VERSION ""

NS_ :

BS_:

BU_: CH DIPF DIPR ETH FC HVI HVS PARTY SDCV VEH VIRT

BO_ 1356 SCM_alertLog: 8 VEH
 SG_ SCM_a069_vStage4 m69 : 52|12@1+ (0.14652014653,0) [0|600] "V"  gtw
 SG_ SCM_a070_vStage4 m70 : 52|12@1+ (0.14652014653,0) [0|600] "V"  gtw
 SG_ SCM_a013_Ui m13 : 48|16@1- (0.0009765625,0) [-31|31] "-"  gtw
 SG_ SCM_a058_alertData3 m58 : 48|16@1- (1,0) [-32767|32767] "-"  gtw
 SG_ SCM_a067_vBat9 m67 : 40|12@1+ (0.14652014653,0) [0|600] "V"  gtw
 SG_ SCM_a075_avgDecayTime m75 : 40|16@1+ (1,0) [0|65535] "mS"  gtw
 SG_ SCM_a066_vBat6 m66 : 40|12@1+ (0.14652014653,0) [0|600] "V"  gtw
 SG_ SCM_a068_vBat12 m68 : 40|12@1+ (0.14652014653,0) [0|600] "V"  gtw
 SG_ SCM_a065_vBat3 m65 : 40|12@1+ (0.14652014653,0) [0|600] "V"  gtw
 SG_ SCM_a069_vStage3 m69 : 40|12@1+ (0.14652014653,0) [0|600] "V"  gtw
 SG_ SCM_a070_vStage3 m70 : 40|12@1+ (0.14652014653,0) [0|600] "V"  gtw
 SG_ SCM_a060_rawHvilStatus m60 : 34|30@1+ (1,0) [0|1073741823] ""  gtw
 SG_ SCM_a060_rawHvilChainNum m60 : 32|2@1+ (1,0) [0|3] ""  gtw
 SG_ SCM_a058_refVoltageLowAvg m58 : 32|16@1+ (4.574e-05,-0.006861) [-0.00686|2.99071] "V"  gtw
 SG_ SCM_a013_Up m13 : 32|16@1- (0.0009765625,0) [-31|31] "-"  gtw
 SG_ SCM_a075_chargerConfig m75 : 32|8@1+ (1,0) [0|255] ""  gtw
 SG_ SCM_a068_vBat11 m68 : 28|12@1+ (0.14652014653,0) [0|600] "V"  gtw
 SG_ SCM_a066_vBat5 m66 : 28|12@1+ (0.14652014653,0) [0|600] "V"  gtw
 SG_ SCM_a067_vBat8 m67 : 28|12@1+ (0.14652014653,0) [0|600] "V"  gtw
 SG_ SCM_a070_vStage2 m70 : 28|12@1+ (0.14652014653,0) [0|600] "V"  gtw
 SG_ SCM_a069_vStage2 m69 : 28|12@1+ (0.14652014653,0) [0|600] "V"  gtw
 SG_ SCM_a065_vBat2 m65 : 28|12@1+ (0.14652014653,0) [0|600] "V"  gtw
 SG_ SCM_a074_voltageWithoutRo m74 : 28|12@1+ (0.14652014653,0) [0|600] "V"  gtw
 SG_ SCM_a060_hvil2faultCode m60 : 28|4@1+ (1,0) [0|15] ""  gtw
 SG_ SCM_a060_hvil2chargerNum m60 : 24|4@1+ (1,0) [0|15] ""  gtw
 SG_ SCM_a083_currentLimit m83 : 20|16@1+ (0.02,0) [0|1310.7] "A"  gtw
 SG_ SCM_a060_hvil1faultCode m60 : 20|4@1+ (1,0) [0|15] ""  gtw
 SG_ SCM_a066_vBat4 m66 : 16|12@1+ (0.14652014653,0) [0|600] "V"  gtw
 SG_ SCM_a061_ServiceCode m61 : 16|3@1+ (1,0) [0|7] ""  gtw
 SG_ SCM_a079_vBat m79 : 16|12@1+ (0.14652014653,0) [0|600] "V"  gtw
 SG_ SCM_a070_vStage1 m70 : 16|12@1+ (0.14652014653,0) [0|600] "V"  gtw
 SG_ SCM_a035_vBus m35 : 16|12@1+ (0.14652014653,0) [0|600] "V"  gtw
 SG_ SCM_a069_vStage1 m69 : 16|12@1+ (0.14652014653,0) [0|600] "V"  gtw
 SG_ SCM_a013_chgIreq m13 : 16|16@1- (0.02,0) [-655|655] "A"  gtw
 SG_ SCM_a068_vBat10 m68 : 16|12@1+ (0.14652014653,0) [0|600] "V"  gtw
 SG_ SCM_a074_voltageWithRo m74 : 16|12@1+ (0.14652014653,0) [0|600] "V"  gtw
 SG_ SCM_a065_vBat1 m65 : 16|12@1+ (0.14652014653,0) [0|600] "V"  gtw
 SG_ SCM_a044_proximityV m44 : 16|16@1+ (0.0001,0) [0|6.5535] "V"  gtw
 SG_ SCM_a082_vBat m82 : 16|12@1+ (0.14652014653,0) [0|600] "V"  gtw
 SG_ SCM_a058_refVoltageHighAvg m58 : 16|16@1+ (4.574e-05,-0.006861) [-0.00686|2.99071] "V"  gtw
 SG_ SCM_a075_decayTime m75 : 16|16@1+ (1,0) [0|65535] "mS"  gtw
 SG_ SCM_a083_chargerNum m83 : 16|4@1+ (1,0) [0|15] ""  gtw
 SG_ SCM_a060_hvil1chargerNum m60 : 16|4@1+ (1,0) [0|15] ""  gtw
 SG_ SCM_a067_vBat7 m67 : 16|12@1+ (0.14652014653,0) [0|600] "V"  gtw
 SG_ SCM_a071_chargerMiaMask m71 : 16|16@1+ (1,0) [0|65535] ""  gtw
 SG_ SCM_a081_vLine m81 : 16|12@1+ (0.14652014653,0) [0|600] "V"  gtw
 SG_ SCM_a077_vBat m77 : 16|12@1+ (0.14652014653,0) [0|600] "V"  gtw
 SG_ SCM_alertType : 15|1@1+ (1,0) [0|1] ""  gtw
 SG_ SCM_alertID M : 0|15@1+ (1,0) [0|128] ""  gtw

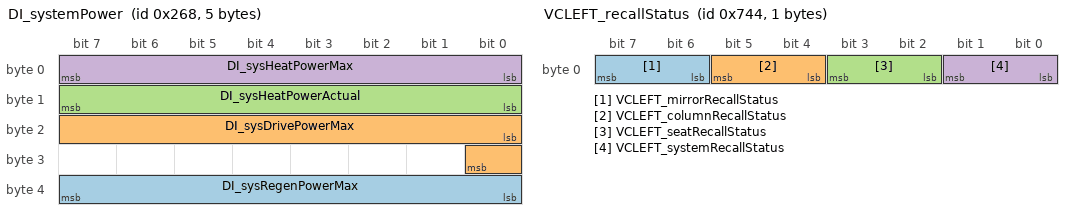
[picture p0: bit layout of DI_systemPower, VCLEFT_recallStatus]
BO_ 616 DI_systemPower: 5 VEH
 SG_ DI_sysRegenPowerMax : 32|8@1+ (1,-100) [-100|0] "kW"  gtw
 SG_ DI_sysDrivePowerMax : 16|9@1+ (1,0) [0|400] "kW"  gtw
 SG_ DI_sysHeatPowerActual : 8|8@1+ (0.08,0) [0|20] "kW"  gtw
 SG_ DI_sysHeatPowerMax : 0|8@1+ (0.08,0) [0|20] "kW"  gtw

BO_ 1874 BMS_debugInfo_100Hz: 8 VEH
 SG_ BMS_dbgVoltageReg_targetBrickV m0 : 56|8@1+ (0.0078125,2.5) [2.5|7.186927795390625] "V"  dbg
 SG_ BMS_dbgHviBusIsOff m6 : 50|1@1+ (1,0) [0|1] ""  X
 SG_ BMS_energyWalkPackSoc m4 : 48|10@1+ (0.1,0) [0|102.3] "%"  X
 SG_ BMS_dbgHviFaultConfinement m6 : 48|2@1+ (1,0) [0|2] ""  X
 SG_ BMS_energyWalkPackTemp m5 : 48|8@1- (1,40) [-40|120] "C"  X
 SG_ BMS_dbgVoltageReg_output m0 : 44|12@1- (0.5,0) [-1024|1023.5] "A"  dbg
 SG_ BMS_dbgHviRxErrorCount m6 : 40|8@1+ (1,0) [0|255] ""  X
 SG_ BMS_dbgCurrentReg_error m1 : 40|12@1- (0.1,0) [-204.8|204.7] "A"  dbg
 SG_ BMS_fcCtrCleaningNegCount m3 : 40|6@1+ (1,0) [0|50] ""  X
 SG_ BMS_energyWalkAhRemaining m4 : 35|12@1+ (0.1,0) [0|409.5] "Ah"  X
 SG_ BMS_dbgHviTxErrorCount m6 : 32|8@1+ (1,0) [0|255] ""  X
 SG_ BMS_dbgVoltageReg_error m0 : 32|12@1- (0.00122,0) [-2.49856|2.49734] "V"  dbg
 SG_ BMS_fcCtrCleaningPosCount m3 : 32|6@1+ (1,0) [0|50] ""  X
 SG_ BMS_energyWalkPackResistance m5 : 32|10@1+ (0.1,0) [0|102.3] "Ohm"  X
 SG_ BMS_dbgHvsGoToSleep m6 : 27|1@1+ (1,0) [0|1] ""  X
 SG_ BMS_dbgHvsBusIsOff m6 : 26|1@1+ (1,0) [0|1] ""  X
 SG_ BMS_fcCtrCleaningActive m3 : 26|1@1+ (1,0) [0|1] ""  X
 SG_ BMS_fcCtrCleaningAllowed m3 : 25|1@1+ (1,0) [0|1] ""  X
 SG_ BMS_dbgHvsFaultConfinement m6 : 24|2@1+ (1,0) [0|2] ""  X
 SG_ BMS_walkEnergy m4 : 24|11@1+ (0.1,0) [0|204.7] "kWh"  X
 SG_ BMS_fcCtrCleaningDesired m3 : 24|1@1+ (1,0) [0|1] ""  X
 SG_ BMS_dbgCurrentReg_outProp m1 : 24|14@1- (0.1,0) [-819.2|819.1] "A"  dbg
 SG_ BMS_smHvUpRequestAllowed m3 : 23|1@1+ (1,0) [0|1] ""  X
 SG_ BMS_minTetheredLoadPresent m3 : 22|1@1+ (1,0) [0|1] ""  X
 SG_ BMS_dbgVoltageReg_Ki m0 : 20|12@1- (0.0265625,0) [0|54.4] "A/V"  dbg
 SG_ BMS_fcLinkLeakageTestStatus m3 : 19|3@1+ (1,0) [0|4] ""  X
 SG_ BMS_dbgEnoughPowerForSupport m3 : 18|1@1+ (1,0) [0|1] ""  X
 SG_ BMS_dbgUdsCtrControlActive m3 : 17|1@1+ (1,0) [0|1] ""  X
 SG_ BMS_energyWalkPackCurrent m5 : 17|15@1- (0.1,1000) [-638.3|2638.4] "A"  X
 SG_ BMS_dbgFeimBlocking m3 : 16|1@1+ (1,0) [0|1] ""  X
 SG_ BMS_dbgHvsRxErrorCount m6 : 16|8@1+ (1,0) [0|255] ""  X
 SG_ BMS_dbgSmDriveActive m3 : 15|1@1+ (1,0) [0|1] ""  X
 SG_ BMS_dbgSmStateSupportRequired m3 : 14|1@1+ (1,0) [0|1] ""  X
 SG_ BMS_energyWalkTime m4 : 13|10@1+ (0.01,0) [0|10.23] "hours"  X
 SG_ BMS_dbgChargeNeeded m3 : 13|1@1+ (1,0) [0|1] ""  dbg
 SG_ BMS_energyWalkId m4 : 10|3@1+ (1,0) [0|4] ""  dbg
 SG_ BMS_energyWalkTimedOut m4 : 9|1@1+ (1,0) [0|1] ""  X
 SG_ BMS_dbgChargeState m3 : 9|4@1+ (1,0) [0|15] ""  dbg
 SG_ BMS_dbgHvsTxErrorCount m6 : 8|8@1+ (1,0) [0|255] ""  X
 SG_ BMS_energyWalkLoadedPackV m5 : 8|9@1+ (1,0) [0|430] "V"  X
 SG_ BMS_energyWalkDone m4 : 8|1@1+ (1,0) [0|1] ""  X
 SG_ BMS_dbgVoltageReg_Kp m0 : 8|12@1- (1.2,0) [0|2400] "V/A"  dbg
 SG_ BMS_dbgCurrentReg_outIntegral m1 : 8|14@1- (0.1,0) [-819.2|819.1] "A"  dbg
 SG_ BMS_dbgSmChargeCablePresent m3 : 8|1@1+ (1,0) [0|1] ""  X
 SG_ BMS_dbgSmBmsWantsToCharge m3 : 7|1@1+ (1,0) [0|1] ""  dbg
 SG_ BMS_energyTargetReached m4 : 7|1@1+ (1,0) [0|1] ""  X
 SG_ BMS_dbgSmChargerActive m3 : 6|1@1+ (1,0) [0|1] ""  X
 SG_ BMS_energyNotEnoughPower m4 : 6|1@1+ (1,0) [0|1] ""  X
 SG_ BMS_dbgSmChargeRequestActive m3 : 5|1@1+ (1,0) [0|1] ""  X
 SG_ BMS_energySocLimitReached m4 : 5|1@1+ (1,0) [0|1] ""  X
 SG_ BMS_energyPowerTargetReached m4 : 4|1@1+ (1,0) [0|1] ""  X
 SG_ BMS_dbgSmChgModuleBlockingTrans m3 : 4|1@1+ (1,0) [0|1] ""  X
 SG_ BMS_dbgSmWeldRequest m3 : 3|1@1+ (1,0) [0|1] ""  X
 SG_ BMS_energyVoltageFloorReached m4 : 3|1@1+ (1,0) [0|1] ""  X
 SG_ BMS_100HzDebug_Id M : 0|3@1+ (1,0) [0|7] ""  X

BO_ 2005 DIS_debug: 8 VEH
 SG_ DIS_brakeSwitchNC m42 : 63|1@1+ (1,0) [0|1] ""  dbg
 SG_ DIS_brakeSwitchNO m42 : 62|1@1+ (1,0) [0|1] ""  dbg
 SG_ DIS_module10HzStack m66 : 56|8@1+ (0.4,0) [0|100] "%"  X
 SG_ DIS_posDcBusbarTemp m70 : 56|8@1+ (1,-40) [-40|215] "DegC"  gtw
 SG_ DIS_pwrSatMinBusVoltage m39 : 56|8@1+ (0.4,0) [0|102] "%"  dbg
 SG_ DIS_controlStack m67 : 56|8@1+ (0.4,0) [0|100] "%"  dbg
 SG_ DIS_tqScaleShift m40 : 56|8@1+ (0.4,0) [0|102] "%"  dbg
 SG_ DIS_magnetTempEst m47 : 48|8@1+ (1,-40) [-40|180] "DegC"  X
 SG_ DIS_negDcBusbarTemp m70 : 48|8@1+ (1,-40) [-40|215] "DegC"  gtw
 SG_ DIS_systemTorqueCommand m35 : 48|16@1- (0.035,0.0) [-1146.88|1146.845] "Nm"  dbg
 SG_ DIS_internalAngleFilt m37 : 48|16@1+ (0.0003,0) [0|8] "rad"  dbg
 SG_ DIS_motorIC m32 : 48|16@1+ (0.1,0) [0|6553.5] "A"  dbg
 SG_ DIS_cpu20kHzAvg m67 : 48|8@1+ (0.4,0) [0|102] "%"  dbg
 SG_ DIS_xcpStack m68 : 48|8@1+ (0.4,0) [0|100] "%"  dbg
 SG_ DIS_peakFlux m36 : 48|16@1+ (0.0001,0) [0|6.5535] "Wb"  dbg
 SG_ DIS_motorIBavg m38 : 48|16@1- (0.1,0) [-3276.8|3276.7] "A"  dbg
 SG_ DIS_wasteCurrentLimit m41 : 48|16@1+ (0.1,0) [0|6553.5] "A"  dbg
 SG_ DIS_resolverErrorRmsSquared m52 : 48|8@1+ (0.005,0) [0|1] "1"  X
 SG_ DIS_soptMaxCurrentMagSqrd m49 : 48|16@1+ (100,0) [0|6553500] "A2"  X
 SG_ DIS_pwrSatMaxBusVoltage m39 : 48|8@1+ (0.4,0) [0|102] "%"  dbg
 SG_ DIS_torquePerAmp m33 : 48|16@1+ (0.0001,0) [0|6.5535] "Nm/A"  dbg
 SG_ DIS_cpuIDWord3 m132 : 48|16@1+ (1,0) [0|65535] ""  dbg
 SG_ DIS_tqScaleMaxMotorSpeed m40 : 48|8@1+ (0.4,0) [0|102] "%"  dbg
 SG_ DIS_cpu100HzAvg m66 : 48|8@1+ (0.4,0) [0|102] "%"  dbg
 SG_ DIS_motorV m34 : 48|16@1+ (2e-05,0) [0|1.3107] "mindex"  dbg
 SG_ DIS_resolverClaMIA m48 : 43|1@1+ (1,0) [0|1] ""  X
 SG_ DIS_resolverNoPhaseLock m48 : 42|1@1+ (1,0) [0|1] ""  X
 SG_ DIS_resolverNoCarrier m48 : 41|1@1+ (1,0) [0|1] ""  X
 SG_ DIS_cpu20kHzMax m67 : 40|8@1+ (0.4,0) [0|102] "%"  dbg
 SG_ DIS_statorTemp2 m64 : 40|8@1+ (1,-40) [-40|215] "DegC"  dbg
 SG_ DIS_hvDcCableTemp m70 : 40|8@1+ (1,-40) [-40|215] "DegC"  gtw
 SG_ DIS_resolverReady m48 : 40|1@1+ (1,0) [0|1] ""  X
 SG_ DIS_loadAngle m42 : 40|16@1- (0.0003,0.0) [-4|4] "rad"  X
 SG_ DIS_cpu100HzMax m66 : 40|8@1+ (0.4,0) [0|102] "%"  dbg
 SG_ DIS_tqSatMotorCurrent m39 : 40|8@1+ (0.4,0) [0|102] "%"  dbg
 SG_ DIS_udsStack m68 : 40|8@1+ (0.4,0) [0|100] "%"  dbg
 SG_ DIS_tqSatUiRegenTorque m40 : 40|8@1+ (0.4,0) [0|102] "%"  dbg
 SG_ DIS_resolverSinFiltered m52 : 40|8@1- (0.01,0.0) [-1|1] "1"  X
 SG_ DIS_statorFluxFdb m35 : 32|16@1+ (0.0001,0) [0|6.5535] "Wb"  dbg
 SG_ DIS_motorIB m32 : 32|16@1+ (0.1,0) [0|6553.5] "A"  dbg
 SG_ DIS_cpu20kHzMin m67 : 32|8@1+ (0.4,0) [0|102] "%"  dbg
 SG_ DIS_cpuIDWord2 m132 : 32|16@1+ (1,0) [0|65535] ""  dbg
 SG_ DIS_statorIDfdb m33 : 32|16@1- (0.1,0.0) [-3276.8|3276.7] "A"  dbg
 SG_ DIS_tqSatMotorVoltage m39 : 32|8@1+ (0.4,0) [0|102] "%"  dbg
 SG_ DIS_crc m131 : 32|32@1+ (1,0) [0|4294967295] ""  dbg
 SG_ DIS_soptTimeToOff m49 : 32|11@1+ (0.05,0) [0|100] "ms"  X
 SG_ DIS_currentLimit m41 : 32|16@1+ (0.1,0) [0|6553.5] "A"  dbg
 SG_ DIS_dcCableHeat m47 : 32|16@1+ (0.001,0) [0|65.535] "kA2s"  X
 SG_ DIS_driveUnitOdometer m69 : 32|32@1+ (10,0) [0|42949672950] "rev"  X
 SG_ DIS_resolverCosFiltered m52 : 32|8@1- (0.01,0.0) [-1|1] "1"  X
 SG_ DIS_statorIQfdb m34 : 32|16@1- (0.1,0.0) [-3276.8|3276.7] "A"  dbg
 SG_ DIS_hvilCmVoltage m65 : 32|10@1+ (0.02,0) [0|20.46] "V"  dbg
 SG_ DIS_cpu100HzMin m66 : 32|8@1+ (0.4,0) [0|102] "%"  dbg
 SG_ DIS_resolverCommonGain m48 : 32|8@1+ (0.025,0) [0|5] "1"  X
 SG_ DIS_llrScale m42 : 32|8@1+ (0.015,0) [0|3.825] "scale"  dbg
 SG_ DIS_statorTemp1 m64 : 32|8@1+ (1,-40) [-40|215] "DegC"  dbg
 SG_ DIS_loadAngleMargin m37 : 32|16@1- (0.0003,0.0) [-4|4] "rad"  dbg
 SG_ DIS_dcLinkCapTemp m70 : 32|8@1+ (1,-40) [-40|215] "DegC"  gtw
 SG_ DIS_oilPumpPressureEstimate m46 : 32|8@1+ (2,0) [0|500] "kPa"  dbg
 SG_ DIS_tqSatUiDriveTorque m40 : 32|8@1+ (0.4,0) [0|102] "%"  dbg
 SG_ DIS_motorIAavg m38 : 32|16@1- (0.1,0) [-3276.8|3276.7] "A"  dbg
 SG_ DIS_eepromStack m68 : 32|8@1+ (0.4,0) [0|100] "%"  dbg
 SG_ DIS_cpu1HzAvg m128 : 32|8@1+ (0.4,0) [0|102] "%"  dbg
 SG_ DIS_statorVD m36 : 32|16@1- (4e-05,0.0) [-1.31072|1.31068] "mindex"  dbg
 SG_ DIS_oilPumpPhaseAdvance m46 : 24|8@1+ (0.4,0) [0|100] "%"  dbg
 SG_ DIS_tcMinRequest m40 : 24|8@1+ (5,0) [0|1275] "Nm"  dbg
 SG_ DIS_decodeHardwareStack m68 : 24|8@1+ (0.4,0) [0|100] "%"  dbg
 SG_ DIS_phaseOutLugTemp m70 : 24|8@1+ (1,-40) [-40|215] "DegC"  gtw
 SG_ DIS_llsScale m42 : 24|8@1+ (0.004,0) [0|1.02] "scale"  dbg
 SG_ DIS_resolverSinRmsSquared m52 : 24|8@1+ (0.005,0) [0|1] "1"  X
 SG_ DIS_pwrSatMaxRegenPower m39 : 24|8@1+ (0.4,0) [0|102] "%"  dbg
 SG_ DIS_cpu1kHzAvg m67 : 24|8@1+ (0.4,0) [0|102] "%"  dbg
 SG_ DIS_cpu1HzMax m128 : 24|8@1+ (0.4,0) [0|102] "%"  dbg
 SG_ DIS_resolverPhaseOffset m48 : 24|8@1+ (0.1,7.5) [7.5|32.5] "us"  X
 SG_ DIS_pcsTemp m64 : 24|8@1+ (1,-40) [-40|215] "DegC"  dbg
 SG_ DIS_cpu10HzAvg m66 : 24|8@1+ (0.4,0) [0|102] "%"  dbg
 SG_ DIS_resolverCosRmsSquared m52 : 16|8@1+ (0.005,0) [0|1] "1"  X
 SG_ DIS_rotorMaxMagnetTemp m72 : 16|8@1+ (1,-40) [-40|215] "DegC"  gtw
 SG_ DIS_statorVQ m36 : 16|16@1- (4e-05,0.0) [-1.31072|1.31068] "mindex"  dbg
 SG_ DIS_phaseOutBusbarWeldTemp m70 : 16|8@1+ (1,-40) [-40|215] "DegC"  gtw
 SG_ DIS_cpu1kHzMax m67 : 16|8@1+ (0.4,0) [0|102] "%"  dbg
 SG_ DIS_busbarTemp m64 : 16|8@1+ (1,-40) [-40|215] "DegC"  dbg
 SG_ DIS_cpuIDWord1 m132 : 16|16@1+ (1,0) [0|65535] ""  dbg
 SG_ DIS_pwrSatMaxDischargePower m39 : 16|8@1+ (0.4,0) [0|102] "%"  dbg
 SG_ DIS_cpuIDWord0 m131 : 16|16@1+ (1,0) [0|65535] ""  dbg
 SG_ DIS_fluxState m42 : 16|4@1+ (1,0) [0|9] ""  dbg
 SG_ DIS_cpu1HzMin m128 : 16|8@1+ (0.4,0) [0|102] "%"  dbg
 SG_ DIS_resolverOffsetSin m48 : 16|8@1+ (0.015,0) [0|3.3] "V"  X
 SG_ DIS_oilPumpPhaseVoltage m46 : 16|8@1+ (0.1,0) [0|25.4] "V"  dbg
 SG_ DIS_tcMaxRequest m40 : 16|8@1+ (5,0) [0|1275] "Nm"  dbg
 SG_ DIS_soptTripDelay m49 : 16|8@1+ (0.05,0) [0|10] "ms"  X
 SG_ DIS_hvilCurrent m65 : 16|10@1+ (0.025,0) [0|25.575] "mA"  dbg
 SG_ DIS_idleStack m68 : 16|8@1+ (0.4,0) [0|100] "%"  dbg
 SG_ DIS_statorFluxRef m35 : 16|16@1+ (0.0001,0) [0|6.5535] "Wb"  dbg
 SG_ DIS_cpu10HzMax m66 : 16|8@1+ (0.4,0) [0|102] "%"  dbg
 SG_ DIS_statorIDref m33 : 16|16@1- (0.1,0.0) [-3276.8|3276.7] "A"  dbg
 SG_ DIS_rotorFlux m47 : 16|16@1+ (0.0001,0) [0|6.5535] "Wb"  X
 SG_ DIS_motorIA m32 : 16|16@1+ (0.1,0) [0|6553.5] "A"  dbg
 SG_ DIS_statorIQref m34 : 16|16@1- (0.1,0.0) [-3276.8|3276.7] "A"  dbg
 SG_ DIS_peakIQref m38 : 16|16@1+ (0.1,0) [0|6553.5] "A"  dbg
 SG_ DIS_dcCableCurrentEst m37 : 16|16@1- (0.1,0.0) [-3276.8|3276.7] "A"  dbg
 SG_ DIS_powerStageSafeState m50 : 13|2@1+ (1,0) [0|3] ""  X
 SG_ DIS_usmState m38 : 12|3@1+ (1,0) [0|7] ""  dbg
 SG_ DIS_gateDriveState m50 : 10|3@1+ (1,0) [0|4] ""  X
 SG_ DIS_offsetB m33 : 8|8@1- (0.1,0.0) [-12.8|12.7] "A"  dbg
 SG_ DIS_lmScale m36 : 8|8@1+ (0.004,0) [0|1.02] "scale"  dbg
 SG_ DIS_gainScale m37 : 8|8@1+ (0.01,0) [0|2.55] "scale"  dbg
 SG_ DIS_rsScale m34 : 8|8@1+ (0.01,0) [0|2.55] "scale"  dbg
 SG_ DIS_soptTimeToTrip m49 : 8|8@1+ (0.05,0) [0|10] "ms"  X
 SG_ DIS_resolverOffsetCos m48 : 8|8@1+ (0.015,0) [0|3.3] "V"  X
 SG_ DIS_offsetA m32 : 8|8@1- (0.1,0.0) [-12.8|12.7] "A"  dbg
 SG_ DIS_tqScaleDifferential m35 : 8|8@1+ (0.4,0) [0|102] "%"  dbg
 SG_ DIS_systemStack m68 : 8|8@1+ (0.4,0) [0|100] "%"  dbg
 SG_ DIS_motorType m128 : 8|5@1+ (1,0) [0|25] ""  dbg
 SG_ DIS_velocityEstimatorState m65 : 8|3@1+ (1,0) [0|4] ""  dbg
 SG_ DIS_pwrSatChargeCurrent m42 : 8|8@1+ (0.4,0) [0|102] "%"  dbg
 SG_ DIS_statorEndWindingTemp m72 : 8|8@1+ (1,-40) [-40|215] "DegC"  gtw
 SG_ DIS_phaseOutBusbarTemp m70 : 8|8@1+ (1,-40) [-40|215] "DegC"  gtw
 SG_ DIS_tqSatThermal m39 : 8|8@1+ (0.4,0) [0|102] "%"  dbg
 SG_ DIS_gateDriveSupplyState m50 : 8|2@1+ (1,0) [0|3] ""  X
 SG_ DIS_cpu10HzMin m66 : 8|8@1+ (0.4,0) [0|102] "%"  dbg
 SG_ DIS_hwFaultCounter m69 : 8|4@1+ (1,0) [0|15] ""  X
 SG_ DIS_dcCapTemp m64 : 8|8@1+ (1,-40) [-40|215] "DegC"  dbg
 SG_ DIS_oilPumpPhaseCurrent m46 : 8|8@1+ (0.1,0) [0|25.4] "A"  dbg
 SG_ DIS_cpu1kHzMin m67 : 8|8@1+ (0.4,0) [0|102] "%"  dbg
 SG_ DIS_pwrSatDischargeCurrent m40 : 8|8@1+ (0.4,0) [0|102] "%"  dbg
 SG_ DIS_debugSelector M : 0|8@1+ (1,0) [0|255] ""  dbg

BO_ 1553 HVP_udsResponse: 8 VEH
 SG_ HVP_udsResponseData : 7|64@0+ (1,0) [0|18446744073709551615] ""  gtw

BO_ 1860 VCLEFT_recallStatus: 1 VEH
 SG_ VCLEFT_mirrorRecallStatus : 6|2@1+ (1,0) [0|3] ""  gtw
 SG_ VCLEFT_columnRecallStatus : 4|2@1+ (1,0) [0|3] ""  gtw
 SG_ VCLEFT_seatRecallStatus : 2|2@1+ (1,0) [0|3] ""  gtw
 SG_ VCLEFT_systemRecallStatus : 0|2@1+ (1,0) [0|3] ""  gtw

BO_ 1345 FC_maxLimits: 8 VEH
 SG_ FC_maxCurrentLimit : 16|13@1+ (0.0732421875,0) [0|599.92675781] "A"  gtw
 SG_ FC_maxPowerLimit : 0|13@1+ (0.062255859376,0) [0|509.93774415] "kW"  dbg

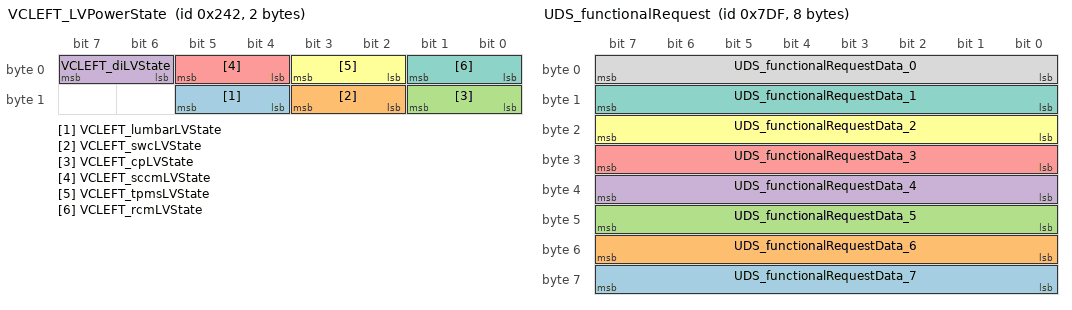
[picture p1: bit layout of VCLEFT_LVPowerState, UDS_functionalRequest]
BO_ 578 VCLEFT_LVPowerState: 2 VEH
 SG_ VCLEFT_lumbarLVState : 12|2@1+ (1,0) [0|3] ""  gtw
 SG_ VCLEFT_swcLVState : 10|2@1+ (1,0) [0|3] ""  X
 SG_ VCLEFT_cpLVState : 8|2@1+ (1,0) [0|3] ""  vcfront
 SG_ VCLEFT_diLVState : 6|2@1+ (1,0) [0|3] ""  gtw
 SG_ VCLEFT_sccmLVState : 4|2@1+ (1,0) [0|3] ""  X
 SG_ VCLEFT_tpmsLVState : 2|2@1+ (1,0) [0|3] ""  gtw
 SG_ VCLEFT_rcmLVState : 0|2@1+ (1,0) [0|3] ""  X

BO_ 1879 DI_debug: 8 VEH
 SG_ DI_brakeSwitchNC m42 : 63|1@1+ (1,0) [0|1] ""  dbg
 SG_ DI_immobilizerCondition m64 : 63|1@1+ (1,0) [0|1] ""  dbg
 SG_ DI_brakeSwitchNO m42 : 62|1@1+ (1,0) [0|1] ""  dbg
 SG_ DI_immobilizerStack m68 : 56|8@1+ (0.4,0) [0|100] "%"  dbg
 SG_ DI_controlStack m67 : 56|8@1+ (0.4,0) [0|100] "%"  dbg
 SG_ DI_posDcBusbarTemp m70 : 56|8@1+ (1,-40) [-40|215] "DegC"  gtw
 SG_ DI_pwrSatMinBusVoltage m39 : 56|8@1+ (0.4,0) [0|102] "%"  dbg
 SG_ DI_magnetTempEst_SFO m47 : 56|8@1+ (1,-40) [-40|180] "DegC"  X
 SG_ DI_tqScaleShift m40 : 56|8@1+ (0.4,0) [0|102] "%"  dbg
 SG_ DI_module10HzStack m66 : 56|8@1+ (0.4,0) [0|100] "%"  X
 SG_ DI_torquePostPedalMax m51 : 52|12@1+ (2,0) [0|7500] "Nm"  X
 SG_ DI_sysPostPedalMaxTorque m44 : 50|14@1+ (0.1,0) [0|1638.3] "Nm"  dbg
 SG_ DI_torquePerAmp m33 : 48|16@1+ (0.0001,0) [0|6.5535] "Nm/A"  dbg
 SG_ DI_internalAngleFilt m37 : 48|16@1+ (0.0003,0) [0|8] "rad"  dbg
 SG_ DI_motorIC m32 : 48|16@1+ (0.1,0) [0|6553.5] "A"  dbg
 SG_ DI_systemTorqueCommand m35 : 48|16@1- (0.035,0.0) [-1146.88|1146.845] "Nm"  dbg
 SG_ DI_negDcBusbarTemp m70 : 48|8@1+ (1,-40) [-40|215] "DegC"  gtw
 SG_ DI_magnetTempEst m47 : 48|8@1+ (1,-40) [-40|180] "DegC"  X
 SG_ DI_resolverErrorRmsSquared m52 : 48|8@1+ (0.005,0) [0|1] "1"  X
 SG_ DI_peakFlux m36 : 48|16@1+ (0.0001,0) [0|6.5535] "Wb"  dbg
 SG_ DI_motorIBavg m38 : 48|16@1- (0.1,0) [-3276.8|3276.7] "A"  dbg
 SG_ DI_cpu20kHzAvg m67 : 48|8@1+ (0.4,0) [0|102] "%"  dbg
 SG_ DI_motorV m34 : 48|16@1+ (2e-05,0) [0|1.3107] "mindex"  dbg
 SG_ DI_tqScaleMaxMotorSpeed m40 : 48|8@1+ (0.4,0) [0|102] "%"  dbg
 SG_ DI_cpuIDWord3 m132 : 48|16@1+ (1,0) [0|65535] ""  dbg
 SG_ DI_pwrSatMaxBusVoltage m39 : 48|8@1+ (0.4,0) [0|102] "%"  dbg
 SG_ DI_wasteCurrentLimit m41 : 48|16@1+ (0.1,0) [0|6553.5] "A"  dbg
 SG_ DI_cpu100HzAvg m66 : 48|8@1+ (0.4,0) [0|102] "%"  dbg
 SG_ DI_xcpStack m68 : 48|8@1+ (0.4,0) [0|100] "%"  dbg
 SG_ DI_resolverClaMIA m48 : 43|1@1+ (1,0) [0|1] ""  X
 SG_ DI_resolverNoPhaseLock m48 : 42|1@1+ (1,0) [0|1] ""  X
 SG_ DI_resolverNoCarrier m48 : 41|1@1+ (1,0) [0|1] ""  X
 SG_ DI_cpu20kHzMax m67 : 40|8@1+ (0.4,0) [0|102] "%"  dbg
 SG_ DI_statorTemp2 m64 : 40|8@1+ (1,-40) [-40|215] "DegC"  dbg
 SG_ DI_loadAngle m42 : 40|16@1- (0.0003,0.0) [-4|4] "rad"  X
 SG_ DI_resolverReady m48 : 40|1@1+ (1,0) [0|1] ""  X
 SG_ DI_torquePostPedalMin m51 : 40|12@1+ (2,-7500) [-7500|0] "Nm"  X
 SG_ DI_resolverSinFiltered m52 : 40|8@1- (0.01,0.0) [-1|1] "1"  X
 SG_ DI_udsStack m68 : 40|8@1+ (0.4,0) [0|100] "%"  dbg
 SG_ DI_hvDcCableTemp m70 : 40|8@1+ (1,-40) [-40|215] "DegC"  gtw
 SG_ DI_tqSatUiRegenTorque m40 : 40|8@1+ (0.4,0) [0|102] "%"  dbg
 SG_ DI_tqSatMotorCurrent m39 : 40|8@1+ (0.4,0) [0|102] "%"  dbg
 SG_ DI_cpu100HzMax m66 : 40|8@1+ (0.4,0) [0|102] "%"  dbg
 SG_ DI_soptMaxCurrentMagSqrd m49 : 40|16@1+ (100,0) [0|6553500] "A2"  gtw
 SG_ DI_sysPostPedalMinTorque m44 : 36|14@1+ (0.1,-1638.3) [-1638.3|0] "Nm"  dbg
 SG_ DI_motorIAavg m38 : 32|16@1- (0.1,0) [-3276.8|3276.7] "A"  dbg
 SG_ DI_tqSatUiDriveTorque m40 : 32|8@1+ (0.4,0) [0|102] "%"  dbg
 SG_ DI_currentLimit m41 : 32|16@1+ (0.1,0) [0|6553.5] "A"  dbg
 SG_ DI_aebCancelReason m45 : 32|8@1+ (1,0) [0|255] ""  dbg
 SG_ DI_statorIDfdb m33 : 32|16@1- (0.1,0.0) [-3276.8|3276.7] "A"  dbg
 SG_ DI_crc m131 : 32|32@1+ (1,0) [0|4294967295] ""  dbg
 SG_ DI_llrScale m42 : 32|8@1+ (0.015,0) [0|3.825] "scale"  dbg
 SG_ DI_resolverCommonGain m48 : 32|8@1+ (0.025,0) [0|5] "1"  X
 SG_ DI_tqSatMotorVoltage m39 : 32|8@1+ (0.4,0) [0|102] "%"  dbg
 SG_ DI_statorIQfdb m34 : 32|16@1- (0.1,0.0) [-3276.8|3276.7] "A"  dbg
 SG_ DI_pedalPosFilt m2 : 32|8@1+ (0.4,0) [0|100] "%"  dbg
 SG_ DI_hvilCmVoltage m65 : 32|10@1+ (0.02,0) [0|20.46] "V"  dbg
 SG_ DI_cpu100HzMin m66 : 32|8@1+ (0.4,0) [0|102] "%"  dbg
 SG_ DI_cpuIDWord2 m132 : 32|16@1+ (1,0) [0|65535] ""  dbg
 SG_ DI_motorIB m32 : 32|16@1+ (0.1,0) [0|6553.5] "A"  dbg
 SG_ DI_statorFluxFdb m35 : 32|16@1+ (0.0001,0) [0|6.5535] "Wb"  dbg
 SG_ DI_statorVD m36 : 32|16@1- (4e-05,0.0) [-1.31072|1.31068] "mindex"  dbg
 SG_ DI_driveUnitOdometer m69 : 32|32@1+ (10,0) [0|42949672950] "rev"  X
 SG_ DI_dcCableHeat m47 : 32|16@1+ (0.001,0) [0|65.535] "kA2s"  X
 SG_ DI_statorVQFiltered m63 : 32|16@1- (4e-05,0.0) [-1.31072|1.31068] "mindex"  X
 SG_ DI_loadAngleMargin m37 : 32|16@1- (0.0003,0.0) [-4|4] "rad"  dbg
 SG_ DI_oilPumpPressureEstimate m46 : 32|8@1+ (2,0) [0|500] "kPa"  dbg
 SG_ DI_dcLinkCapTemp m70 : 32|8@1+ (1,-40) [-40|215] "DegC"  gtw
 SG_ DI_statorTemp1 m64 : 32|8@1+ (1,-40) [-40|215] "DegC"  dbg
 SG_ DI_cpu20kHzMin m67 : 32|8@1+ (0.4,0) [0|102] "%"  dbg
 SG_ DI_resolverCosFiltered m52 : 32|8@1- (0.01,0.0) [-1|1] "1"  X
 SG_ DI_cpu1HzAvg m128 : 32|8@1+ (0.4,0) [0|102] "%"  dbg
 SG_ DI_eepromStack m68 : 32|8@1+ (0.4,0) [0|100] "%"  dbg
 SG_ DI_torquePedalMax m51 : 28|12@1+ (2,0) [0|7500] "Nm"  X
 SG_ DI_pwrSatMaxRegenPower m39 : 24|8@1+ (0.4,0) [0|102] "%"  dbg
 SG_ DI_resolverSinRmsSquared m52 : 24|8@1+ (0.005,0) [0|1] "1"  X
 SG_ DI_brkStState m50 : 24|3@1+ (1,0) [0|6] ""  X
 SG_ DI_phaseOutLugTemp m70 : 24|8@1+ (1,-40) [-40|215] "DegC"  gtw
 SG_ DI_resolverPhaseOffset m48 : 24|8@1+ (0.1,7.5) [7.5|32.5] "us"  X
 SG_ DI_pcsTemp m64 : 24|8@1+ (1,-40) [-40|215] "DegC"  dbg
 SG_ DI_tcMinRequest m40 : 24|8@1+ (5,0) [0|1275] "Nm"  dbg
 SG_ DI_soptTimeToOff m49 : 24|11@1+ (0.05,0) [0|100] "ms"  gtw
 SG_ DI_aebUnavailableReason m45 : 24|4@1+ (1,0) [0|9] ""  dbg
 SG_ DI_cpu10HzAvg m66 : 24|8@1+ (0.4,0) [0|102] "%"  dbg
 SG_ DI_llsScale m42 : 24|8@1+ (0.004,0) [0|1.02] "scale"  dbg
 SG_ DI_decodeHardwareStack m68 : 24|8@1+ (0.4,0) [0|100] "%"  dbg
 SG_ DI_cpu1HzMax m128 : 24|8@1+ (0.4,0) [0|102] "%"  dbg
 SG_ DI_oilPumpPhaseAdvance m46 : 24|8@1+ (0.4,0) [0|100] "%"  dbg
 SG_ DI_cpu1kHzAvg m67 : 24|8@1+ (0.4,0) [0|102] "%"  dbg
 SG_ DI_sysPedalMaxTorque m44 : 22|14@1+ (0.1,0) [0|1638.3] "Nm"  dbg
 SG_ DI_veResForce m41 : 20|12@1- (0.0005,0) [-1.024|1.0235] "G"  dbg
 SG_ DI_cpuIDWord1 m132 : 16|16@1+ (1,0) [0|65535] ""  dbg
 SG_ DI_brakeCpScale m2 : 16|9@1- (0.01,0.5) [-1|2] "N/N"  dbg
 SG_ DI_cpu10HzMax m66 : 16|8@1+ (0.4,0) [0|102] "%"  dbg
 SG_ DI_tcMaxRequest m40 : 16|8@1+ (5,0) [0|1275] "Nm"  dbg
 SG_ DI_resolverOffsetSin m48 : 16|8@1+ (0.015,0) [0|3.3] "V"  X
 SG_ DI_cpu1HzMin m128 : 16|8@1+ (0.4,0) [0|102] "%"  dbg
 SG_ DI_oilPumpPhaseVoltage m46 : 16|8@1+ (0.1,0) [0|25.4] "V"  dbg
 SG_ DI_resolverCosRmsSquared m52 : 16|8@1+ (0.005,0) [0|1] "1"  X
 SG_ DI_aebFaultReason m45 : 16|4@1+ (1,0) [0|15] ""  dbg
 SG_ DI_torquePedalMin m51 : 16|12@1+ (2,-7500) [-7500|0] "Nm"  X
 SG_ DI_statorIDref m33 : 16|16@1- (0.1,0.0) [-3276.8|3276.7] "A"  dbg
 SG_ DI_rotorFlux m47 : 16|16@1+ (0.0001,0) [0|6.5535] "Wb"  X
 SG_ DI_motorIA m32 : 16|16@1+ (0.1,0) [0|6553.5] "A"  dbg
 SG_ DI_statorVDFiltered m63 : 16|16@1- (4e-05,0.0) [-1.31072|1.31068] "mindex"  X
 SG_ DI_pwrSatMaxDischargePower m39 : 16|8@1+ (0.4,0) [0|102] "%"  dbg
 SG_ DI_sysHeatPowerOptimal m50 : 16|8@1+ (0.08,0) [0|20] "kW"  gtw
 SG_ DI_busbarTemp m64 : 16|8@1+ (1,-40) [-40|215] "DegC"  dbg
 SG_ DI_statorFluxRef m35 : 16|16@1+ (0.0001,0) [0|6.5535] "Wb"  dbg
 SG_ DI_soptTripDelay m49 : 16|8@1+ (0.05,0) [0|10] "ms"  gtw
 SG_ DI_idleStack m68 : 16|8@1+ (0.4,0) [0|100] "%"  dbg
 SG_ DI_hvilCurrent m65 : 16|10@1+ (0.025,0) [0|25.575] "mA"  dbg
 SG_ DI_cpu1kHzMax m67 : 16|8@1+ (0.4,0) [0|102] "%"  dbg
 SG_ DI_phaseOutBusbarWeldTemp m70 : 16|8@1+ (1,-40) [-40|215] "DegC"  gtw
 SG_ DI_statorVQ m36 : 16|16@1- (4e-05,0.0) [-1.31072|1.31068] "mindex"  dbg
 SG_ DI_fluxState m42 : 16|4@1+ (1,0) [0|9] ""  dbg
 SG_ DI_rotorMaxMagnetTemp m72 : 16|8@1+ (1,-40) [-40|215] "DegC"  gtw
 SG_ DI_dcCableCurrentEst m37 : 16|16@1- (0.1,0.0) [-3276.8|3276.7] "A"  dbg
 SG_ DI_cpuIDWord0 m131 : 16|16@1+ (1,0) [0|65535] ""  dbg
 SG_ DI_statorIQref m34 : 16|16@1- (0.1,0.0) [-3276.8|3276.7] "A"  dbg
 SG_ DI_peakIQref m38 : 16|16@1+ (0.1,0) [0|6553.5] "A"  dbg
 SG_ DI_powerStageSafeState m50 : 13|2@1+ (1,0) [0|3] ""  X
 SG_ DI_usmState m38 : 12|3@1+ (1,0) [0|7] ""  dbg
 SG_ DI_gateDriveState m50 : 10|3@1+ (1,0) [0|4] ""  X
 SG_ DI_systemStack m68 : 8|8@1+ (0.4,0) [0|100] "%"  dbg
 SG_ DI_motorType m128 : 8|5@1+ (1,0) [0|25] ""  dbg
 SG_ DI_muSurfHigh m2 : 8|8@1+ (0.005,0) [0|1.2] "N/N"  dbg
 SG_ DI_oilPumpPhaseCurrent m46 : 8|8@1+ (0.1,0) [0|25.4] "A"  dbg
 SG_ DI_rsScale m34 : 8|8@1+ (0.01,0) [0|2.55] "scale"  dbg
 SG_ DI_lmScale m36 : 8|8@1+ (0.004,0) [0|1.02] "scale"  dbg
 SG_ DI_gainScale m37 : 8|8@1+ (0.01,0) [0|2.55] "scale"  dbg
 SG_ DI_hwFaultCounter m69 : 8|4@1+ (1,0) [0|15] ""  X
 SG_ DI_sysPedalMinTorque m44 : 8|14@1+ (0.1,-1638.3) [-1638.3|0] "Nm"  dbg
 SG_ DI_tqSatThermal m39 : 8|8@1+ (0.4,0) [0|102] "%"  dbg
 SG_ DI_statorEndWindingTemp m72 : 8|8@1+ (1,-40) [-40|215] "DegC"  gtw
 SG_ DI_phaseOutBusbarTemp m70 : 8|8@1+ (1,-40) [-40|215] "DegC"  gtw
 SG_ DI_pwrSatDischargeCurrent m40 : 8|8@1+ (0.4,0) [0|102] "%"  dbg
 SG_ DI_tqScaleDifferential m35 : 8|8@1+ (0.4,0) [0|102] "%"  dbg
 SG_ DI_offsetA m32 : 8|8@1- (0.1,0.0) [-12.8|12.7] "A"  dbg
 SG_ DI_resolverOffsetCos m48 : 8|8@1+ (0.015,0) [0|3.3] "V"  X
 SG_ DI_cpu1kHzMin m67 : 8|8@1+ (0.4,0) [0|102] "%"  dbg
 SG_ DI_soptTimeToTrip m49 : 8|8@1+ (0.05,0) [0|10] "ms"  gtw
 SG_ DI_dcCapTemp m64 : 8|8@1+ (1,-40) [-40|215] "DegC"  dbg
 SG_ DI_ssmState m38 : 8|4@1+ (1,0) [0|8] ""  dbg
 SG_ DI_rotorOffsetLearningState m63 : 8|4@1+ (1,0) [0|9] ""  X
 SG_ DI_veMassInvRaw m41 : 8|12@1+ (1e-07,0.0001) [0.0001|0.0005] "1/kg"  dbg
 SG_ DI_cpu10HzMin m66 : 8|8@1+ (0.4,0) [0|102] "%"  dbg
 SG_ DI_gateDriveSupplyState m50 : 8|2@1+ (1,0) [0|3] ""  X
 SG_ DI_offsetB m33 : 8|8@1- (0.1,0.0) [-12.8|12.7] "A"  dbg
 SG_ DI_pwrSatChargeCurrent m42 : 8|8@1+ (0.4,0) [0|102] "%"  dbg
 SG_ DI_velocityEstimatorState m65 : 8|3@1+ (1,0) [0|4] ""  dbg
 SG_ DI_debugSelector M : 0|8@1+ (1,0) [0|255] ""  dbg

BO_ 897 VCFRONT_logging1Hz: 8 VEH
 SG_ VCFRONT_fiveWayValveRadBypass m3 : 57|7@1+ (1,0) [0|100] "%"  gtw
 SG_ VCFRONT_radiatorFanFETTemp m2 : 56|8@1+ (1,-40) [-40|150] "degC"  gtw
 SG_ VCFRONT_fiveWayValveWindupEstR m3 : 52|4@1+ (1,0) [0|15] ""  gtw
 SG_ VCFRONT_targetBatActiveHeat m0 : 48|7@1+ (1,-40) [-40|60] "degC"  gtw
 SG_ VCFRONT_pumpPowertrainFETTemp m2 : 48|8@1+ (1,-40) [-40|150] "degC"  gtw
 SG_ VCFRONT_fiveWayValveWindupEstL m3 : 48|4@1+ (1,0) [0|15] ""  gtw
 SG_ VCFRONT_targetBatPassive m0 : 40|7@1+ (1,-20) [-20|80] "degC"  gtw
 SG_ VCFRONT_pumpBatteryFETTemp m2 : 40|8@1+ (1,-40) [-40|150] "degC"  gtw
 SG_ VCFRONT_tempRefrigSuction m1 : 37|8@1+ (0.5,-40) [-40|85] "degC"  gtw
 SG_ VCFRONT_targetBatActiveCool m0 : 32|7@1+ (1,0) [0|100] "degC"  gtw
 SG_ VCFRONT_activeLouverOpenPos m2 : 32|7@1+ (1,0) [0|100] "%"  gtw
 SG_ VCFRONT_fiveWayValveRecalCount m3 : 32|16@1+ (1,0) [0|65535] ""  gtw
 SG_ VCFRONT_fanDemandRadiator m1 : 30|7@1+ (1,0) [0|100] "%"  gtw
 SG_ VCFRONT_targetPTPassive m0 : 24|8@1+ (1,-40) [-40|120] "degC"  gtw
 SG_ VCFRONT_activeLouverOpenPosTarg m2 : 24|7@1+ (1,0) [0|100] "%"  gtw
 SG_ VCFRONT_fanDemandCondenser m1 : 23|7@1+ (1,0) [0|100] "%"  gtw
 SG_ VCFRONT_activeLouverMotorState m1 : 18|4@1+ (1,0) [0|8] ""  gtw
 SG_ VCFRONT_activeLouverOverTemp m1 : 17|1@1+ (1,0) [0|1] ""  gtw
 SG_ VCFRONT_targetPTActiveCool m0 : 16|8@1+ (1,-40) [-40|120] "degC"  gtw
 SG_ VCFRONT_activeLouverOverCurrent m1 : 16|1@1+ (1,0) [0|1] ""  gtw
 SG_ VCFRONT_fiveWayValveAngleDrift m3 : 16|10@1+ (0.25,-127) [-127|127] "degrees"  gtw
 SG_ VCFRONT_activeLouverAbnormalKT m1 : 15|1@1+ (1,0) [0|1] ""  gtw
 SG_ VCFRONT_modeDesired m0 : 8|1@1+ (1,0) [0|1] ""  gtw
 SG_ VCFRONT_activeLouverMotorCounts m2 : 8|11@1+ (1,-100) [-100|1900] "ticks"  gtw
 SG_ VCFRONT_condenserPressureLimit m1 : 8|7@1+ (0.1,10) [10|20] "bar"  gtw
 SG_ VCFRONT_fiveWayValveCountRange m3 : 8|8@1+ (1,375) [375|625] "ticks"  gtw
 SG_ VCFRONT_activeLouverIsCalibrated m2 : 6|1@1+ (1,0) [0|1] ""  gtw
 SG_ VCFRONT_fiveWayValveRecalReason m3 : 3|3@1+ (1,0) [0|5] ""  gtw
 SG_ VCFRONT_modeTransitionID m0 : 3|5@1+ (1,0) [0|21] ""  gtw
 SG_ VCFRONT_activeLouverState m2 : 3|3@1+ (1,0) [0|4] ""  gtw
 SG_ VCFRONT_logging1HzIndex M : 0|3@1+ (1,0) [0|16] ""  X

BO_ 548 PCS_dcdcStatus: 8 VEH
 SG_ PCS_dcdcInitialPrechargeSubState : 59|5@1+ (1,0) [0|17] ""  gtw
 SG_ PCS_dcdcPrechargeRestartCnt : 56|3@1+ (1,0) [0|7] ""  gtw
 SG_ PCS_ecuLogUploadRequest : 54|2@1+ (1,0) [0|3] ""  gtw
 SG_ PCS_dcdcSupportingFixedLvTarget : 53|1@1+ (1,0) [0|1] ""  gtw
 SG_ PCS_dcdcPwmEnableLine : 52|1@1+ (1,0) [0|1] ""  gtw
 SG_ PCS_dcdcDischargeRtyCnt : 48|4@1+ (1,0) [0|15] ""  gtw
 SG_ PCS_dcdc12VSupportRtyCnt : 44|4@1+ (1,0) [0|15] ""  dbg
 SG_ PCS_dcdcPrechargeRtyCnt : 41|3@1+ (1,0) [0|7] ""  dbg
 SG_ PCS_dcdcMaxOutputCurrentAllowed : 29|12@1+ (0.1,0) [0|400] "A"  gtw
 SG_ PCS_dcdcOutputIsLimited : 28|1@1+ (1,0) [0|1] ""  gtw
 SG_ PCS_dcdcLvOutputCurrent : 16|12@1+ (0.1,0) [0|400] "A"  gtw
 SG_ PCS_dcdcFaulted : 15|1@1+ (1,0) [0|1] ""  dbg
 SG_ PCS_dcdcSubState : 10|5@1+ (1,0) [0|17] ""  dbg
 SG_ PCS_dcdcMainState : 6|4@1+ (1,0) [0|6] ""  dbg
 SG_ PCS_dcdcHvBusDischargeStatus : 4|2@1+ (1,0) [0|2] ""  gtw
 SG_ PCS_dcdc12VSupportStatus : 2|2@1+ (1,0) [0|2] ""  gtw
 SG_ PCS_dcdcPrechargeStatus : 0|2@1+ (1,0) [0|2] ""  gtw

BO_ 618 HVP_bmsChargeRegulation: 3 VEH
 SG_ HVP_fcPrechargeRequest : 16|1@1+ (1,0) [0|1] ""  dbg
 SG_ HVP_fcPrechargeTargetVoltage : 0|16@1- (0.1,0) [-3276.8|3276.7] "V"  dbg

BO_ 1042 BMS_xcpResponse: 8 VEH
 SG_ BMS_xcpResponse : 0|64@1+ (1,0) [0|18446744073709551615] ""  X

BO_ 775 PTC_faultsAndExtras: 8 VEH
 SG_ PTC_igbt15V : 56|8@1+ (0.25,0) [0|63.75] "V"  gtw
 SG_ PTC_failLeftCurrentHVSensorWng : 31|1@1+ (1,0) [0|1] ""  gtw
 SG_ PTC_failRightCurrentHVSensorWng : 30|1@1+ (1,0) [0|1] ""  gtw
 SG_ PTC_failRightIGBTShortWarning : 29|1@1+ (1,0) [0|1] ""  gtw
 SG_ PTC_failLeftIGBTShortWarning : 28|1@1+ (1,0) [0|1] ""  gtw
 SG_ PTC_failRightIGBTOpen : 27|1@1+ (1,0) [0|1] ""  gtw
 SG_ PTC_failLeftIGBTOpen : 26|1@1+ (1,0) [0|1] ""  gtw
 SG_ PTC_failIGBTDriverPermanent : 25|1@1+ (1,0) [0|1] ""  gtw
 SG_ PTC_failIGBTDriverTemporary : 24|1@1+ (1,0) [0|1] ""  gtw
 SG_ PTC_failRightIGBTShort : 23|1@1+ (1,0) [0|1] ""  gtw
 SG_ PTC_failLeftIGBTShort : 22|1@1+ (1,0) [0|1] ""  gtw
 SG_ PTC_failTempPCB : 21|1@1+ (1,0) [0|1] ""  gtw
 SG_ PTC_failRightTempIGBT : 20|1@1+ (1,0) [0|1] ""  gtw
 SG_ PTC_failTempOCP : 19|1@1+ (1,0) [0|1] ""  gtw
 SG_ PTC_failLeftTempIGBT : 18|1@1+ (1,0) [0|1] ""  gtw
 SG_ PTC_failRightCurrentHVSensor : 17|1@1+ (1,0) [0|1] ""  gtw
 SG_ PTC_failLeftCurrentHVSensor : 16|1@1+ (1,0) [0|1] ""  gtw
 SG_ PTC_failHighVoltageSensor : 15|1@1+ (1,0) [0|1] ""  gtw
 SG_ PTC_failLowVoltageSensor : 14|1@1+ (1,0) [0|1] ""  gtw
 SG_ PTC_faultCANTimeout : 13|1@1+ (1,0) [0|1] ""  gtw
 SG_ PTC_faultRightThermalShutIGBT : 12|1@1+ (1,0) [0|1] ""  gtw
 SG_ PTC_faultLeftThermalShutIGBT : 10|1@1+ (1,0) [0|1] ""  gtw
 SG_ PTC_faultThermalShutPCB : 9|1@1+ (1,0) [0|1] ""  gtw
 SG_ PTC_faultRightThermalShutOutlet : 8|1@1+ (1,0) [0|1] ""  gtw
 SG_ PTC_faultLeftThermalShutOutlet : 7|1@1+ (1,0) [0|1] ""  gtw
 SG_ PTC_faultRightOverCurrent : 6|1@1+ (1,0) [0|1] ""  gtw
 SG_ PTC_faultLeftOverCurrent : 5|1@1+ (1,0) [0|1] ""  gtw
 SG_ PTC_faultHVHigh : 4|1@1+ (1,0) [0|1] ""  gtw
 SG_ PTC_faultHVLow : 3|1@1+ (1,0) [0|1] ""  gtw
 SG_ PTC_faultLVHigh : 2|1@1+ (1,0) [0|1] ""  gtw
 SG_ PTC_faultLVLow : 1|1@1+ (1,0) [0|1] ""  gtw

BO_ 1025 BMS_brickMeasurements: 8 VEH
 SG_ BMS_brickVoltage90 m29 : 48|16@1+ (0.0001,0) [0|5] "V"  dbg
 SG_ BMS_brickVoltage18 m5 : 48|16@1+ (0.0001,0) [0|5] "V"  dbg
 SG_ BMS_brickVoltage45 m14 : 48|16@1+ (0.0001,0) [0|5] "V"  dbg
 SG_ BMS_brickVoltage30 m9 : 48|16@1+ (0.0001,0) [0|5] "V"  dbg
 SG_ BMS_brickVoltage12 m3 : 48|16@1+ (0.0001,0) [0|5] "V"  dbg
 SG_ BMS_brickVoltage66 m21 : 48|16@1+ (0.0001,0) [0|5] "V"  dbg
 SG_ BMS_brickVoltage72 m23 : 48|16@1+ (0.0001,0) [0|5] "V"  dbg
 SG_ BMS_brickVoltage36 m11 : 48|16@1+ (0.0001,0) [0|5] "V"  dbg
 SG_ BMS_brickVoltage75 m24 : 48|16@1+ (0.0001,0) [0|5] "V"  dbg
 SG_ BMS_brickVoltage57 m18 : 48|16@1+ (0.0001,0) [0|5] "V"  dbg
 SG_ BMS_brickVoltage96 m31 : 48|16@1+ (0.0001,0) [0|5] "V"  dbg
 SG_ BMS_brickVoltage78 m25 : 48|16@1+ (0.0001,0) [0|5] "V"  dbg
 SG_ BMS_brickVoltage48 m15 : 48|16@1+ (0.0001,0) [0|5] "V"  dbg
 SG_ BMS_brickVoltage15 m4 : 48|16@1+ (0.0001,0) [0|5] "V"  dbg
 SG_ BMS_brickVoltage84 m27 : 48|16@1+ (0.0001,0) [0|5] "V"  dbg
 SG_ BMS_brickVoltage51 m16 : 48|16@1+ (0.0001,0) [0|5] "V"  dbg
 SG_ BMS_brickVoltage108 m35 : 48|16@1+ (0.0001,0) [0|5] "V"  dbg
 SG_ BMS_brickVoltage81 m26 : 48|16@1+ (0.0001,0) [0|5] "V"  dbg
 SG_ BMS_brickVoltage9 m2 : 48|16@1+ (0.0001,0) [0|5] "V"  dbg
 SG_ BMS_brickVoltage54 m17 : 48|16@1+ (0.0001,0) [0|5] "V"  dbg
 SG_ BMS_brickVoltage6 m1 : 48|16@1+ (0.0001,0) [0|5] "V"  dbg
 SG_ BMS_brickVoltage24 m7 : 48|16@1+ (0.0001,0) [0|5] "V"  dbg
 SG_ BMS_brickVoltage60 m19 : 48|16@1+ (0.0001,0) [0|5] "V"  dbg
 SG_ BMS_brickVoltage42 m13 : 48|16@1+ (0.0001,0) [0|5] "V"  dbg
 SG_ BMS_brickVoltage3 m0 : 48|16@1+ (0.0001,0) [0|5] "V"  dbg
 SG_ BMS_brickVoltage21 m6 : 48|16@1+ (0.0001,0) [0|5] "V"  dbg
 SG_ BMS_brickVoltage102 m33 : 48|16@1+ (0.0001,0) [0|5] "V"  dbg
 SG_ BMS_brickVoltage99 m32 : 48|16@1+ (0.0001,0) [0|5] "V"  dbg
 SG_ BMS_brickVoltage33 m10 : 48|16@1+ (0.0001,0) [0|5] "V"  dbg
 SG_ BMS_brickVoltage63 m20 : 48|16@1+ (0.0001,0) [0|5] "V"  dbg
 SG_ BMS_brickVoltage27 m8 : 48|16@1+ (0.0001,0) [0|5] "V"  dbg
 SG_ BMS_brickVoltage39 m12 : 48|16@1+ (0.0001,0) [0|5] "V"  dbg
 SG_ BMS_brickVoltage93 m30 : 48|16@1+ (0.0001,0) [0|5] "V"  dbg
 SG_ BMS_brickVoltage69 m22 : 48|16@1+ (0.0001,0) [0|5] "V"  dbg
 SG_ BMS_brickVoltage87 m28 : 48|16@1+ (0.0001,0) [0|5] "V"  dbg
 SG_ BMS_brickVoltage105 m34 : 48|16@1+ (0.0001,0) [0|5] "V"  dbg
 SG_ BMS_brickVoltage23 m7 : 32|16@1+ (0.0001,0) [0|5] "V"  dbg
 SG_ BMS_brickVoltage89 m29 : 32|16@1+ (0.0001,0) [0|5] "V"  dbg
 SG_ BMS_brickVoltage86 m28 : 32|16@1+ (0.0001,0) [0|5] "V"  dbg
 SG_ BMS_brickVoltage71 m23 : 32|16@1+ (0.0001,0) [0|5] "V"  dbg
 SG_ BMS_brickVoltage53 m17 : 32|16@1+ (0.0001,0) [0|5] "V"  dbg
 SG_ BMS_brickVoltage68 m22 : 32|16@1+ (0.0001,0) [0|5] "V"  dbg
 SG_ BMS_brickVoltage35 m11 : 32|16@1+ (0.0001,0) [0|5] "V"  dbg
 SG_ BMS_brickVoltage17 m5 : 32|16@1+ (0.0001,0) [0|5] "V"  dbg
 SG_ BMS_brickVoltage83 m27 : 32|16@1+ (0.0001,0) [0|5] "V"  dbg
 SG_ BMS_brickVoltage74 m24 : 32|16@1+ (0.0001,0) [0|5] "V"  dbg
 SG_ BMS_brickVoltage56 m18 : 32|16@1+ (0.0001,0) [0|5] "V"  dbg
 SG_ BMS_brickVoltage29 m9 : 32|16@1+ (0.0001,0) [0|5] "V"  dbg
 SG_ BMS_brickVoltage44 m14 : 32|16@1+ (0.0001,0) [0|5] "V"  dbg
 SG_ BMS_brickVoltage101 m33 : 32|16@1+ (0.0001,0) [0|5] "V"  dbg
 SG_ BMS_brickVoltage50 m16 : 32|16@1+ (0.0001,0) [0|5] "V"  dbg
 SG_ BMS_brickVoltage14 m4 : 32|16@1+ (0.0001,0) [0|5] "V"  dbg
 SG_ BMS_brickVoltage32 m10 : 32|16@1+ (0.0001,0) [0|5] "V"  dbg
 SG_ BMS_brickVoltage98 m32 : 32|16@1+ (0.0001,0) [0|5] "V"  dbg
 SG_ BMS_brickVoltage107 m35 : 32|16@1+ (0.0001,0) [0|5] "V"  dbg
 SG_ BMS_brickVoltage92 m30 : 32|16@1+ (0.0001,0) [0|5] "V"  dbg
 SG_ BMS_brickVoltage65 m21 : 32|16@1+ (0.0001,0) [0|5] "V"  dbg
 SG_ BMS_brickVoltage38 m12 : 32|16@1+ (0.0001,0) [0|5] "V"  dbg
 SG_ BMS_brickVoltage47 m15 : 32|16@1+ (0.0001,0) [0|5] "V"  dbg
 SG_ BMS_brickVoltage77 m25 : 32|16@1+ (0.0001,0) [0|5] "V"  dbg
 SG_ BMS_brickVoltage8 m2 : 32|16@1+ (0.0001,0) [0|5] "V"  dbg
 SG_ BMS_brickVoltage11 m3 : 32|16@1+ (0.0001,0) [0|5] "V"  dbg
 SG_ BMS_brickVoltage80 m26 : 32|16@1+ (0.0001,0) [0|5] "V"  dbg
 SG_ BMS_brickVoltage104 m34 : 32|16@1+ (0.0001,0) [0|5] "V"  dbg
 SG_ BMS_brickVoltage41 m13 : 32|16@1+ (0.0001,0) [0|5] "V"  dbg
 SG_ BMS_brickVoltage5 m1 : 32|16@1+ (0.0001,0) [0|5] "V"  dbg
 SG_ BMS_brickVoltage20 m6 : 32|16@1+ (0.0001,0) [0|5] "V"  dbg
 SG_ BMS_brickVoltage2 m0 : 32|16@1+ (0.0001,0) [0|5] "V"  dbg
 SG_ BMS_brickVoltage95 m31 : 32|16@1+ (0.0001,0) [0|5] "V"  dbg
 SG_ BMS_brickVoltage59 m19 : 32|16@1+ (0.0001,0) [0|5] "V"  dbg
 SG_ BMS_brickVoltage26 m8 : 32|16@1+ (0.0001,0) [0|5] "V"  dbg
 SG_ BMS_brickVoltage62 m20 : 32|16@1+ (0.0001,0) [0|5] "V"  dbg
 SG_ BMS_brickVoltage1 m0 : 16|16@1+ (0.0001,0) [0|5] "V"  dbg
 SG_ BMS_brickVoltage67 m22 : 16|16@1+ (0.0001,0) [0|5] "V"  dbg
 SG_ BMS_brickVoltage100 m33 : 16|16@1+ (0.0001,0) [0|5] "V"  dbg
 SG_ BMS_brickVoltage22 m7 : 16|16@1+ (0.0001,0) [0|5] "V"  dbg
 SG_ BMS_brickVoltage19 m6 : 16|16@1+ (0.0001,0) [0|5] "V"  dbg
 SG_ BMS_brickVoltage88 m29 : 16|16@1+ (0.0001,0) [0|5] "V"  dbg
 SG_ BMS_brickVoltage91 m30 : 16|16@1+ (0.0001,0) [0|5] "V"  dbg
 SG_ BMS_brickVoltage49 m16 : 16|16@1+ (0.0001,0) [0|5] "V"  dbg
 SG_ BMS_brickVoltage85 m28 : 16|16@1+ (0.0001,0) [0|5] "V"  dbg
 SG_ BMS_brickVoltage28 m9 : 16|16@1+ (0.0001,0) [0|5] "V"  dbg
 SG_ BMS_brickVoltage31 m10 : 16|16@1+ (0.0001,0) [0|5] "V"  dbg
 SG_ BMS_brickVoltage13 m4 : 16|16@1+ (0.0001,0) [0|5] "V"  dbg
 SG_ BMS_brickVoltage82 m27 : 16|16@1+ (0.0001,0) [0|5] "V"  dbg
 SG_ BMS_brickVoltage7 m2 : 16|16@1+ (0.0001,0) [0|5] "V"  dbg
 SG_ BMS_brickVoltage25 m8 : 16|16@1+ (0.0001,0) [0|5] "V"  dbg
 SG_ BMS_brickVoltage61 m20 : 16|16@1+ (0.0001,0) [0|5] "V"  dbg
 SG_ BMS_brickVoltage43 m14 : 16|16@1+ (0.0001,0) [0|5] "V"  dbg
 SG_ BMS_brickVoltage106 m35 : 16|16@1+ (0.0001,0) [0|5] "V"  dbg
 SG_ BMS_brickVoltage37 m12 : 16|16@1+ (0.0001,0) [0|5] "V"  dbg
 SG_ BMS_brickVoltage73 m24 : 16|16@1+ (0.0001,0) [0|5] "V"  dbg
 SG_ BMS_brickVoltage10 m3 : 16|16@1+ (0.0001,0) [0|5] "V"  dbg
 SG_ BMS_brickVoltage76 m25 : 16|16@1+ (0.0001,0) [0|5] "V"  dbg
 SG_ BMS_brickVoltage79 m26 : 16|16@1+ (0.0001,0) [0|5] "V"  dbg
 SG_ BMS_brickVoltage97 m32 : 16|16@1+ (0.0001,0) [0|5] "V"  dbg
 SG_ BMS_brickVoltage55 m18 : 16|16@1+ (0.0001,0) [0|5] "V"  dbg
 SG_ BMS_brickVoltage94 m31 : 16|16@1+ (0.0001,0) [0|5] "V"  dbg
 SG_ BMS_brickVoltage58 m19 : 16|16@1+ (0.0001,0) [0|5] "V"  dbg
 SG_ BMS_brickVoltage64 m21 : 16|16@1+ (0.0001,0) [0|5] "V"  dbg
 SG_ BMS_brickVoltage103 m34 : 16|16@1+ (0.0001,0) [0|5] "V"  dbg
 SG_ BMS_brickVoltage46 m15 : 16|16@1+ (0.0001,0) [0|5] "V"  dbg
 SG_ BMS_brickVoltage34 m11 : 16|16@1+ (0.0001,0) [0|5] "V"  dbg
 SG_ BMS_brickVoltage16 m5 : 16|16@1+ (0.0001,0) [0|5] "V"  dbg
 SG_ BMS_brickVoltage70 m23 : 16|16@1+ (0.0001,0) [0|5] "V"  dbg
 SG_ BMS_brickVoltage52 m17 : 16|16@1+ (0.0001,0) [0|5] "V"  dbg
 SG_ BMS_brickVoltage4 m1 : 16|16@1+ (0.0001,0) [0|5] "V"  dbg
 SG_ BMS_brickVoltage40 m13 : 16|16@1+ (0.0001,0) [0|5] "V"  dbg
 SG_ BMS_brickVoltageStatus72 m23 : 12|2@1+ (1,0) [0|3] ""  dbg
 SG_ BMS_brickVoltageStatus36 m11 : 12|2@1+ (1,0) [0|3] ""  dbg
 SG_ BMS_brickVoltageStatus39 m12 : 12|2@1+ (1,0) [0|3] ""  dbg
 SG_ BMS_brickVoltageStatus93 m30 : 12|2@1+ (1,0) [0|3] ""  dbg
 SG_ BMS_brickVoltageStatus78 m25 : 12|2@1+ (1,0) [0|3] ""  dbg
 SG_ BMS_brickVoltageStatus96 m31 : 12|2@1+ (1,0) [0|3] ""  dbg
 SG_ BMS_brickVoltageStatus15 m4 : 12|2@1+ (1,0) [0|3] ""  dbg
 SG_ BMS_brickVoltageStatus48 m15 : 12|2@1+ (1,0) [0|3] ""  dbg
 SG_ BMS_brickVoltageStatus51 m16 : 12|2@1+ (1,0) [0|3] ""  dbg
 SG_ BMS_brickVoltageStatus84 m27 : 12|2@1+ (1,0) [0|3] ""  dbg
 SG_ BMS_brickVoltageStatus90 m29 : 12|2@1+ (1,0) [0|3] ""  dbg
 SG_ BMS_brickVoltageStatus18 m5 : 12|2@1+ (1,0) [0|3] ""  dbg
 SG_ BMS_brickVoltageStatus45 m14 : 12|2@1+ (1,0) [0|3] ""  dbg
 SG_ BMS_brickVoltageStatus6 m1 : 12|2@1+ (1,0) [0|3] ""  dbg
 SG_ BMS_brickVoltageStatus60 m19 : 12|2@1+ (1,0) [0|3] ""  dbg
 SG_ BMS_brickVoltageStatus42 m13 : 12|2@1+ (1,0) [0|3] ""  dbg
 SG_ BMS_brickVoltageStatus24 m7 : 12|2@1+ (1,0) [0|3] ""  dbg
 SG_ BMS_brickVoltageStatus30 m9 : 12|2@1+ (1,0) [0|3] ""  dbg
 SG_ BMS_brickVoltageStatus12 m3 : 12|2@1+ (1,0) [0|3] ""  dbg
 SG_ BMS_brickVoltageStatus66 m21 : 12|2@1+ (1,0) [0|3] ""  dbg
 SG_ BMS_brickVoltageStatus63 m20 : 12|2@1+ (1,0) [0|3] ""  dbg
 SG_ BMS_brickVoltageStatus27 m8 : 12|2@1+ (1,0) [0|3] ""  dbg
 SG_ BMS_brickVoltageStatus57 m18 : 12|2@1+ (1,0) [0|3] ""  dbg
 SG_ BMS_brickVoltageStatus75 m24 : 12|2@1+ (1,0) [0|3] ""  dbg
 SG_ BMS_brickVoltageStatus87 m28 : 12|2@1+ (1,0) [0|3] ""  dbg
 SG_ BMS_brickVoltageStatus69 m22 : 12|2@1+ (1,0) [0|3] ""  dbg
 SG_ BMS_brickVoltageStatus105 m34 : 12|2@1+ (1,0) [0|3] ""  dbg
 SG_ BMS_brickVoltageStatus108 m35 : 12|2@1+ (1,0) [0|3] ""  dbg
 SG_ BMS_brickVoltageStatus54 m17 : 12|2@1+ (1,0) [0|3] ""  dbg
 SG_ BMS_brickVoltageStatus9 m2 : 12|2@1+ (1,0) [0|3] ""  dbg
 SG_ BMS_brickVoltageStatus81 m26 : 12|2@1+ (1,0) [0|3] ""  dbg
 SG_ BMS_brickVoltageStatus102 m33 : 12|2@1+ (1,0) [0|3] ""  dbg
 SG_ BMS_brickVoltageStatus21 m6 : 12|2@1+ (1,0) [0|3] ""  dbg
 SG_ BMS_brickVoltageStatus3 m0 : 12|2@1+ (1,0) [0|3] ""  dbg
 SG_ BMS_brickVoltageStatus99 m32 : 12|2@1+ (1,0) [0|3] ""  dbg
 SG_ BMS_brickVoltageStatus33 m10 : 12|2@1+ (1,0) [0|3] ""  dbg
 SG_ BMS_brickVoltageStatus50 m16 : 10|2@1+ (1,0) [0|3] ""  dbg
 SG_ BMS_brickVoltageStatus14 m4 : 10|2@1+ (1,0) [0|3] ""  dbg
 SG_ BMS_brickVoltageStatus20 m6 : 10|2@1+ (1,0) [0|3] ""  dbg
 SG_ BMS_brickVoltageStatus2 m0 : 10|2@1+ (1,0) [0|3] ""  dbg
 SG_ BMS_brickVoltageStatus89 m29 : 10|2@1+ (1,0) [0|3] ""  dbg
 SG_ BMS_brickVoltageStatus23 m7 : 10|2@1+ (1,0) [0|3] ""  dbg
 SG_ BMS_brickVoltageStatus107 m35 : 10|2@1+ (1,0) [0|3] ""  dbg
 SG_ BMS_brickVoltageStatus29 m9 : 10|2@1+ (1,0) [0|3] ""  dbg
 SG_ BMS_brickVoltageStatus74 m24 : 10|2@1+ (1,0) [0|3] ""  dbg
 SG_ BMS_brickVoltageStatus56 m18 : 10|2@1+ (1,0) [0|3] ""  dbg
 SG_ BMS_brickVoltageStatus83 m27 : 10|2@1+ (1,0) [0|3] ""  dbg
 SG_ BMS_brickVoltageStatus101 m33 : 10|2@1+ (1,0) [0|3] ""  dbg
 SG_ BMS_brickVoltageStatus44 m14 : 10|2@1+ (1,0) [0|3] ""  dbg
 SG_ BMS_brickVoltageStatus104 m34 : 10|2@1+ (1,0) [0|3] ""  dbg
 SG_ BMS_brickVoltageStatus41 m13 : 10|2@1+ (1,0) [0|3] ""  dbg
 SG_ BMS_brickVoltageStatus5 m1 : 10|2@1+ (1,0) [0|3] ""  dbg
 SG_ BMS_brickVoltageStatus26 m8 : 10|2@1+ (1,0) [0|3] ""  dbg
 SG_ BMS_brickVoltageStatus59 m19 : 10|2@1+ (1,0) [0|3] ""  dbg
 SG_ BMS_brickVoltageStatus95 m31 : 10|2@1+ (1,0) [0|3] ""  dbg
 SG_ BMS_brickVoltageStatus62 m20 : 10|2@1+ (1,0) [0|3] ""  dbg
 SG_ BMS_brickVoltageStatus32 m10 : 10|2@1+ (1,0) [0|3] ""  dbg
 SG_ BMS_brickVoltageStatus98 m32 : 10|2@1+ (1,0) [0|3] ""  dbg
 SG_ BMS_brickVoltageStatus35 m11 : 10|2@1+ (1,0) [0|3] ""  dbg
 SG_ BMS_brickVoltageStatus17 m5 : 10|2@1+ (1,0) [0|3] ""  dbg
 SG_ BMS_brickVoltageStatus68 m22 : 10|2@1+ (1,0) [0|3] ""  dbg
 SG_ BMS_brickVoltageStatus71 m23 : 10|2@1+ (1,0) [0|3] ""  dbg
 SG_ BMS_brickVoltageStatus53 m17 : 10|2@1+ (1,0) [0|3] ""  dbg
 SG_ BMS_brickVoltageStatus86 m28 : 10|2@1+ (1,0) [0|3] ""  dbg
 SG_ BMS_brickVoltageStatus92 m30 : 10|2@1+ (1,0) [0|3] ""  dbg
 SG_ BMS_brickVoltageStatus38 m12 : 10|2@1+ (1,0) [0|3] ""  dbg
 SG_ BMS_brickVoltageStatus65 m21 : 10|2@1+ (1,0) [0|3] ""  dbg
 SG_ BMS_brickVoltageStatus47 m15 : 10|2@1+ (1,0) [0|3] ""  dbg
 SG_ BMS_brickVoltageStatus77 m25 : 10|2@1+ (1,0) [0|3] ""  dbg
 SG_ BMS_brickVoltageStatus8 m2 : 10|2@1+ (1,0) [0|3] ""  dbg
 SG_ BMS_brickVoltageStatus80 m26 : 10|2@1+ (1,0) [0|3] ""  dbg
 SG_ BMS_brickVoltageStatus11 m3 : 10|2@1+ (1,0) [0|3] ""  dbg
 SG_ BMS_brickVoltageStatus49 m16 : 8|2@1+ (1,0) [0|3] ""  dbg
 SG_ BMS_brickVoltageStatus85 m28 : 8|2@1+ (1,0) [0|3] ""  dbg
 SG_ BMS_brickVoltageStatus103 m34 : 8|2@1+ (1,0) [0|3] ""  dbg
 SG_ BMS_brickVoltageStatus64 m21 : 8|2@1+ (1,0) [0|3] ""  dbg
 SG_ BMS_brickVoltageStatus46 m15 : 8|2@1+ (1,0) [0|3] ""  dbg
 SG_ BMS_brickVoltageStatus106 m35 : 8|2@1+ (1,0) [0|3] ""  dbg
 SG_ BMS_brickVoltageStatus61 m20 : 8|2@1+ (1,0) [0|3] ""  dbg
 SG_ BMS_brickVoltageStatus43 m14 : 8|2@1+ (1,0) [0|3] ""  dbg
 SG_ BMS_brickVoltageStatus25 m8 : 8|2@1+ (1,0) [0|3] ""  dbg
 SG_ BMS_brickVoltageStatus7 m2 : 8|2@1+ (1,0) [0|3] ""  dbg
 SG_ BMS_brickVoltageStatus37 m12 : 8|2@1+ (1,0) [0|3] ""  dbg
 SG_ BMS_brickVoltageStatus73 m24 : 8|2@1+ (1,0) [0|3] ""  dbg
 SG_ BMS_brickVoltageStatus1 m0 : 8|2@1+ (1,0) [0|3] ""  dbg
 SG_ BMS_brickVoltageStatus100 m33 : 8|2@1+ (1,0) [0|3] ""  dbg
 SG_ BMS_brickVoltageStatus67 m22 : 8|2@1+ (1,0) [0|3] ""  dbg
 SG_ BMS_brickVoltageStatus79 m26 : 8|2@1+ (1,0) [0|3] ""  dbg
 SG_ BMS_brickVoltageStatus97 m32 : 8|2@1+ (1,0) [0|3] ""  dbg
 SG_ BMS_brickVoltageStatus19 m6 : 8|2@1+ (1,0) [0|3] ""  dbg
 SG_ BMS_brickVoltageStatus22 m7 : 8|2@1+ (1,0) [0|3] ""  dbg
 SG_ BMS_brickVoltageStatus88 m29 : 8|2@1+ (1,0) [0|3] ""  dbg
 SG_ BMS_brickVoltageStatus91 m30 : 8|2@1+ (1,0) [0|3] ""  dbg
 SG_ BMS_brickVoltageStatus58 m19 : 8|2@1+ (1,0) [0|3] ""  dbg
 SG_ BMS_brickVoltageStatus94 m31 : 8|2@1+ (1,0) [0|3] ""  dbg
 SG_ BMS_brickVoltageStatus82 m27 : 8|2@1+ (1,0) [0|3] ""  dbg
 SG_ BMS_brickVoltageStatus31 m10 : 8|2@1+ (1,0) [0|3] ""  dbg
 SG_ BMS_brickVoltageStatus13 m4 : 8|2@1+ (1,0) [0|3] ""  dbg
 SG_ BMS_brickVoltageStatus28 m9 : 8|2@1+ (1,0) [0|3] ""  dbg
 SG_ BMS_brickVoltageStatus70 m23 : 8|2@1+ (1,0) [0|3] ""  dbg
 SG_ BMS_brickVoltageStatus52 m17 : 8|2@1+ (1,0) [0|3] ""  dbg
 SG_ BMS_brickVoltageStatus34 m11 : 8|2@1+ (1,0) [0|3] ""  dbg
 SG_ BMS_brickVoltageStatus16 m5 : 8|2@1+ (1,0) [0|3] ""  dbg
 SG_ BMS_brickVoltageStatus4 m1 : 8|2@1+ (1,0) [0|3] ""  dbg
 SG_ BMS_brickVoltageStatus40 m13 : 8|2@1+ (1,0) [0|3] ""  dbg
 SG_ BMS_brickVoltageStatus10 m3 : 8|2@1+ (1,0) [0|3] ""  dbg
 SG_ BMS_brickVoltageStatus76 m25 : 8|2@1+ (1,0) [0|3] ""  dbg
 SG_ BMS_brickVoltageStatus55 m18 : 8|2@1+ (1,0) [0|3] ""  dbg
 SG_ BMS_brickVoltageMultiplexer M : 0|8@1+ (1,0) [0|35] ""  dbg

BO_ 2031 DBG_testMessage: 2 VEH
 SG_ DBG_testID : 0|16@1+ (1,0) [0|65535] ""  X

BO_ 1962 HVP_debugMessage: 8 VEH
 SG_ HVP_shuntHwMia m0 : 61|1@1+ (1,0) [0|1] ""  X
 SG_ HVP_shuntThermistorMia m0 : 60|1@1+ (1,0) [0|1] ""  X
 SG_ HVP_shuntRefVoltageMismatch m0 : 59|1@1+ (1,0) [0|1] ""  X
 SG_ HVP_currentSenseMia m0 : 58|1@1+ (1,0) [0|1] ""  X
 SG_ HVP_auxCurrentMia m0 : 57|1@1+ (1,0) [0|1] ""  X
 SG_ HVP_packCurrentMia m0 : 56|1@1+ (1,0) [0|1] ""  X
 SG_ HVP_shuntRefVoltageDbg m5 : 48|16@1- (0.001,0) [-32.768|32.767] "V"  dbg
 SG_ HVP_pyroAnalog m2 : 48|12@1+ (0.1,0) [0|3] "V"  X
 SG_ HVP_hvilOutVoltage m4 : 40|12@1+ (0.1,0) [0|30] "V"  gtw
 SG_ HVP_fcLinkVoltage m1 : 40|16@1- (0.1,0) [-3276.8|3276.7] "V"  dbg
 SG_ HVP_shuntAsicTempDbg m6 : 40|16@1- (0.1,0) [-3276.7|3276.7] "C"  dbg
 SG_ HVP_shuntCurrentDebug m0 : 40|16@1- (0.1,0) [-3276.8|3276.8] "A"  dbg
 SG_ HVP_fcLinkNegativeV m3 : 40|16@1- (0.1,0) [-550|550] "V"  dbg
 SG_ HVP_battery12V m5 : 36|12@1+ (0.1,0) [0|30] "V"  gtw
 SG_ HVP_packPositiveV m2 : 32|16@1- (0.1,0) [-550|550] "V"  dbg
 SG_ HVP_hvilInVoltage m4 : 28|12@1+ (0.1,0) [0|30] "V"  gtw
 SG_ HVP_hvp1v5Ref m0 : 28|12@1+ (0.1,0) [0|3] "V"  X
 SG_ HVP_gpioSecDrdy m0 : 27|1@1+ (1,0) [0|1] ""  dbg
 SG_ HVP_gpioHvilEnable m0 : 26|1@1+ (1,0) [0|1] ""  dbg
 SG_ HVP_gpioFcContPowerEnable m0 : 25|1@1+ (1,0) [0|1] ""  dbg
 SG_ HVP_shuntBarTempDbg m6 : 24|16@1- (0.01,0) [-327.67|327.67] "C"  dbg
 SG_ HVP_gpioPcsChargePwmEnable m0 : 24|1@1+ (1,0) [0|1] ""  dbg
 SG_ HVP_packVoltage m1 : 24|16@1- (0.1,0) [-3276.8|3276.7] "V"  dbg
 SG_ HVP_packContCoilCurrent m5 : 24|12@1+ (0.1,0) [0|7.5] "A"  dbg
 SG_ HVP_dcLinkPositiveV m3 : 24|16@1- (0.1,0) [-550|550] "V"  dbg
 SG_ HVP_gpioPcsDcdcPwmEnable m0 : 23|1@1+ (1,0) [0|1] ""  dbg
 SG_ HVP_gpioPcsEnable m0 : 22|1@1+ (1,0) [0|1] ""  dbg
 SG_ HVP_gpioCpLatchEnable m0 : 21|1@1+ (1,0) [0|1] ""  dbg
 SG_ HVP_gpioPackCoontPosFlywheel m0 : 20|1@1+ (1,0) [0|1] ""  dbg
 SG_ HVP_gpioHvpVerEn m0 : 19|1@1+ (1,0) [0|1] ""  dbg
 SG_ HVP_gpioShuntEn m0 : 18|1@1+ (1,0) [0|1] ""  dbg
 SG_ HVP_gpioPyroPor m0 : 17|1@1+ (1,0) [0|1] ""  dbg
 SG_ HVP_fcContVoltage m4 : 16|12@1+ (0.1,0) [0|30] "V"  X
 SG_ HVP_packNegativeV m2 : 16|16@1- (0.1,0) [-550|550] "V"  dbg
 SG_ HVP_gpioCpFaultOut m0 : 16|1@1+ (1,0) [0|1] ""  dbg
 SG_ HVP_gpioBmsEout m0 : 15|1@1+ (1,0) [0|1] ""  dbg
 SG_ HVP_gpioFcContNegAux m0 : 14|1@1+ (1,0) [0|1] ""  dbg
 SG_ HVP_gpioFcContPosAux m0 : 13|1@1+ (1,0) [0|1] ""  dbg
 SG_ HVP_gpioShuntDataReady m0 : 12|1@1+ (1,0) [0|1] ""  dbg
 SG_ HVP_gpioCrashSignal m0 : 11|1@1+ (1,0) [0|1] ""  dbg
 SG_ HVP_gpioLed m0 : 10|1@1+ (1,0) [0|1] ""  dbg
 SG_ HVP_gpioHvpSelfEnable m0 : 9|1@1+ (1,0) [0|1] ""  dbg
 SG_ HVP_fcLinkPositiveV m5 : 8|16@1- (0.1,0) [-550|550] "V"  dbg
 SG_ HVP_shuntAuxCurrentDbg m6 : 8|16@1- (0.1,0) [-3276.8|3276.7] "A"  dbg
 SG_ HVP_dcLinkNegativeV m3 : 8|16@1- (0.1,0) [-550|550] "V"  dbg
 SG_ HVP_gpioHvCablesOk m0 : 8|1@1+ (1,0) [0|1] ""  dbg
 SG_ HVP_dcLinkVoltage m1 : 8|16@1- (0.1,0) [-3276.8|3276.7] "V"  dbg
 SG_ HVP_gpioPackContPowerEn m0 : 7|1@1+ (1,0) [0|1] ""  dbg
 SG_ HVP_gpioCpFaultIn m0 : 6|1@1+ (1,0) [0|1] ""  dbg
 SG_ HVP_gpioPyroIsoEn m0 : 5|1@1+ (1,0) [0|1] ""  dbg
 SG_ HVP_gpioPassivePyroDepl m0 : 4|1@1+ (1,0) [0|1] ""  dbg
 SG_ HVP_fcContCoilCurrent m4 : 4|12@1+ (0.1,0) [0|7.5] "A"  dbg
 SG_ HVP_packContVoltage m2 : 4|12@1+ (0.1,0) [0|30] "V"  dbg
 SG_ HVP_debugMessageMultiplexer M : 0|4@1+ (1,0) [0|6] ""  X

BO_ 1545 VCRIGHT_udsResponse: 8 VEH
 SG_ VCRIGHT_udsResponseData_L : 39|32@0+ (1,0) [0|4294967295] ""  gtw
 SG_ VCRIGHT_udsResponseData_H : 7|32@0+ (1,0) [0|4294967295] ""  gtw

BO_ 927 FC_alertMatrix4: 8 VEH
 SG_ FC_a193_FCAlertPlaceholder : 0|1@1+ (1,0) [0|1] ""  gtw

BO_ 1734 UDS_ptcRequest: 8 VEH
 SG_ UDS_ptcRequestData : 7|64@0+ (1,0) [0|18446744073709551615] ""  ptc

BO_ 2015 UDS_functionalRequest: 8 VEH
 SG_ UDS_functionalRequestData_7 : 63|8@0+ (1,0) [0|255] ""  bms
 SG_ UDS_functionalRequestData_6 : 55|8@0+ (1,0) [0|255] ""  bms
 SG_ UDS_functionalRequestData_5 : 47|8@0+ (1,0) [0|255] ""  bms
 SG_ UDS_functionalRequestData_4 : 39|8@0+ (1,0) [0|255] ""  bms
 SG_ UDS_functionalRequestData_3 : 31|8@0+ (1,0) [0|255] ""  bms
 SG_ UDS_functionalRequestData_2 : 23|8@0+ (1,0) [0|255] ""  bms
 SG_ UDS_functionalRequestData_1 : 15|8@0+ (1,0) [0|255] ""  bms
 SG_ UDS_functionalRequestData_0 : 7|8@0+ (1,0) [0|255] ""  bms

BO_ 868 PCS_thermalControl: 2 VEH
 SG_ PCS_tempInletTargetCoolActive : 9|7@1+ (1,0) [0|127] "DegC"  vcfront
 SG_ PCS_flowRequest : 0|9@1+ (0.1,0) [0|30] "LPM"  gtw

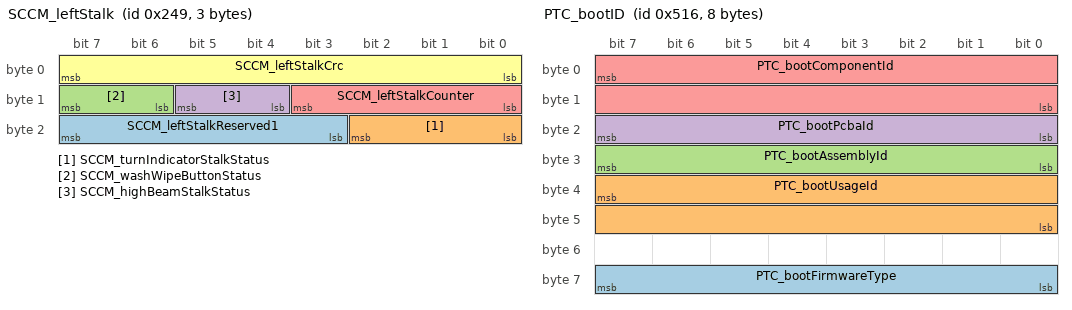
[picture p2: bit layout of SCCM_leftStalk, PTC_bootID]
BO_ 585 SCCM_leftStalk: 3 VEH
 SG_ SCCM_leftStalkReserved1 : 19|5@1+ (1,0) [0|31] ""  X
 SG_ SCCM_turnIndicatorStalkStatus : 16|3@1+ (1,0) [0|5] ""  das
 SG_ SCCM_washWipeButtonStatus : 14|2@1+ (1,0) [0|3] ""  das
 SG_ SCCM_highBeamStalkStatus : 12|2@1+ (1,0) [0|3] ""  das
 SG_ SCCM_leftStalkCounter : 8|4@1+ (1,0) [0|15] ""  X
 SG_ SCCM_leftStalkCrc : 0|8@1+ (1,0) [0|255] ""  X

BO_ 522 HVP_contactorState: 6 VEH
 SG_ HVP_hvilStatus : 40|4@1+ (1,0) [0|8] ""  dbg
 SG_ HVP_pyroTestInProgress : 39|1@1+ (1,0) [0|1] ""  X
 SG_ HVP_dcLinkAllowedToEnergize : 38|1@1+ (1,0) [0|1] ""  gtw
 SG_ HVP_packCtrsClosingAllowed : 37|1@1+ (1,0) [0|1] ""  gtw
 SG_ HVP_packCtrsOpenRequested : 36|1@1+ (1,0) [0|1] ""  gtw
 SG_ HVP_packCtrsOpenNowRequested : 35|1@1+ (1,0) [0|1] ""  dbg
 SG_ HVP_packCtrsResetRequestRequired : 34|1@1+ (1,0) [0|1] ""  X
 SG_ HVP_packCtrsRequestStatus : 32|2@1+ (1,0) [0|2] ""  X
 SG_ HVP_fcLinkAllowedToEnergizeDc : 31|1@1+ (1,0) [0|1] ""  gtw
 SG_ HVP_fcLinkAllowedToEnergizeAc : 30|1@1+ (1,0) [0|1] ""  gtw
 SG_ HVP_fcCtrsClosingAllowed : 29|1@1+ (1,0) [0|1] ""  gtw
 SG_ HVP_fcCtrsOpenRequested : 28|1@1+ (1,0) [0|1] ""  gtw
 SG_ HVP_fcCtrsOpenNowRequested : 27|1@1+ (1,0) [0|1] ""  dbg
 SG_ HVP_fcCtrsResetRequestRequired : 26|1@1+ (1,0) [0|1] ""  X
 SG_ HVP_fcCtrsRequestStatus : 24|2@1+ (1,0) [0|2] ""  X
 SG_ HVP_fcContactorSetState : 19|4@1+ (1,0) [0|9] ""  gtw
 SG_ HVP_fcContPositiveState : 16|3@1+ (1,0) [0|7] ""  gtw
 SG_ HVP_fcContNegativeState : 12|3@1+ (1,0) [0|7] ""  gtw
 SG_ HVP_packContactorSetState : 8|4@1+ (1,0) [0|9] ""  gtw
 SG_ HVP_fcContNegativeAuxOpen : 7|1@1+ (1,0) [0|1] ""  X
 SG_ HVP_fcContPositiveAuxOpen : 6|1@1+ (1,0) [0|1] ""  X
 SG_ HVP_packContPositiveState : 3|3@1+ (1,0) [0|7] ""  gtw
 SG_ HVP_packContNegativeState : 0|3@1+ (1,0) [0|7] ""  X

BO_ 1444 PMS_alertLog: 8 VEH
 SG_ PMS_a011_sampleFreeze m11 : 61|1@1+ (1,0) [0|1] ""  gtw
 SG_ PMS_a011_badPhaseBsample m11 : 60|1@1+ (1,0) [0|1] ""  gtw
 SG_ PMS_a011_badPhaseAsample m11 : 59|1@1+ (1,0) [0|1] ""  gtw
 SG_ PMS_a055_diMIA m55 : 54|1@1+ (1,0) [0|1] ""  gtw
 SG_ PMS_a055_claMIA m55 : 53|1@1+ (1,0) [0|1] ""  gtw
 SG_ PMS_a055_diSpeedMismatch m55 : 52|1@1+ (1,0) [0|1] ""  gtw
 SG_ PMS_a055_diElecAngleMismatch m55 : 51|1@1+ (1,0) [0|1] ""  gtw
 SG_ PMS_a055_phaseOutOfSpec m55 : 50|1@1+ (1,0) [0|1] ""  gtw
 SG_ PMS_a055_noCarrier m55 : 49|1@1+ (1,0) [0|1] ""  gtw
 SG_ PMS_a003_w2 m3 : 48|16@1+ (1,0) [0|65535] ""  gtw
 SG_ PMS_a004_w2 m4 : 48|16@1+ (1,0) [0|65535] ""  gtw
 SG_ PMS_a057_badValue2 m57 : 48|16@1+ (1,0) [0|65535] ""  gtw
 SG_ PMS_a028_w2 m28 : 48|8@1+ (1,0) [0|255] ""  gtw
 SG_ PMS_a013_errorType m13 : 48|3@1+ (1,0) [0|5] ""  gtw
 SG_ PMS_a012_badValue2 m12 : 48|16@1+ (1,0) [0|65535] ""  gtw
 SG_ PMS_a005_w2 m5 : 48|16@1+ (1,0) [0|65535] ""  gtw
 SG_ PMS_a027_w2 m27 : 48|16@1+ (1,0) [0|65535] ""  gtw
 SG_ PMS_a056_errorType m56 : 48|3@1+ (1,0) [0|5] ""  gtw
 SG_ PMS_a034_motorRPM m34 : 48|16@1- (1,0) [-17000|17000] "RPM"  gtw
 SG_ PMS_a011_currentVref m11 : 48|11@1+ (0.005,0) [0|10.235] "V"  gtw
 SG_ PMS_a055_notReady m55 : 48|1@1+ (1,0) [0|1] ""  gtw
 SG_ PMS_a001_w2 m1 : 48|16@1+ (1,0) [0|65535] ""  gtw
 SG_ PMS_a002_w2 m2 : 48|16@1+ (1,0) [0|65535] ""  gtw
 SG_ PMS_a038_pedalPos m38 : 48|8@1- (0.4,50.4) [0|100] "%"  gtw
 SG_ PMS_a034_torqueType m34 : 45|2@1+ (1,0) [0|2] ""  gtw
 SG_ PMS_a031_stackSize m31 : 42|10@1+ (1,0) [0|1023] ""  gtw
 SG_ PMS_a055_commonGain m55 : 40|8@1+ (0.02,0) [0|5.1] "1"  gtw
 SG_ PMS_a008_stackSize m8 : 40|16@1+ (1,0) [0|65535] ""  gtw
 SG_ PMS_a006_inputs m6 : 40|16@1+ (1,0) [0|65535] ""  gtw
 SG_ PMS_a033_DSADC_Ib m33 : 40|16@1- (0.0939,0) [-3076.9152|3076.8213] "A"  gtw
 SG_ PMS_a010_DI_chassisControl m10 : 38|1@1+ (1,0) [0|1] ""  gtw
 SG_ PMS_a010_DI_systemStatus m10 : 37|1@1+ (1,0) [0|1] ""  gtw
 SG_ PMS_a010_DI_speed m10 : 36|1@1+ (1,0) [0|1] ""  gtw
 SG_ PMS_a010_DI_locStatus m10 : 35|1@1+ (1,0) [0|1] ""  gtw
 SG_ PMS_a010_DI_slaveCommand m10 : 34|1@1+ (1,0) [0|1] ""  gtw
 SG_ PMS_a010_DI_torque m10 : 33|1@1+ (1,0) [0|1] ""  gtw
 SG_ PMS_a038_slaveTorque m38 : 32|13@1- (0.4,0.0) [-1638.4|1638] "Nm"  gtw
 SG_ PMS_a055_phaseAngle m55 : 32|8@1+ (0.00308,0) [0|0.7854] "1"  gtw
 SG_ PMS_a002_w1 m2 : 32|16@1+ (1,0) [0|65535] ""  gtw
 SG_ PMS_a010_DI_status m10 : 32|1@1+ (1,0) [0|1] ""  gtw
 SG_ PMS_a001_w1 m1 : 32|16@1+ (1,0) [0|65535] ""  gtw
 SG_ PMS_a031_stackUsedPrev m31 : 32|10@1+ (1,0) [0|1023] ""  gtw
 SG_ PMS_a004_w1 m4 : 32|16@1+ (1,0) [0|65535] ""  gtw
 SG_ PMS_a011_Ib m11 : 32|16@1- (0.0939,0) [-3076.9152|3076.8213] "A"  gtw
 SG_ PMS_a012_badValue1 m12 : 32|16@1+ (1,0) [0|65535] ""  gtw
 SG_ PMS_a006_shiftState m6 : 32|3@1+ (1,0) [0|7] ""  gtw
 SG_ PMS_a028_w1 m28 : 32|16@1+ (1,0) [0|65535] ""  gtw
 SG_ PMS_a019_statorTslope1 m19 : 32|16@1- (0.1,0) [-3276.8|3276.7] "DegC/s"  gtw
 SG_ PMS_a057_badValue1 m57 : 32|16@1+ (1,0) [0|65535] ""  gtw
 SG_ PMS_a056_canID m56 : 32|16@1+ (1,0) [0|65535] ""  gtw
 SG_ PMS_a003_w1 m3 : 32|16@1+ (1,0) [0|65535] ""  gtw
 SG_ PMS_a034_parameterPM m34 : 32|13@1- (0.25,0.0) [-750|750] "Nm_or_%"  gtw
 SG_ PMS_a013_canID m13 : 32|16@1+ (1,0) [0|65535] ""  gtw
 SG_ PMS_a027_w1 m27 : 32|16@1+ (1,0) [0|65535] ""  gtw
 SG_ PMS_a005_w1 m5 : 32|16@1+ (1,0) [0|65535] ""  gtw
 SG_ PMS_a026_switchingActive m26 : 29|1@1+ (1,0) [0|1] ""  gtw
 SG_ PMS_a057_errorType m57 : 28|3@1+ (1,0) [0|6] ""  gtw
 SG_ PMS_a012_errorType m12 : 28|3@1+ (1,0) [0|6] ""  gtw
 SG_ PMS_a043_brakeHWType m43 : 27|1@1+ (1,0) [0|1] ""  gtw
 SG_ PMS_a043_expectedVdcType m43 : 26|1@1+ (1,0) [0|1] ""  gtw
 SG_ PMS_a043_GTW_vdcType m43 : 25|1@1+ (1,0) [0|1] ""  gtw
 SG_ PMS_a033_DSADC_Ia m33 : 24|16@1- (0.0939,0) [-3076.9152|3076.8213] "A"  gtw
 SG_ PMS_a039_messageId m39 : 24|16@1+ (1,0) [0|65535] ""  gtw
 SG_ PMS_a040_messageId m40 : 24|16@1+ (1,0) [0|65535] ""  gtw
 SG_ PMS_a061_pmIpcVersion m61 : 24|8@1+ (1,0) [0|255] ""  gtw
 SG_ PMS_a043_performancePackage m43 : 24|1@1+ (1,0) [0|1] ""  gtw
 SG_ PMS_a008_stackUsed m8 : 24|16@1+ (1,0) [0|65535] ""  gtw
 SG_ PMS_a026_isrCount m26 : 24|5@1+ (1,0) [0|31] ""  gtw
 SG_ PMS_a043_packEnergy m43 : 23|1@1+ (1,0) [0|1] ""  gtw
 SG_ PMS_a026_diWdtUdsRqst m26 : 23|1@1+ (1,0) [0|1] ""  gtw
 SG_ PMS_a026_diLoopRunning m26 : 22|1@1+ (1,0) [0|1] ""  gtw
 SG_ PMS_a031_stackUsed m31 : 22|10@1+ (1,0) [0|1023] ""  gtw
 SG_ PMS_a026_diWdtHWEvent m26 : 21|1@1+ (1,0) [0|1] ""  gtw
 SG_ PMS_a043_expectedDrivetrainType m43 : 21|2@1+ (1,0) [0|3] ""  gtw
 SG_ PMS_a033_failReason m33 : 20|3@1+ (1,0) [0|7] ""  gtw
 SG_ PMS_a064_torqueCmdState m64 : 20|4@1+ (1,0) [0|8] ""  gtw
 SG_ PMS_a026_diWdt1kHz m26 : 20|1@1+ (1,0) [0|1] ""  gtw
 SG_ PMS_a026_diWdt100Hz m26 : 19|1@1+ (1,0) [0|1] ""  gtw
 SG_ PMS_a043_GTW_drivetrainType m43 : 19|2@1+ (1,0) [0|3] ""  gtw
 SG_ PMS_a042_expectedPerformanceCfg m42 : 18|1@1+ (1,0) [0|1] ""  gtw
 SG_ PMS_a026_diWdt10Hz m26 : 18|1@1+ (1,0) [0|1] ""  gtw
 SG_ PMS_a009_ESP_party3 m9 : 18|1@1+ (1,0) [0|1] ""  gtw
 SG_ PMS_a043_expectedAutopilot m43 : 18|1@1+ (1,0) [0|1] ""  gtw
 SG_ PMS_a009_ESP_status m9 : 17|1@1+ (1,0) [0|1] ""  gtw
 SG_ PMS_a053_coolant m53 : 17|1@1+ (1,0) [0|1] ""  gtw
 SG_ PMS_a043_GTW_autopilot m43 : 17|1@1+ (1,0) [0|1] ""  gtw
 SG_ PMS_a039_DIS_torque m39 : 17|1@1+ (1,0) [0|1] ""  gtw
 SG_ PMS_a042_GTW_drivetrainType m42 : 17|1@1+ (1,0) [0|1] ""  gtw
 SG_ PMS_a054_uiChassisControl m54 : 17|1@1+ (1,0) [0|1] ""  gtw
 SG_ PMS_a026_diWdtIdle m26 : 17|1@1+ (1,0) [0|1] ""  gtw
 SG_ PMS_a001_w0 m1 : 16|16@1+ (1,0) [0|65535] ""  gtw
 SG_ PMS_a040_PM_state m40 : 16|1@1+ (1,0) [0|1] ""  gtw
 SG_ PMS_a039_DIS_status m39 : 16|1@1+ (1,0) [0|1] ""  gtw
 SG_ PMS_a064_interventionType m64 : 16|4@1+ (1,0) [0|10] ""  gtw
 SG_ PMS_a033_state m33 : 16|4@1+ (1,0) [0|11] ""  gtw
 SG_ PMS_a010_messageId m10 : 16|16@1+ (1,0) [0|65535] ""  gtw
 SG_ PMS_a009_ESP_wheelSpeeds m9 : 16|1@1+ (1,0) [0|1] ""  gtw
 SG_ PMS_a061_diIpcVersion m61 : 16|8@1+ (1,0) [0|255] ""  gtw
 SG_ PMS_a056_mailboxID m56 : 16|16@1+ (1,0) [0|65535] ""  gtw
 SG_ PMS_a031_taskID m31 : 16|6@1+ (1,0) [0|63] ""  gtw
 SG_ PMS_a043_configInconsistent m43 : 16|1@1+ (1,0) [0|1] ""  gtw
 SG_ PMS_a002_w0 m2 : 16|16@1+ (1,0) [0|65535] ""  gtw
 SG_ PMS_a026_reason m26 : 16|1@1+ (1,0) [0|1] ""  gtw
 SG_ PMS_a004_w0 m4 : 16|16@1+ (1,0) [0|65535] ""  gtw
 SG_ PMS_a013_mailboxID m13 : 16|16@1+ (1,0) [0|65535] ""  gtw
 SG_ PMS_a053_LVPowerState m53 : 16|1@1+ (1,0) [0|1] ""  gtw
 SG_ PMS_a003_w0 m3 : 16|16@1+ (1,0) [0|65535] ""  gtw
 SG_ PMS_a006_gearsAllowed m6 : 16|16@1+ (1,0) [0|65535] ""  gtw
 SG_ PMS_a055_motorRPM m55 : 16|16@1- (1,0) [-20000|20000] "RPM"  gtw
 SG_ PMS_a042_GTW_carConfig m42 : 16|1@1+ (1,0) [0|1] ""  gtw
 SG_ PMS_a038_masterTorque m38 : 16|13@1- (0.4,0.0) [-1638.4|1638] "Nm"  gtw
 SG_ PMS_a027_w0 m27 : 16|16@1+ (1,0) [0|65535] ""  gtw
 SG_ PMS_a005_w0 m5 : 16|16@1+ (1,0) [0|65535] ""  gtw
 SG_ PMS_a012_canID m12 : 16|12@1+ (1,0) [0|4095] ""  gtw
 SG_ PMS_a019_statorTemp1 m19 : 16|16@1- (0.1,0) [-3276.8|3276.7] "DegC"  gtw
 SG_ PMS_a054_uiPowertrainControl m54 : 16|1@1+ (1,0) [0|1] ""  gtw
 SG_ PMS_a028_w0 m28 : 16|16@1+ (1,0) [0|65535] ""  gtw
 SG_ PMS_a011_Ia m11 : 16|16@1- (0.0939,0) [-3076.9152|3076.8213] "A"  gtw
 SG_ PMS_a008_taskID m8 : 16|8@1+ (1,0) [0|255] ""  gtw
 SG_ PMS_a057_canID m57 : 16|12@1+ (1,0) [0|4095] ""  gtw
 SG_ PMS_a034_parameterDI m34 : 16|13@1- (0.25,0.0) [-750|750] "Nm_or_%"  gtw
 SG_ PMS_alertType : 15|1@1+ (1,0) [0|1] ""  gtw
 SG_ PMS_alertID M : 0|7@1+ (1,0) [0|64] ""  gtw

BO_ 1302 PTC_bootID: 8 VEH
 SG_ PTC_bootFirmwareType : 63|8@0+ (1,0) [0|255] ""  gtwu
 SG_ PTC_bootUsageId : 39|16@0+ (1,0) [0|65535] ""  gtwu
 SG_ PTC_bootAssemblyId : 31|8@0+ (1,0) [0|255] ""  gtwu
 SG_ PTC_bootPcbaId : 23|8@0+ (1,0) [0|255] ""  gtwu
 SG_ PTC_bootComponentId : 7|16@0+ (1,0) [0|65535] ""  gtwu

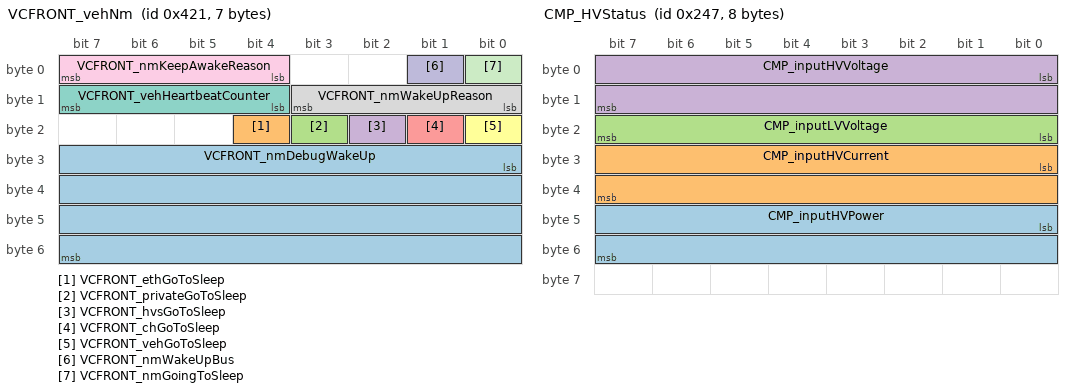
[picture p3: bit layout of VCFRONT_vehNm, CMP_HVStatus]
BO_ 1057 VCFRONT_vehNm: 7 VEH
 SG_ VCFRONT_nmDebugWakeUp : 24|32@1+ (1,0) [0|4294967295] ""  gtw
 SG_ VCFRONT_ethGoToSleep : 20|1@1+ (1,0) [0|1] ""  epbl
 SG_ VCFRONT_privateGoToSleep : 19|1@1+ (1,0) [0|1] ""  epbl
 SG_ VCFRONT_hvsGoToSleep : 18|1@1+ (1,0) [0|1] ""  bms
 SG_ VCFRONT_chGoToSleep : 17|1@1+ (1,0) [0|1] ""  epbl
 SG_ VCFRONT_vehGoToSleep : 16|1@1+ (1,0) [0|1] ""  bms
 SG_ VCFRONT_vehHeartbeatCounter : 12|4@1+ (1,0) [0|15] ""  bms
 SG_ VCFRONT_nmWakeUpReason : 8|4@1+ (1,0) [0|15] ""  gtw
 SG_ VCFRONT_nmKeepAwakeReason : 4|4@1+ (1,0) [0|15] ""  gtw
 SG_ VCFRONT_nmWakeUpBus : 1|1@1+ (1,0) [0|1] ""  X
 SG_ VCFRONT_nmGoingToSleep : 0|1@1+ (1,0) [0|1] ""  X

BO_ 645 UI_driverProfileRecall: 8 VEH
 SG_ UI_steeringColumnInOutPos m2 : 48|8@1- (12,1284) [-200|2750] "ticks"  vcleft
 SG_ UI_frontSeatTiltPos m1 : 48|12@1- (0.1,0) [-204.8|204.7] "deg"  vcleft
 SG_ UI_lumbarBPressureHpa m2 : 32|16@1+ (1,0) [0|65535] ""  vcleft
 SG_ UI_frontSeatLiftPos m1 : 32|10@1- (4,0) [-2048|2044] "mm"  vcleft
 SG_ UI_rightMirrorDipYPosition m4 : 32|8@1+ (0.02,0) [0|5] "V"  vcright
 SG_ UI_rightMirrorTiltYPosition m3 : 32|8@1+ (0.02,0) [0|5] "V"  vcright
 SG_ UI_rightMirrorDipXPosition m4 : 24|8@1+ (0.02,0) [0|5] "V"  vcright
 SG_ UI_rightMirrorTiltXPosition m3 : 24|8@1+ (0.02,0) [0|5] "V"  vcright
 SG_ UI_rightLiftSwitchDown m5 : 18|2@1+ (1,0) [0|3] ""  vcright
 SG_ UI_frontSeatBackPos m1 : 16|12@1- (0.1,0) [-204.8|204.7] "deg"  vcleft
 SG_ UI_lumbarAPressureHpa m2 : 16|16@1+ (1,0) [0|65535] ""  vcleft
 SG_ UI_leftMirrorDipYPosition m4 : 16|8@1+ (0.02,0) [0|5] "V"  vcleft
 SG_ UI_rightLiftSwitchUp m5 : 16|2@1+ (1,0) [0|3] ""  vcright
 SG_ UI_leftMirrorTiltYPosition m3 : 16|8@1+ (0.02,0) [0|5] "V"  vcleft
 SG_ UI_rightBackrestSwitchDown m5 : 14|2@1+ (1,0) [0|3] ""  vcright
 SG_ UI_rightBackrestSwitchUp m5 : 12|2@1+ (1,0) [0|3] ""  vcright
 SG_ UI_leftLiftSwitchDown m5 : 10|2@1+ (1,0) [0|3] ""  vcleft
 SG_ UI_steeringColumnUpDownPos m2 : 8|8@1- (12,1284) [-200|2750] "ticks"  vcleft
 SG_ UI_leftMirrorDipXPosition m4 : 8|8@1+ (0.02,0) [0|5] "V"  vcleft
 SG_ UI_leftLiftSwitchUp m5 : 8|2@1+ (1,0) [0|3] ""  vcleft
 SG_ UI_leftMirrorTiltXPosition m3 : 8|8@1+ (0.02,0) [0|5] "V"  vcleft
 SG_ UI_leftBackrestSwitchDown m5 : 6|2@1+ (1,0) [0|3] ""  vcleft
 SG_ UI_frontSeatTrackPos m1 : 5|10@1- (4,0) [-2048|2044] "mm"  vcleft
 SG_ UI_frontSeatRecallActive m1 : 4|1@1+ (1,0) [0|1] ""  vcleft
 SG_ UI_columnAndLumbarRecallActive m2 : 4|1@1+ (1,0) [0|1] ""  vcleft
 SG_ UI_mirrorRecallActive m3 : 4|1@1+ (1,0) [0|1] ""  vcleft
 SG_ UI_leftBackrestSwitchUp m5 : 4|2@1+ (1,0) [0|3] ""  vcleft
 SG_ UI_driverProfileRecallStop : 3|1@1+ (1,0) [0|1] ""  vcleft
 SG_ UI_driverProfileRecallIndex M : 0|3@1+ (1,0) [0|5] ""  vcleft

BO_ 1445 DIS_alertLog: 8 VEH
 SG_ DIS_a153_spiError m153 : 63|1@1+ (1,0) [0|1] ""  gtw
 SG_ DIS_a014_tcEnabled m14 : 62|1@1+ (1,0) [0|1] ""  gtw
 SG_ DIS_a153_pumpTempIrrational m153 : 62|1@1+ (1,0) [0|1] ""  gtw
 SG_ DIS_a153_pumpOverTemp m153 : 61|1@1+ (1,0) [0|1] ""  gtw
 SG_ DIS_a066_errorType m66 : 60|3@1+ (1,0) [0|6] ""  gtw
 SG_ DIS_a153_motorStall m153 : 60|1@1+ (1,0) [0|1] ""  gtw
 SG_ DIS_a153_motorSpeedTooHigh m153 : 59|1@1+ (1,0) [0|1] ""  gtw
 SG_ DIS_a153_motorSpeedIrrational m153 : 58|1@1+ (1,0) [0|1] ""  gtw
 SG_ DIS_a153_motorOverload m153 : 57|1@1+ (1,0) [0|1] ""  gtw
 SG_ DIS_a024_rotorAngle m24 : 57|7@1- (3,0) [-180|180] "degrees"  gtw
 SG_ DIS_a115_motorRPM m115 : 56|8@1- (150,0) [-17000|17000] "RPM"  gtw
 SG_ DIS_a153_motorCurrentIrrational m153 : 56|1@1+ (1,0) [0|1] ""  gtw
 SG_ DIS_a154_claMIA m154 : 55|1@1+ (1,0) [0|1] ""  gtw
 SG_ DIS_a153_motorControl m153 : 55|1@1+ (1,0) [0|1] ""  gtw
 SG_ DIS_a154_trackerIrrational m154 : 54|1@1+ (1,0) [0|1] ""  gtw
 SG_ DIS_a153_memoryError m153 : 54|1@1+ (1,0) [0|1] ""  gtw
 SG_ DIS_a003_selftestDesat_H m3 : 53|1@1+ (1,0) [0|1] ""  gtw
 SG_ DIS_a001_selftestDesat_H m1 : 53|1@1+ (1,0) [0|1] ""  gtw
 SG_ DIS_a153_linIDParityError m153 : 53|1@1+ (1,0) [0|1] ""  gtw
 SG_ DIS_a154_carrierOffset m154 : 53|1@1+ (1,0) [0|1] ""  gtw
 SG_ DIS_a002_selftestDesat_H m2 : 53|1@1+ (1,0) [0|1] ""  gtw
 SG_ DIS_a002_selftestDesat_L m2 : 52|1@1+ (1,0) [0|1] ""  gtw
 SG_ DIS_a154_errorTableInvalid m154 : 52|1@1+ (1,0) [0|1] ""  gtw
 SG_ DIS_a003_selftestDesat_L m3 : 52|1@1+ (1,0) [0|1] ""  gtw
 SG_ DIS_a014_rmsTorqueError m14 : 52|10@1+ (1,0) [0|750] "Nm"  gtw
 SG_ DIS_a153_linFramingError m153 : 52|1@1+ (1,0) [0|1] ""  gtw
 SG_ DIS_a001_selftestDesat_L m1 : 52|1@1+ (1,0) [0|1] ""  gtw
 SG_ DIS_a038_reason m38 : 52|2@1+ (1,0) [0|2] ""  gtw
 SG_ DIS_a134_wheelSpeedDiffReR m134 : 52|12@1- (0.0625,0) [-256|255] "kph"  gtw
 SG_ DIS_a153_linDataError m153 : 51|1@1+ (1,0) [0|1] ""  gtw
 SG_ DIS_a115_sensors m115 : 51|2@1+ (1,0) [0|3] ""  gtw
 SG_ DIS_a154_notReady m154 : 51|1@1+ (1,0) [0|1] ""  gtw
 SG_ DIS_a153_linChecksumError m153 : 50|1@1+ (1,0) [0|1] ""  gtw
 SG_ DIS_a154_noCarrier m154 : 50|1@1+ (1,0) [0|1] ""  gtw
 SG_ DIS_a154_noPhaseLock m154 : 49|1@1+ (1,0) [0|1] ""  gtw
 SG_ DIS_a153_fluidTempIrrational m153 : 49|1@1+ (1,0) [0|1] ""  gtw
 SG_ DIS_a150_energy m150 : 48|16@1+ (1,0) [0|65535] "J"  gtw
 SG_ DIS_a011_codeBranch m11 : 48|4@1+ (1,0) [0|15] ""  gtw
 SG_ DIS_a003_gateDriveErrCounter m3 : 48|4@1+ (1,0) [0|15] ""  gtw
 SG_ DIS_a066_canID m66 : 48|12@1+ (1,0) [0|4095] ""  gtw
 SG_ DIS_a153_fluidPressureLow m153 : 48|1@1+ (1,0) [0|1] ""  gtw
 SG_ DIS_a113_ph3Temp m113 : 48|16@1- (0.1,0) [-3276.8|3276.7] "C"  gtw
 SG_ DIS_a033_vRefIa m33 : 48|16@1- (0.001,0) [-32.768|32.767] "V"  gtw
 SG_ DIS_a149_responseError m149 : 48|1@1+ (1,0) [0|1] ""  gtw
 SG_ DIS_a103_rmsCurrent m103 : 48|16@1- (0.1,-0.4) [-3276|3275] "A"  gtw
 SG_ DIS_a035_frequency m35 : 48|10@1+ (1,0) [0|255] "Hz"  gtw
 SG_ DIS_a030_iCrmsSpeed m30 : 48|16@1+ (1,0) [0|65535] "RPM"  gtw
 SG_ DIS_a121_badFlux m121 : 48|16@1+ (0.0001,0) [0|6.5535] "Wb"  gtw
 SG_ DIS_a074_motorSpeed2 m74 : 48|16@1- (1,0) [-17000|17000] "RPM"  gtw
 SG_ DIS_a058_pcbTempSlope m58 : 48|8@1- (0.5,0) [-64|63.5] "DegC/s"  gtw
 SG_ DIS_a154_noCalibration m154 : 48|1@1+ (1,0) [0|1] ""  gtw
 SG_ DIS_a001_gateDriveErrCounter m1 : 48|4@1+ (1,0) [0|15] ""  gtw
 SG_ DIS_a034_vRefIb m34 : 48|16@1- (0.001,0) [-32.768|32.767] "V"  gtw
 SG_ DIS_a029_iBrmsSpeed m29 : 48|16@1+ (1,0) [0|65535] "RPM"  gtw
 SG_ DIS_a099_cpuUsage1kHz m99 : 48|8@1+ (1,0) [0|255] "%"  gtw
 SG_ DIS_a027_motorSpeed m27 : 48|16@1+ (1,0) [0|65535] "RPM"  gtw
 SG_ DIS_a028_iArmsSpeed m28 : 48|16@1+ (1,0) [0|65535] "RPM"  gtw
 SG_ DIS_a055_motorRPM m55 : 48|16@1- (1,0) [-17000|17000] "RPM"  gtw
 SG_ DIS_a133_badValue2 m133 : 48|16@1- (0.1,0) [-3276.8|3276.7] "C"  gtw
 SG_ DIS_a093_errorType m93 : 48|1@1+ (1,0) [0|1] ""  gtw
 SG_ DIS_a160_energy m160 : 48|16@1+ (1,0) [0|65535] "J"  gtw
 SG_ DIS_a042_inletTempSlope m42 : 48|8@1- (0.5,0) [-64|63.5] "DegC/s"  gtw
 SG_ DIS_a002_gateDriveErrCounter m2 : 48|4@1+ (1,0) [0|15] ""  gtw
 SG_ DIS_a026_motorSpeed m26 : 48|16@1+ (1,0) [0|65535] "RPM"  gtw
 SG_ DIS_a131_warnTimeRemaining m131 : 48|16@1+ (1,0) [0|65535] ""  gtw
 SG_ DIS_a025_motorSpeed m25 : 48|16@1+ (1,0) [0|65535] "RPM"  gtw
 SG_ DIS_a045_outletTempSlope m45 : 48|8@1- (0.5,0) [-64|63.5] "DegC/s"  gtw
 SG_ DIS_a094_badValue2 m94 : 48|16@1+ (1,0) [0|65535] ""  gtw
 SG_ DIS_a003_deadtimeError_L m3 : 47|1@1+ (1,0) [0|1] ""  gtw
 SG_ DIS_a001_deadtimeError_L m1 : 47|1@1+ (1,0) [0|1] ""  gtw
 SG_ DIS_a149_motorSpeedSNA m149 : 47|1@1+ (1,0) [0|1] ""  gtw
 SG_ DIS_a153_fluidPressureIrrat m153 : 47|1@1+ (1,0) [0|1] ""  gtw
 SG_ DIS_a148_overtorque2Mode m148 : 47|1@1+ (1,0) [0|1] ""  gtw
 SG_ DIS_a002_deadtimeError_L m2 : 47|1@1+ (1,0) [0|1] ""  gtw
 SG_ DIS_a003_spiError_L m3 : 46|1@1+ (1,0) [0|1] ""  gtw
 SG_ DIS_a153_fluidPressureHigh m153 : 46|1@1+ (1,0) [0|1] ""  gtw
 SG_ DIS_a149_motorShorted m149 : 46|1@1+ (1,0) [0|1] ""  gtw
 SG_ DIS_a001_spiError_L m1 : 46|1@1+ (1,0) [0|1] ""  gtw
 SG_ DIS_a148_wearIsValid m148 : 46|1@1+ (1,0) [0|1] ""  gtw
 SG_ DIS_a002_spiError_L m2 : 46|1@1+ (1,0) [0|1] ""  gtw
 SG_ DIS_a149_motorOpenPhase m149 : 45|1@1+ (1,0) [0|1] ""  gtw
 SG_ DIS_a001_localRegError_L m1 : 45|1@1+ (1,0) [0|1] ""  gtw
 SG_ DIS_a055_torqueType m55 : 45|2@1+ (1,0) [0|2] ""  gtw
 SG_ DIS_a024_maxCurrMagSqrd m24 : 45|12@1+ (500,0) [0|1960000] "A2"  gtw
 SG_ DIS_a153_ecuReset m153 : 45|1@1+ (1,0) [0|1] ""  gtw
 SG_ DIS_a002_localRegError_L m2 : 45|1@1+ (1,0) [0|1] ""  gtw
 SG_ DIS_a003_localRegError_L m3 : 45|1@1+ (1,0) [0|1] ""  gtw
 SG_ DIS_a147_wearIsValid m147 : 44|1@1+ (1,0) [0|1] ""  gtw
 SG_ DIS_a002_overvoltVDD_L m2 : 44|1@1+ (1,0) [0|1] ""  gtw
 SG_ DIS_a149_insufficientFlow m149 : 44|1@1+ (1,0) [0|1] ""  gtw
 SG_ DIS_a003_overvoltVDD_L m3 : 44|1@1+ (1,0) [0|1] ""  gtw
 SG_ DIS_a153_12vSupplyUV m153 : 44|1@1+ (1,0) [0|1] ""  gtw
 SG_ DIS_a001_overvoltVDD_L m1 : 44|1@1+ (1,0) [0|1] ""  gtw
 SG_ DIS_a002_undervoltVDD_L m2 : 43|1@1+ (1,0) [0|1] ""  gtw
 SG_ DIS_a001_undervoltVDD_L m1 : 43|1@1+ (1,0) [0|1] ""  gtw
 SG_ DIS_a149_fluidTempSNA m149 : 43|1@1+ (1,0) [0|1] ""  gtw
 SG_ DIS_a003_undervoltVDD_L m3 : 43|1@1+ (1,0) [0|1] ""  gtw
 SG_ DIS_a153_12vSupplyOV m153 : 43|1@1+ (1,0) [0|1] ""  gtw
 SG_ DIS_a001_remoteRegError_L m1 : 42|1@1+ (1,0) [0|1] ""  gtw
 SG_ DIS_a014_brakeMasterCylPress m14 : 42|10@1+ (0.25,-42.5) [-42.5|213.25] "bar"  gtw
 SG_ DIS_a002_remoteRegError_L m2 : 42|1@1+ (1,0) [0|1] ""  gtw
 SG_ DIS_a003_remoteRegError_L m3 : 42|1@1+ (1,0) [0|1] ""  gtw
 SG_ DIS_a153_12vSupplyIrrational m153 : 42|1@1+ (1,0) [0|1] ""  gtw
 SG_ DIS_a001_asynchStop_L m1 : 41|1@1+ (1,0) [0|1] ""  gtw
 SG_ DIS_a002_asynchStop_L m2 : 41|1@1+ (1,0) [0|1] ""  gtw
 SG_ DIS_a003_asynchStop_L m3 : 41|1@1+ (1,0) [0|1] ""  gtw
 SG_ DIS_a156_motorRPM m156 : 40|16@1- (1,0) [-20000|20000] "RPM"  gtw
 SG_ DIS_a003_gateOn_L m3 : 40|1@1+ (1,0) [0|1] ""  gtw
 SG_ DIS_a011_badDataExpected m11 : 40|8@1+ (1,0) [0|255] ""  gtw
 SG_ DIS_a134_wheelSpeedDiffReL m134 : 40|12@1- (0.0625,0) [-256|255] "kph"  gtw
 SG_ DIS_a016_torqueMotor m16 : 40|16@1- (1,0) [-750|750] "Nm"  gtw
 SG_ DIS_a154_commonGain m154 : 40|8@1+ (0.02,0) [0|5.1] "1"  gtw
 SG_ DIS_a115_motorCurrent m115 : 40|11@1+ (1,0) [0|2047] "A"  gtw
 SG_ DIS_a061_otherTemp m61 : 40|16@1- (0.1,0) [-3276.8|3276.7] "C"  gtw
 SG_ DIS_a136_badValue2 m136 : 40|16@1+ (1,0) [0|65535] ""  gtw
 SG_ DIS_a097_argument m97 : 40|16@1+ (1,0) [0|65535] ""  gtw
 SG_ DIS_a150_elapsedMs m150 : 40|8@1+ (1,0) [0|255] "ms"  gtw
 SG_ DIS_a096_word2 m96 : 40|16@1+ (1,0) [0|65535] ""  gtw
 SG_ DIS_a160_elapsedMs m160 : 40|8@1+ (1,0) [0|255] "ms"  gtw
 SG_ DIS_a152_expectedValue m152 : 40|8@1+ (1,0) [0|255] ""  gtw
 SG_ DIS_a001_gateOn_L m1 : 40|1@1+ (1,0) [0|1] ""  gtw
 SG_ DIS_a002_gateOn_L m2 : 40|1@1+ (1,0) [0|1] ""  gtw
 SG_ DIS_a122_stackSize m122 : 40|16@1+ (1,0) [0|65535] ""  gtw
 SG_ DIS_a065_mailboxID m65 : 40|16@1+ (1,0) [0|65535] ""  gtw
 SG_ DIS_a038_iBat m38 : 40|12@1+ (0.5,0) [0|2047.5] "A"  gtw
 SG_ DIS_a123_badFlux m123 : 40|16@1+ (0.0001,0) [0|6.5535] "Wb"  gtw
 SG_ DIS_a099_cpuUsage100Hz m99 : 40|8@1+ (1,0) [0|255] "%"  gtw
 SG_ DIS_a149_state m149 : 40|3@1+ (1,0) [0|7] ""  gtw
 SG_ DIS_a153_state m153 : 39|3@1+ (1,0) [0|7] ""  gtw
 SG_ DIS_a003_overvoltVH_L m3 : 39|1@1+ (1,0) [0|1] ""  gtw
 SG_ DIS_a002_overvoltVH_L m2 : 39|1@1+ (1,0) [0|1] ""  gtw
 SG_ DIS_a001_overvoltVH_L m1 : 39|1@1+ (1,0) [0|1] ""  gtw
 SG_ DIS_a002_overvoltVL_L m2 : 38|1@1+ (1,0) [0|1] ""  gtw
 SG_ DIS_a001_overvoltVL_L m1 : 38|1@1+ (1,0) [0|1] ""  gtw
 SG_ DIS_a024_Ib m24 : 38|7@1- (22.5,0.0) [-1400|1400] "A"  gtw
 SG_ DIS_a003_overvoltVL_L m3 : 38|1@1+ (1,0) [0|1] ""  gtw
 SG_ DIS_a002_desat_L m2 : 37|1@1+ (1,0) [0|1] ""  gtw
 SG_ DIS_a003_desat_L m3 : 37|1@1+ (1,0) [0|1] ""  gtw
 SG_ DIS_a156_alertQueueOverrun m156 : 37|1@1+ (1,0) [0|1] ""  gtw
 SG_ DIS_a001_desat_L m1 : 37|1@1+ (1,0) [0|1] ""  gtw
 SG_ DIS_a001_sense_L m1 : 36|1@1+ (1,0) [0|1] ""  gtw
 SG_ DIS_a045_heatsinkTemp m45 : 36|10@1+ (0.25,-60) [-60|195] "DegC"  gtw
 SG_ DIS_a058_heatsinkTemp m58 : 36|10@1+ (0.25,-60) [-60|195] "DegC"  gtw
 SG_ DIS_a003_sense_L m3 : 36|1@1+ (1,0) [0|1] ""  gtw
 SG_ DIS_a002_sense_L m2 : 36|1@1+ (1,0) [0|1] ""  gtw
 SG_ DIS_a042_heatsinkTemp m42 : 36|10@1+ (0.25,-60) [-60|195] "DegC"  gtw
 SG_ DIS_a148_accumulatedWear m148 : 36|10@1+ (0.005,0) [0|5.115] "1"  gtw
 SG_ DIS_a001_undervoltVH_L m1 : 35|1@1+ (1,0) [0|1] ""  gtw
 SG_ DIS_a156_safeStateRecommend m156 : 35|2@1+ (1,0) [0|3] ""  gtw
 SG_ DIS_a002_undervoltVH_L m2 : 35|1@1+ (1,0) [0|1] ""  gtw
 SG_ DIS_a003_undervoltVH_L m3 : 35|1@1+ (1,0) [0|1] ""  gtw
 SG_ DIS_a001_undervoltVL_L m1 : 34|1@1+ (1,0) [0|1] ""  gtw
 SG_ DIS_a147_accumulatedWear m147 : 34|10@1+ (0.005,0) [0|5.115] "1"  gtw
 SG_ DIS_a002_undervoltVL_L m2 : 34|1@1+ (1,0) [0|1] ""  gtw
 SG_ DIS_a003_undervoltVL_L m3 : 34|1@1+ (1,0) [0|1] ""  gtw
 SG_ DIS_a156_result m156 : 33|2@1+ (1,0) [0|2] ""  gtw
 SG_ DIS_a001_thermalShutdown_L m1 : 33|1@1+ (1,0) [0|1] ""  gtw
 SG_ DIS_a002_thermalShutdown_L m2 : 33|1@1+ (1,0) [0|1] ""  gtw
 SG_ DIS_a003_thermalShutdown_L m3 : 33|1@1+ (1,0) [0|1] ""  gtw
 SG_ DIS_a112_phaseBcurrent m112 : 32|16@1+ (1,0) [0|65535] "A"  gtw
 SG_ DIS_a066_badValue2 m66 : 32|16@1+ (1,0) [0|65535] ""  gtw
 SG_ DIS_a150_vBatFilteredRate m150 : 32|8@1- (100,0) [-12800|12700] "V/s"  gtw
 SG_ DIS_a028_iArmsTorque m28 : 32|16@1+ (0.25,0) [0|16383.75] "Nm"  gtw
 SG_ DIS_a027_torqueMotor m27 : 32|13@1- (0.25,0.0) [-750|750] "Nm"  gtw
 SG_ DIS_a003_thermalWarning_L m3 : 32|1@1+ (1,0) [0|1] ""  gtw
 SG_ DIS_a071_busVslope m71 : 32|16@1+ (0.1,0) [0|6553.5] "V/ms"  gtw
 SG_ DIS_a133_badValue1 m133 : 32|16@1- (0.1,0) [-3276.8|3276.7] "C"  gtw
 SG_ DIS_a047_statorTslope1 m47 : 32|16@1- (0.1,0) [-3276.8|3276.7] "DegC/s"  gtw
 SG_ DIS_a029_iBrmsTorque m29 : 32|16@1+ (0.25,0) [0|16383.75] "Nm"  gtw
 SG_ DIS_a026_torqueMotor m26 : 32|13@1- (0.25,0.0) [-750|750] "Nm"  gtw
 SG_ DIS_a014_torqueCommandFwd m14 : 32|10@1- (2,0) [-750|750] "Nm"  gtw
 SG_ DIS_a154_phaseError m154 : 32|8@1- (0.004,0) [-0.512|0.508] "1"  gtw
 SG_ DIS_a036_busHighLimit m36 : 32|16@1+ (0.1,0) [0|6553.5] "V"  gtw
 SG_ DIS_a115_ph3Temp m115 : 32|8@1- (1,0) [-128|127] "C"  gtw
 SG_ DIS_a095_canID m95 : 32|16@1+ (1,0) [0|65535] ""  gtw
 SG_ DIS_a113_ph2Temp m113 : 32|16@1- (0.1,0) [-3276.8|3276.7] "C"  gtw
 SG_ DIS_a002_thermalWarning_L m2 : 32|1@1+ (1,0) [0|1] ""  gtw
 SG_ DIS_a094_badValue1 m94 : 32|16@1+ (1,0) [0|65535] ""  gtw
 SG_ DIS_a067_mailboxID m67 : 32|16@1+ (1,0) [0|65535] ""  gtw
 SG_ DIS_a149_temperature m149 : 32|8@1+ (1,-40) [-40|205] "DegC"  gtw
 SG_ DIS_a033_deltaIa m33 : 32|16@1- (1,0) [-32768|32767] "A"  gtw
 SG_ DIS_a035_phaseCurrent m35 : 32|16@1+ (1,0) [0|65535] "A"  gtw
 SG_ DIS_a099_cpuUsage10Hz m99 : 32|8@1+ (1,0) [0|255] "%"  gtw
 SG_ DIS_a151_torqueDriver m151 : 32|16@1- (0.25,0) [-750|750] "Nm"  gtw
 SG_ DIS_a093_canID m93 : 32|16@1+ (1,0) [0|65535] ""  gtw
 SG_ DIS_a001_thermalWarning_L m1 : 32|1@1+ (1,0) [0|1] ""  gtw
 SG_ DIS_a103_inletHeatsinkTemp m103 : 32|16@1- (0.1,67.5) [-60|195] "C"  gtw
 SG_ DIS_a074_motorSpeed1 m74 : 32|16@1- (1,0) [-17000|17000] "RPM"  gtw
 SG_ DIS_a108_blockingAlert m108 : 32|8@1+ (1,0) [0|244] ""  gtw
 SG_ DIS_a098_fluxState m98 : 32|4@1+ (1,0) [0|9] ""  gtw
 SG_ DIS_a037_busLowLimit m37 : 32|16@1+ (0.1,0) [0|6553.5] "V"  gtw
 SG_ DIS_a121_badCurrent m121 : 32|16@1- (0.1,0) [-3276.8|3276.7] "A"  gtw
 SG_ DIS_a034_deltaIb m34 : 32|16@1- (1,0) [-32768|32767] "A"  gtw
 SG_ DIS_a055_parameterPM m55 : 32|13@1- (0.25,0.0) [-750|750] "Nm"  gtw
 SG_ DIS_a025_torqueMotor m25 : 32|13@1- (0.25,0.0) [-750|750] "Nm"  gtw
 SG_ DIS_a142_lashCheckCount m142 : 32|15@1+ (1,0) [0|32767] ""  gtw
 SG_ DIS_a156_ucrPlausible m156 : 32|1@1+ (1,0) [0|1] ""  gtw
 SG_ DIS_a116_mechPower m116 : 32|16@1- (0.5,0) [-16384|16383.5] "KW"  gtw
 SG_ DIS_a152_badValue m152 : 32|8@1+ (1,0) [0|255] ""  gtw
 SG_ DIS_a054_heatsinkTemp m54 : 32|16@1- (0.1,0) [-3276.8|3276.7] "C"  gtw
 SG_ DIS_a075_absSpeed m75 : 32|16@1+ (1,0) [0|65535] "RPM"  gtw
 SG_ DIS_a030_iCrmsTorque m30 : 32|16@1+ (0.25,0) [0|16383.75] "Nm"  gtw
 SG_ DIS_a160_vBatFilteredRate m160 : 32|8@1- (100,0) [-12800|12700] "V/s"  gtw
 SG_ DIS_a011_badDataRead m11 : 32|8@1+ (1,0) [0|255] ""  gtw
 SG_ DIS_a153_temperature m153 : 32|7@1+ (2,-40) [-40|205] "DegC"  gtw
 SG_ DIS_a065_errorType m65 : 32|1@1+ (1,0) [0|1] ""  gtw
 SG_ DIS_a131_warnSpeedLimit m131 : 32|16@1+ (1,0) [0|65535] "RPM"  gtw
 SG_ DIS_a046_statorTemp2 m46 : 32|16@1- (0.1,0) [-3276.8|3276.7] "DegC"  gtw
 SG_ DIS_a114_absSpeed m114 : 32|16@1+ (1,0) [0|65535] "RPM"  gtw
 SG_ DIS_a024_Ia m24 : 31|7@1- (22.5,0.0) [-1400|1400] "A"  gtw
 SG_ DIS_a002_deadtimeError_H m2 : 31|1@1+ (1,0) [0|1] ""  gtw
 SG_ DIS_a003_deadtimeError_H m3 : 31|1@1+ (1,0) [0|1] ""  gtw
 SG_ DIS_a156_highMotorSpeed m156 : 31|1@1+ (1,0) [0|1] ""  gtw
 SG_ DIS_a001_deadtimeError_H m1 : 31|1@1+ (1,0) [0|1] ""  gtw
 SG_ DIS_a001_spiError_H m1 : 30|1@1+ (1,0) [0|1] ""  gtw
 SG_ DIS_a014_adState m14 : 30|2@1+ (1,0) [0|3] ""  gtw
 SG_ DIS_a002_spiError_H m2 : 30|1@1+ (1,0) [0|1] ""  gtw
 SG_ DIS_a103_fluidImplausible m103 : 30|1@1+ (1,0) [0|1] ""  gtw
 SG_ DIS_a003_spiError_H m3 : 30|1@1+ (1,0) [0|1] ""  gtw
 SG_ DIS_a156_highCurrentMagnitude m156 : 30|1@1+ (1,0) [0|1] ""  gtw
 SG_ DIS_a011_badGateDriveIC m11 : 29|3@1+ (1,0) [0|7] ""  gtw
 SG_ DIS_a103_lowFlowDetected m103 : 29|1@1+ (1,0) [0|1] ""  gtw
 SG_ DIS_a002_localRegError_H m2 : 29|1@1+ (1,0) [0|1] ""  gtw
 SG_ DIS_a003_localRegError_H m3 : 29|1@1+ (1,0) [0|1] ""  gtw
 SG_ DIS_a001_localRegError_H m1 : 29|1@1+ (1,0) [0|1] ""  gtw
 SG_ DIS_a134_wheelSpeedDiffFrR m134 : 28|12@1- (0.0625,0) [-256|255] "kph"  gtw
 SG_ DIS_a156_powerPolarity m156 : 28|2@1+ (1,0) [0|3] ""  gtw
 SG_ DIS_a001_overvoltVDD_H m1 : 28|1@1+ (1,0) [0|1] ""  gtw
 SG_ DIS_a002_overvoltVDD_H m2 : 28|1@1+ (1,0) [0|1] ""  gtw
 SG_ DIS_a103_noFlowDetected m103 : 28|1@1+ (1,0) [0|1] ""  gtw
 SG_ DIS_a038_vBat m38 : 28|12@1+ (0.2,0) [0|819] "V"  gtw
 SG_ DIS_a094_errorType m94 : 28|3@1+ (1,0) [0|6] ""  gtw
 SG_ DIS_a003_overvoltVDD_H m3 : 28|1@1+ (1,0) [0|1] ""  gtw
 SG_ DIS_a001_undervoltVDD_H m1 : 27|1@1+ (1,0) [0|1] ""  gtw
 SG_ DIS_a024_state m24 : 27|4@1+ (1,0) [0|11] ""  gtw
 SG_ DIS_a003_undervoltVDD_H m3 : 27|1@1+ (1,0) [0|1] ""  gtw
 SG_ DIS_a002_undervoltVDD_H m2 : 27|1@1+ (1,0) [0|1] ""  gtw
 SG_ DIS_a002_remoteRegError_H m2 : 26|1@1+ (1,0) [0|1] ""  gtw
 SG_ DIS_a058_outletTemp m58 : 26|10@1+ (0.25,-60) [-60|195] "DegC"  gtw
 SG_ DIS_a148_overtorque2UsedCount m148 : 26|10@1+ (1,0) [0|1023] ""  gtw
 SG_ DIS_a003_remoteRegError_H m3 : 26|1@1+ (1,0) [0|1] ""  gtw
 SG_ DIS_a074_speed2Type m74 : 26|2@1+ (1,0) [0|3] ""  gtw
 SG_ DIS_a045_outletTemp m45 : 26|10@1+ (0.25,-60) [-60|195] "DegC"  gtw
 SG_ DIS_a042_outletTemp m42 : 26|10@1+ (0.25,-60) [-60|195] "DegC"  gtw
 SG_ DIS_a001_remoteRegError_H m1 : 26|1@1+ (1,0) [0|1] ""  gtw
 SG_ DIS_a156_phaseCPolarity m156 : 26|2@1+ (1,0) [0|3] ""  gtw
 SG_ DIS_a003_asynchStop_H m3 : 25|1@1+ (1,0) [0|1] ""  gtw
 SG_ DIS_a035_phaseDifference m35 : 25|7@1+ (1,0) [0|127] "%"  gtw
 SG_ DIS_a001_asynchStop_H m1 : 25|1@1+ (1,0) [0|1] ""  gtw
 SG_ DIS_a002_asynchStop_H m2 : 25|1@1+ (1,0) [0|1] ""  gtw
 SG_ DIS_a123_badCurrent m123 : 24|16@1- (0.1,0) [-3276.8|3276.7] "A"  gtw
 SG_ DIS_a152_frameId m152 : 24|8@1+ (1,0) [0|255] ""  gtw
 SG_ DIS_a149_voltage m149 : 24|8@1+ (0.1,0) [0|25.5] "V"  gtw
 SG_ DIS_a136_badValue1 m136 : 24|16@1+ (1,0) [0|65535] ""  gtw
 SG_ DIS_a078_adcRefLowAvg m78 : 24|16@1+ (1,0) [0|65535] ""  gtw
 SG_ DIS_a147_overtorque2UsedCount m147 : 24|10@1+ (1,0) [0|1023] ""  gtw
 SG_ DIS_a074_speed1Type m74 : 24|2@1+ (1,0) [0|3] ""  gtw
 SG_ DIS_a001_gateOn_H m1 : 24|1@1+ (1,0) [0|1] ""  gtw
 SG_ DIS_a127_temp m127 : 24|16@1- (0.1,0) [-3276.8|3276.7] "C"  gtw
 SG_ DIS_a115_ph2Temp m115 : 24|8@1- (1,0) [-128|127] "C"  gtw
 SG_ DIS_a002_gateOn_H m2 : 24|1@1+ (1,0) [0|1] ""  gtw
 SG_ DIS_a097_lineNumber m97 : 24|16@1+ (1,0) [0|65535] ""  gtw
 SG_ DIS_a016_motorRPM m16 : 24|16@1- (1,0) [-20000|20000] "RPM"  gtw
 SG_ DIS_a011_regAddress m11 : 24|5@1+ (1,0) [0|31] ""  gtw
 SG_ DIS_a079_adcRefHighAvg m79 : 24|16@1+ (1,0) [0|65535] ""  gtw
 SG_ DIS_a241_rotorMaxMagnetTemp m241 : 24|8@1- (1,88) [-40|215] "degC"  gtw
 SG_ DIS_a035_noDriveCurrent m35 : 24|1@1+ (1,0) [0|1] ""  gtw
 SG_ DIS_a003_gateOn_H m3 : 24|1@1+ (1,0) [0|1] ""  gtw
 SG_ DIS_a153_voltage m153 : 24|8@1+ (0.1,0) [0|25.5] "V"  gtw
 SG_ DIS_a108_toState m108 : 24|8@1+ (1,0) [0|255] ""  gtw
 SG_ DIS_a122_stackUsed m122 : 24|16@1+ (1,0) [0|65535] ""  gtw
 SG_ DIS_a096_word1 m96 : 24|16@1+ (1,0) [0|65535] ""  gtw
 SG_ DIS_a024_failReason m24 : 24|3@1+ (1,0) [0|7] ""  gtw
 SG_ DIS_a099_cpuUsage1Hz m99 : 24|8@1+ (1,0) [0|255] "%"  gtw
 SG_ DIS_a061_phTemp m61 : 24|16@1- (0.1,0) [-3276.8|3276.7] "C"  gtw
 SG_ DIS_a156_phaseBPolarity m156 : 24|2@1+ (1,0) [0|3] ""  gtw
 SG_ DIS_a155_vcleftSwitchStatus m155 : 23|1@1+ (1,0) [0|1] ""  gtw
 SG_ DIS_a002_overvoltVH_H m2 : 23|1@1+ (1,0) [0|1] ""  gtw
 SG_ DIS_a001_overvoltVH_H m1 : 23|1@1+ (1,0) [0|1] ""  gtw
 SG_ DIS_a153_lowFluidLevel m153 : 23|1@1+ (1,0) [0|1] ""  gtw
 SG_ DIS_a144_inverterHardware m144 : 23|1@1+ (1,0) [0|1] ""  gtw
 SG_ DIS_a011_phaseCLow m11 : 23|1@1+ (1,0) [0|1] ""  gtw
 SG_ DIS_a016_alertQueueOverrun m16 : 23|1@1+ (1,0) [0|1] ""  gtw
 SG_ DIS_a003_overvoltVH_H m3 : 23|1@1+ (1,0) [0|1] ""  gtw
 SG_ DIS_a117_systemStatus m117 : 22|1@1+ (1,0) [0|1] ""  gtw
 SG_ DIS_a106_ESP_wheelSpeeds m106 : 22|1@1+ (1,0) [0|1] ""  gtw
 SG_ DIS_a035_reportingPhase m35 : 22|2@1+ (1,0) [0|3] ""  gtw
 SG_ DIS_a156_phaseAPolarity m156 : 22|2@1+ (1,0) [0|3] ""  gtw
 SG_ DIS_a155_rightDoorStatus m155 : 22|1@1+ (1,0) [0|1] ""  gtw
 SG_ DIS_a144_BMS_subUsageId m144 : 22|1@1+ (1,0) [0|1] ""  gtw
 SG_ DIS_a003_overvoltVL_H m3 : 22|1@1+ (1,0) [0|1] ""  gtw
 SG_ DIS_a011_phaseCHigh m11 : 22|1@1+ (1,0) [0|1] ""  gtw
 SG_ DIS_a002_overvoltVL_H m2 : 22|1@1+ (1,0) [0|1] ""  gtw
 SG_ DIS_a016_uncontrolledRegenZone m16 : 22|1@1+ (1,0) [0|1] ""  gtw
 SG_ DIS_a001_overvoltVL_H m1 : 22|1@1+ (1,0) [0|1] ""  gtw
 SG_ DIS_a144_brakeHWType m144 : 21|1@1+ (1,0) [0|1] ""  gtw
 SG_ DIS_a092_bmsInfo m92 : 21|1@1+ (1,0) [0|1] ""  gtw
 SG_ DIS_a011_phaseBLow m11 : 21|1@1+ (1,0) [0|1] ""  gtw
 SG_ DIS_a035_wontMoveCurrent m35 : 21|1@1+ (1,0) [0|1] ""  gtw
 SG_ DIS_a117_chassisControl m117 : 21|1@1+ (1,0) [0|1] ""  gtw
 SG_ DIS_a106_WHL_STAT2 m106 : 21|1@1+ (1,0) [0|1] ""  gtw
 SG_ DIS_a001_desat_H m1 : 21|1@1+ (1,0) [0|1] ""  gtw
 SG_ DIS_a016_ascMonitor m16 : 21|1@1+ (1,0) [0|1] ""  gtw
 SG_ DIS_a002_desat_H m2 : 21|1@1+ (1,0) [0|1] ""  gtw
 SG_ DIS_a155_leftDoorStatus m155 : 21|1@1+ (1,0) [0|1] ""  gtw
 SG_ DIS_a003_desat_H m3 : 21|1@1+ (1,0) [0|1] ""  gtw
 SG_ DIS_a035_unbalancedCurrent m35 : 20|1@1+ (1,0) [0|1] ""  gtw
 SG_ DIS_a040_capability2 m40 : 20|1@1+ (1,0) [0|1] ""  gtw
 SG_ DIS_a064_torqueCmdState m64 : 20|4@1+ (1,0) [0|8] ""  gtw
 SG_ DIS_a003_sense_H m3 : 20|1@1+ (1,0) [0|1] ""  gtw
 SG_ DIS_a155_status m155 : 20|1@1+ (1,0) [0|1] ""  gtw
 SG_ DIS_a106_ECB1S04 m106 : 20|1@1+ (1,0) [0|1] ""  gtw
 SG_ DIS_a144_vdcType m144 : 20|1@1+ (1,0) [0|1] ""  gtw
 SG_ DIS_a002_sense_H m2 : 20|1@1+ (1,0) [0|1] ""  gtw
 SG_ DIS_a096_mem_regs m96 : 20|1@1+ (1,0) [0|1] ""  gtw
 SG_ DIS_a099_thread1kHz m99 : 20|1@1+ (1,0) [0|1] ""  gtw
 SG_ DIS_a092_bmsBmbMinMax m92 : 20|1@1+ (1,0) [0|1] ""  gtw
 SG_ DIS_a117_speed m117 : 20|1@1+ (1,0) [0|1] ""  gtw
 SG_ DIS_a001_sense_H m1 : 20|1@1+ (1,0) [0|1] ""  gtw
 SG_ DIS_a016_gateDriveFaultLine m16 : 20|1@1+ (1,0) [0|1] ""  gtw
 SG_ DIS_a011_phaseBHigh m11 : 20|1@1+ (1,0) [0|1] ""  gtw
 SG_ DIS_a001_undervoltVH_H m1 : 19|1@1+ (1,0) [0|1] ""  gtw
 SG_ DIS_a088_uiVehicleModes m88 : 19|1@1+ (1,0) [0|1] ""  gtw
 SG_ DIS_a117_slaveCommand2 m117 : 19|1@1+ (1,0) [0|1] ""  gtw
 SG_ DIS_a002_undervoltVH_H m2 : 19|1@1+ (1,0) [0|1] ""  gtw
 SG_ DIS_a106_ECB1S03 m106 : 19|1@1+ (1,0) [0|1] ""  gtw
 SG_ DIS_a121_torqueDelta m121 : 19|13@1- (0.25,0.0) [-750|750] "Nm"  gtw
 SG_ DIS_a035_standbyCurrent m35 : 19|1@1+ (1,0) [0|1] ""  gtw
 SG_ DIS_a144_performancePackage m144 : 19|1@1+ (1,0) [0|1] ""  gtw
 SG_ DIS_a003_undervoltVH_H m3 : 19|1@1+ (1,0) [0|1] ""  gtw
 SG_ DIS_a092_bmsPowerAvailable m92 : 19|1@1+ (1,0) [0|1] ""  gtw
 SG_ DIS_a090_state2 m90 : 19|1@1+ (1,0) [0|1] ""  gtw
 SG_ DIS_a091_ESP_motorLimits m91 : 19|1@1+ (1,0) [0|1] ""  gtw
 SG_ DIS_a011_phaseALow m11 : 19|1@1+ (1,0) [0|1] ""  gtw
 SG_ DIS_a099_thread100Hz m99 : 19|1@1+ (1,0) [0|1] ""  gtw
 SG_ DIS_a096_mem_data m96 : 19|1@1+ (1,0) [0|1] ""  gtw
 SG_ DIS_a155_vehicleStatus m155 : 19|1@1+ (1,0) [0|1] ""  gtw
 SG_ DIS_a040_status m40 : 19|1@1+ (1,0) [0|1] ""  gtw
 SG_ DIS_a225_hsDeltaImplausible m225 : 19|1@1+ (1,0) [0|1] ""  gtw
 SG_ DIS_a202_movement m202 : 19|9@1+ (0.005,0) [0|2.5] "m"  gtw
 SG_ DIS_a087_gtwUpdateStatus m87 : 18|1@1+ (1,0) [0|1] ""  gtw
 SG_ DIS_a091_ESP_wheelRotation m91 : 18|1@1+ (1,0) [0|1] ""  gtw
 SG_ DIS_a088_uiPowertrainControl m88 : 18|1@1+ (1,0) [0|1] ""  gtw
 SG_ DIS_a035_phaseCerror m35 : 18|1@1+ (1,0) [0|1] ""  gtw
 SG_ DIS_a106_ABS_E m106 : 18|1@1+ (1,0) [0|1] ""  gtw
 SG_ DIS_a096_text_flash m96 : 18|1@1+ (1,0) [0|1] ""  gtw
 SG_ DIS_a001_undervoltVL_H m1 : 18|1@1+ (1,0) [0|1] ""  gtw
 SG_ DIS_a011_phaseAHigh m11 : 18|1@1+ (1,0) [0|1] ""  gtw
 SG_ DIS_a244_flybackFault m244 : 18|1@1+ (1,0) [0|1] ""  gtw
 SG_ DIS_a156_observation m156 : 18|4@1+ (1,0) [0|10] ""  gtw
 SG_ DIS_a155_LVPowerState m155 : 18|1@1+ (1,0) [0|1] ""  gtw
 SG_ DIS_a061_reason m61 : 18|1@1+ (1,0) [0|1] ""  gtw
 SG_ DIS_a016_oldSafeState m16 : 18|2@1+ (1,0) [0|3] ""  gtw
 SG_ DIS_a002_undervoltVL_H m2 : 18|1@1+ (1,0) [0|1] ""  gtw
 SG_ DIS_a092_bmsHvBusStatus m92 : 18|1@1+ (1,0) [0|1] ""  gtw
 SG_ DIS_a090_crossCheck m90 : 18|1@1+ (1,0) [0|1] ""  gtw
 SG_ DIS_a003_undervoltVL_H m3 : 18|1@1+ (1,0) [0|1] ""  gtw
 SG_ DIS_a144_packEnergy m144 : 18|1@1+ (1,0) [0|1] ""  gtw
 SG_ DIS_a225_fluidImplausible m225 : 18|1@1+ (1,0) [0|1] ""  gtw
 SG_ DIS_a099_thread10Hz m99 : 18|1@1+ (1,0) [0|1] ""  gtw
 SG_ DIS_a117_power m117 : 18|1@1+ (1,0) [0|1] ""  gtw
 SG_ DIS_a040_power m40 : 18|1@1+ (1,0) [0|1] ""  gtw
 SG_ DIS_a002_thermalShutdown_H m2 : 17|1@1+ (1,0) [0|1] ""  gtw
 SG_ DIS_a110_EPBR_status m110 : 17|1@1+ (1,0) [0|1] ""  gtw
 SG_ DIS_a040_capability m40 : 17|1@1+ (1,0) [0|1] ""  gtw
 SG_ DIS_a003_thermalShutdown_H m3 : 17|1@1+ (1,0) [0|1] ""  gtw
 SG_ DIS_a157_RCM_inertial2 m157 : 17|1@1+ (1,0) [0|1] ""  gtw
 SG_ DIS_a155_coolant m155 : 17|1@1+ (1,0) [0|1] ""  gtw
 SG_ DIS_a092_bmsDriveLimits m92 : 17|1@1+ (1,0) [0|1] ""  gtw
 SG_ DIS_a096_text_fast m96 : 17|1@1+ (1,0) [0|1] ""  gtw
 SG_ DIS_a244_singleSwitchShort m244 : 17|1@1+ (1,0) [0|1] ""  gtw
 SG_ DIS_a088_uiCruiseControl m88 : 17|1@1+ (1,0) [0|1] ""  gtw
 SG_ DIS_a106_ABS_C m106 : 17|1@1+ (1,0) [0|1] ""  gtw
 SG_ DIS_a091_ESP_wheelSpeeds m91 : 17|1@1+ (1,0) [0|1] ""  gtw
 SG_ DIS_a087_gtwTime m87 : 17|1@1+ (1,0) [0|1] ""  gtw
 SG_ DIS_a143_systemTorqueLimit m143 : 17|1@1+ (1,0) [0|1] ""  gtw
 SG_ DIS_a090_state m90 : 17|1@1+ (1,0) [0|1] ""  gtw
 SG_ DIS_a161_EPAS3P_angleCalib m161 : 17|1@1+ (1,0) [0|1] ""  gtw
 SG_ DIS_a225_hs2Implausible m225 : 17|1@1+ (1,0) [0|1] ""  gtw
 SG_ DIS_a001_thermalShutdown_H m1 : 17|1@1+ (1,0) [0|1] ""  gtw
 SG_ DIS_a144_drivetrainType m144 : 17|1@1+ (1,0) [0|1] ""  gtw
 SG_ DIS_a117_slaveCommand m117 : 17|1@1+ (1,0) [0|1] ""  gtw
 SG_ DIS_a099_thread1Hz m99 : 17|1@1+ (1,0) [0|1] ""  gtw
 SG_ DIS_a035_phaseBerror m35 : 17|1@1+ (1,0) [0|1] ""  gtw
 SG_ DIS_a158_IBST_status m158 : 17|1@1+ (1,0) [0|1] ""  gtw
 SG_ DIS_a075_motorSpeed m75 : 16|16@1+ (1,0) [0|65535] "RPM"  gtw
 SG_ DIS_a097_errorType m97 : 16|3@1+ (1,0) [0|6] ""  gtw
 SG_ DIS_a148_overtorque1UsedCount m148 : 16|10@1+ (1,0) [0|1023] ""  gtw
 SG_ DIS_a054_outletTemp m54 : 16|16@1- (0.1,0) [-3276.8|3276.7] "C"  gtw
 SG_ DIS_a091_ESP_brakeTorque m91 : 16|1@1+ (1,0) [0|1] ""  gtw
 SG_ DIS_a121_badRegReason m121 : 16|3@1+ (1,0) [1|5] ""  gtw
 SG_ DIS_a061_sensor m61 : 16|2@1+ (1,0) [0|2] ""  gtw
 SG_ DIS_a014_motorSpeed m14 : 16|14@1- (2,0) [-16000|16000] "RPM"  gtw
 SG_ DIS_a122_taskID m122 : 16|4@1+ (1,0) [0|8] ""  gtw
 SG_ DIS_a157_RCM_inertial1 m157 : 16|1@1+ (1,0) [0|1] ""  gtw
 SG_ DIS_a126_limpReason m126 : 16|5@1+ (1,0) [0|30] ""  gtw
 SG_ DIS_a106_ABS_A m106 : 16|1@1+ (1,0) [0|1] ""  gtw
 SG_ DIS_a038_vBMS m38 : 16|12@1+ (0.2,0) [0|819] "V"  gtw
 SG_ DIS_a031_phaseAoffset m31 : 16|16@1- (0.002,0) [-65.536|65.534] "A"  gtw
 SG_ DIS_a071_busVslopeLimit m71 : 16|16@1+ (0.1,0) [0|6553.5] "V/ms"  gtw
 SG_ DIS_a074_brazeFailCount m74 : 16|8@1+ (1,0) [0|255] ""  gtw
 SG_ DIS_a094_canID m94 : 16|12@1+ (1,0) [0|4095] ""  gtw
 SG_ DIS_a011_reason m11 : 16|2@1+ (1,0) [0|3] ""  gtw
 SG_ DIS_a241_statorEndWindingTemp m241 : 16|8@1- (1,88) [-40|215] "degC"  gtw
 SG_ DIS_a044_outletTemp m44 : 16|16@1- (0.1,0) [-3276.8|3276.7] "C"  gtw
 SG_ DIS_a117_torque m117 : 16|1@1+ (1,0) [0|1] ""  gtw
 SG_ DIS_a073_motorSpeedrpm m73 : 16|16@1- (1,0) [-32768|32767] "RPM"  gtw
 SG_ DIS_a143_mechPowerLimit m143 : 16|1@1+ (1,0) [0|1] ""  gtw
 SG_ DIS_a059_heatsinkTemp m59 : 16|16@1- (0.1,0) [-3276.8|3276.7] "C"  gtw
 SG_ DIS_a160_vBatRawMinusFiltered m160 : 16|10@1- (1,0) [-512|511] "V"  gtw
 SG_ DIS_a064_interventionType m64 : 16|4@1+ (1,0) [0|10] ""  gtw
 SG_ DIS_a134_wheelSpeedDiffFrL m134 : 16|12@1- (0.0625,0) [-256|255] "kph"  gtw
 SG_ DIS_a030_phaseCirms m30 : 16|16@1+ (1,0) [0|65535] "A"  gtw
 SG_ DIS_a156_initialSafeState m156 : 16|2@1+ (1,0) [0|3] ""  gtw
 SG_ DIS_a225_hs1Implausible m225 : 16|1@1+ (1,0) [0|1] ""  gtw
 SG_ DIS_a065_canID m65 : 16|16@1+ (1,0) [0|65535] ""  gtw
 SG_ DIS_a079_adcRefChan m79 : 16|4@1+ (1,0) [0|15] ""  gtw
 SG_ DIS_a244_desat m244 : 16|1@1+ (1,0) [0|1] ""  gtw
 SG_ DIS_a112_phaseAcurrent m112 : 16|16@1+ (1,0) [0|65535] "A"  gtw
 SG_ DIS_a090_reason m90 : 16|1@1+ (1,0) [0|1] ""  gtw
 SG_ DIS_a003_thermalWarning_H m3 : 16|1@1+ (1,0) [0|1] ""  gtw
 SG_ DIS_a161_EPAS3P_sysStatus m161 : 16|1@1+ (1,0) [0|1] ""  gtw
 SG_ DIS_a058_pcbTemp m58 : 16|10@1+ (0.25,-60) [-60|195] "DegC"  gtw
 SG_ DIS_a127_gpoReason m127 : 16|4@1+ (1,0) [0|8] ""  gtw
 SG_ DIS_a062_limpReason m62 : 16|5@1+ (1,0) [0|30] ""  gtw
 SG_ DIS_a142_lashAngle m142 : 16|10@1+ (0.06,0) [0|60] "Deg"  gtw
 SG_ DIS_a114_motorSpeed m114 : 16|16@1+ (1,0) [0|65535] "RPM"  gtw
 SG_ DIS_a046_statorTemp1 m46 : 16|16@1- (0.1,0) [-3276.8|3276.7] "DegC"  gtw
 SG_ DIS_a149_speed m149 : 16|8@1+ (0.4,0) [0|100] "%"  gtw
 SG_ DIS_a029_phaseBirms m29 : 16|16@1+ (1,0) [0|65535] "A"  gtw
 SG_ DIS_a036_busVoltage m36 : 16|16@1+ (0.1,0) [0|6553.5] "V"  gtw
 SG_ DIS_a152_errorType m152 : 16|3@1+ (1,0) [0|6] ""  gtw
 SG_ DIS_a234_PCS_dcdcStatus m234 : 16|1@1+ (1,0) [0|1] ""  gtw
 SG_ DIS_a116_elecPower m116 : 16|16@1- (0.5,0) [-16384|16383.5] "KW"  gtw
 SG_ DIS_a151_torqueMotor m151 : 16|16@1- (0.25,0) [-750|750] "Nm"  gtw
 SG_ DIS_a136_spiErrorType m136 : 16|3@1+ (1,0) [0|7] ""  gtw
 SG_ DIS_a056_pcbTemp m56 : 16|16@1- (0.1,0) [-3276.8|3276.7] "C"  gtw
 SG_ DIS_a077_12vSupply m77 : 16|16@1+ (0.001,0) [0|65.535] "V"  gtw
 SG_ DIS_a113_ph1Temp m113 : 16|16@1- (0.1,0) [-3276.8|3276.7] "C"  gtw
 SG_ DIS_a028_phaseAirms m28 : 16|16@1+ (1,0) [0|65535] "A"  gtw
 SG_ DIS_a147_overtorque1UsedCount m147 : 16|8@1+ (1,0) [0|255] ""  gtw
 SG_ DIS_a047_statorTemp1 m47 : 16|16@1- (0.1,0) [-3276.8|3276.7] "DegC"  gtw
 SG_ DIS_a032_phaseBoffset m32 : 16|16@1- (0.002,0) [-65.536|65.534] "A"  gtw
 SG_ DIS_a087_gtwCarConfig m87 : 16|1@1+ (1,0) [0|1] ""  gtw
 SG_ DIS_a150_vBatRawMinusFiltered m150 : 16|10@1- (1,0) [-512|511] "V"  gtw
 SG_ DIS_a040_torque m40 : 16|1@1+ (1,0) [0|1] ""  gtw
 SG_ DIS_a078_adcRefChan m78 : 16|4@1+ (1,0) [0|15] ""  gtw
 SG_ DIS_a243_logId m243 : 16|4@1+ (1,0) [0|15] ""  gtw
 SG_ DIS_a055_parameterDI m55 : 16|13@1- (0.25,0.0) [-750|750] "Nm"  gtw
 SG_ DIS_a154_motorRPM m154 : 16|16@1- (1,0) [-20000|20000] "RPM"  gtw
 SG_ DIS_a155_sensors m155 : 16|1@1+ (1,0) [0|1] ""  gtw
 SG_ DIS_a202_reason m202 : 16|3@1+ (1,0) [0|7] ""  gtw
 SG_ DIS_a103_fluidDeltaT m103 : 16|12@1- (0.1,67.5) [-60|195] "C"  gtw
 SG_ DIS_a002_thermalWarning_H m2 : 16|1@1+ (1,0) [0|1] ""  gtw
 SG_ DIS_a033_phaseAcurrent m33 : 16|16@1- (1,0) [-32768|32767] "A"  gtw
 SG_ DIS_a057_pcbTemp m57 : 16|16@1- (0.1,0) [-3276.8|3276.7] "C"  gtw
 SG_ DIS_a076_12vSupply m76 : 16|16@1+ (0.001,0) [0|65.535] "V"  gtw
 SG_ DIS_a001_thermalWarning_H m1 : 16|1@1+ (1,0) [0|1] ""  gtw
 SG_ DIS_a024_vBat m24 : 16|8@1+ (2,0) [0|510] "V"  gtw
 SG_ DIS_a123_lossReason m123 : 16|2@1+ (1,0) [1|3] ""  gtw
 SG_ DIS_a045_inletTemp m45 : 16|10@1+ (0.25,-60) [-60|195] "DegC"  gtw
 SG_ DIS_a050_statorTemp1 m50 : 16|16@1- (0.1,0) [-3276.8|3276.7] "DegC"  gtw
 SG_ DIS_a037_busVoltage m37 : 16|16@1+ (0.1,0) [0|6553.5] "V"  gtw
 SG_ DIS_a066_badValue1 m66 : 16|16@1+ (1,0) [0|65535] ""  gtw
 SG_ DIS_a133_capacitorTemp m133 : 16|16@1- (0.1,0) [-3276.8|3276.7] "C"  gtw
 SG_ DIS_a016_newSafeState m16 : 16|2@1+ (1,0) [0|3] ""  gtw
 SG_ DIS_a096_const_fast m96 : 16|1@1+ (1,0) [0|1] ""  gtw
 SG_ DIS_a233_missedMsgCount m233 : 16|16@1+ (1,0) [0|65535] ""  gtw
 SG_ DIS_a060_heatsinkTemp m60 : 16|16@1- (0.1,0) [-3276.8|3276.7] "C"  gtw
 SG_ DIS_a095_mailboxID m95 : 16|16@1+ (1,0) [0|65535] ""  gtw
 SG_ DIS_a108_fromState m108 : 16|8@1+ (1,0) [0|255] ""  gtw
 SG_ DIS_a043_outletTemp m43 : 16|16@1- (0.1,0) [-3276.8|3276.7] "C"  gtw
 SG_ DIS_a110_EPBL_status m110 : 16|1@1+ (1,0) [0|1] ""  gtw
 SG_ DIS_a115_ph1Temp m115 : 16|8@1- (1,0) [-128|127] "C"  gtw
 SG_ DIS_a042_inletTemp m42 : 16|10@1+ (0.25,-60) [-60|195] "DegC"  gtw
 SG_ DIS_a098_pwmCount m98 : 16|16@1+ (1,0) [0|65535] ""  gtw
 SG_ DIS_a099_watchdogReset m99 : 16|1@1+ (1,0) [0|1] ""  gtw
 SG_ DIS_a158_IBST_party1 m158 : 16|1@1+ (1,0) [0|1] ""  gtw
 SG_ DIS_a035_phaseAerror m35 : 16|1@1+ (1,0) [0|1] ""  gtw
 SG_ DIS_a144_autopilot m144 : 16|1@1+ (1,0) [0|1] ""  gtw
 SG_ DIS_a067_canID m67 : 16|16@1+ (1,0) [0|65535] ""  gtw
 SG_ DIS_a153_speed m153 : 16|7@1+ (2,0) [0|100] "%"  gtw
 SG_ DIS_a131_totalTimeRemaining m131 : 16|16@1+ (1,0) [0|65535] ""  gtw
 SG_ DIS_a026_rawIb m26 : 16|16@1- (1,0) [-32768|32767] ""  gtw
 SG_ DIS_a092_bmsStatus m92 : 16|1@1+ (1,0) [0|1] ""  gtw
 SG_ DIS_a025_rawIa m25 : 16|16@1- (1,0) [-32768|32767] ""  gtw
 SG_ DIS_a088_uiChassisControl m88 : 16|1@1+ (1,0) [0|1] ""  gtw
 SG_ DIS_a027_rawIc m27 : 16|16@1- (1,0) [-32768|32767] ""  gtw
 SG_ DIS_a034_phaseBcurrent m34 : 16|16@1- (1,0) [-32768|32767] "A"  gtw
 SG_ DIS_a093_mailboxID m93 : 16|16@1+ (1,0) [0|65535] ""  gtw
 SG_ DIS_alertType : 15|1@1+ (1,0) [0|1] ""  gtw
 SG_ DIS_alertID M : 0|8@1+ (1,0) [0|244] ""  gtw

BO_ 583 CMP_HVStatus: 8 VEH
 SG_ CMP_inputHVPower : 40|16@1+ (1,0) [0|65534] "W"  bms
 SG_ CMP_inputHVCurrent : 24|16@1+ (0.1,0) [0|6553.4] "A"  X
 SG_ CMP_inputLVVoltage : 16|8@1+ (0.1,0) [0|25.5] "V"  X
 SG_ CMP_inputHVVoltage : 0|16@1+ (0.1,0) [0|6553.4] "V"  gtw

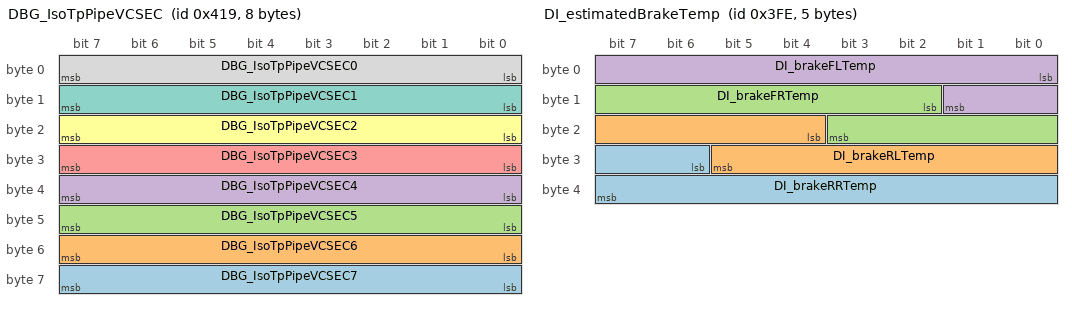
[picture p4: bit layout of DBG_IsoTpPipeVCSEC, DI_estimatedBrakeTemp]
BO_ 1049 DBG_IsoTpPipeVCSEC: 8 VEH
 SG_ DBG_IsoTpPipeVCSEC7 : 56|8@1+ (1,0) [0|255] ""  vcsec
 SG_ DBG_IsoTpPipeVCSEC6 : 48|8@1+ (1,0) [0|255] ""  vcsec
 SG_ DBG_IsoTpPipeVCSEC5 : 40|8@1+ (1,0) [0|255] ""  vcsec
 SG_ DBG_IsoTpPipeVCSEC4 : 32|8@1+ (1,0) [0|255] ""  vcsec
 SG_ DBG_IsoTpPipeVCSEC3 : 24|8@1+ (1,0) [0|255] ""  vcsec
 SG_ DBG_IsoTpPipeVCSEC2 : 16|8@1+ (1,0) [0|255] ""  vcsec
 SG_ DBG_IsoTpPipeVCSEC1 : 8|8@1+ (1,0) [0|255] ""  vcsec
 SG_ DBG_IsoTpPipeVCSEC0 : 0|8@1+ (1,0) [0|255] ""  vcsec

BO_ 1022 DI_estimatedBrakeTemp: 5 VEH
 SG_ DI_brakeRRTemp : 30|10@1+ (1,-40) [-40|982] "DegC"  gtw
 SG_ DI_brakeRLTemp : 20|10@1+ (1,-40) [-40|982] "DegC"  gtw
 SG_ DI_brakeFRTemp : 10|10@1+ (1,-40) [-40|982] "DegC"  gtw
 SG_ DI_brakeFLTemp : 0|10@1+ (1,-40) [-40|982] "DegC"  gtw

BO_ 1889 PM_debug: 8 VEH
 SG_ PM_resolverDiMIA m105 : 57|1@1+ (1,0) [0|1] ""  X
 SG_ PM_cpu10kHzMax m14 : 56|8@1+ (0.4,0) [0|102] "%"  dbg
 SG_ PM_cpu100HzMin m13 : 56|8@1+ (0.4,0) [0|102] "%"  dbg
 SG_ PM_resolverClaMIA m105 : 56|1@1+ (1,0) [0|1] ""  X
 SG_ PM_lmSatCoeff m100 : 56|8@1+ (0.00391,0) [0|0.99705] "1"  dbg
 SG_ PM_statorT m101 : 56|8@1+ (1,-40) [-40|200] "degC"  dbg
 SG_ PM_resolverPhaseOutOfSpec m105 : 55|1@1+ (1,0) [0|1] ""  X
 SG_ PM_resolverNoCarrier m105 : 54|1@1+ (1,0) [0|1] ""  X
 SG_ PM_pedalPos m102 : 48|8@1+ (0.4,0) [0|102] "%"  dbg
 SG_ PM_resolverOffsetExt m105 : 48|6@1+ (0.053,0) [0|3.3] "V"  X
 SG_ PM_cpu20kHzMin m14 : 48|8@1+ (0.4,0) [0|102] "%"  dbg
 SG_ PM_cpu1kHzAvg m13 : 48|8@1+ (0.4,0) [0|102] "%"  dbg
 SG_ PM_torqueOutOfMap m102 : 47|1@1+ (1,0) [0|1] ""  dbg
 SG_ PM_switchingActive m102 : 46|1@1+ (1,0) [0|1] ""  X
 SG_ PM_torqueReversalWindow m12 : 40|16@1- (0.05,0.0) [-1638.4|1638.35] "NmS"  dbg
 SG_ PM_motorRPM m101 : 40|16@1- (1,0) [-32768|32767] "RPM"  dbg
 SG_ PM_cpu20kHzMax m14 : 40|8@1+ (0.4,0) [0|102] "%"  dbg
 SG_ PM_resolverOffsetSin m105 : 40|6@1+ (0.053,0) [0|3.3] "V"  X
 SG_ PM_torqueAccelAvg m11 : 40|16@1- (0.05,0.0) [-1638.4|1638.35] "Nm"  dbg
 SG_ PM_iDQmagnitude m100 : 40|16@1- (0.0939,0) [-3076.9152|3076.8213] "A"  dbg
 SG_ PM_torqueRegenMargin m10 : 40|16@1- (0.0244,0.0) [-799.5392|799.5148] "Nm"  dbg
 SG_ PM_cpu100HzMax m13 : 40|8@1+ (0.4,0) [0|102] "%"  dbg
 SG_ PM_cpu10kHzAvg m13 : 32|8@1+ (0.4,0) [0|102] "%"  dbg
 SG_ PM_resolverOffsetCos m105 : 32|6@1+ (0.053,0) [0|3.3] "V"  X
 SG_ PM_cpu10HzMin m14 : 32|8@1+ (0.4,0) [0|102] "%"  dbg
 SG_ PM_torqueDecelAvg m12 : 24|16@1- (0.05,0.0) [-1638.4|1638.35] "Nm"  dbg
 SG_ PM_Ib m100 : 24|16@1- (0.0939,0) [-3076.9152|3076.8213] "A"  dbg
 SG_ PM_torqueReversalMarginR m10 : 24|16@1- (0.0244,0.0) [-799.5392|799.5148] "Nm"  dbg
 SG_ PM_xcpStackMax m23 : 24|16@1+ (1,0) [0|65535] "words"  dbg
 SG_ PM_udsStackMax m22 : 24|16@1+ (1,0) [0|65535] "words"  dbg
 SG_ PM_cpu10HzAvg m14 : 24|8@1+ (0.4,0) [0|102] "%"  dbg
 SG_ PM_sysStackMax m20 : 24|16@1+ (1,0) [0|65535] "words"  dbg
 SG_ PM_torqueAccelWindow m11 : 24|16@1- (0.05,0.0) [-1638.4|1638.35] "NmS"  dbg
 SG_ PM_cpu1kHzMin m13 : 24|8@1+ (0.4,0) [0|102] "%"  dbg
 SG_ PM_resolverExcitationGain m105 : 24|7@1+ (0.063,0) [0|5] "1"  X
 SG_ PM_lookupSlipFreqMax m101 : 24|16@1- (0.005,0.0) [-163.84|163.835] "Hz"  dbg
 SG_ PM_idleStackMax m21 : 24|16@1+ (1,0) [0|65535] "words"  dbg
 SG_ PM_neutralRequest m51 : 23|1@1+ (1,0) [0|1] ""  X
 SG_ PM_offsetIb m102 : 20|12@1- (0.1,0) [-204.8|204.7] "A"  dbg
 SG_ PM_vehicleHoldState m50 : 19|3@1+ (1,0) [0|7] ""  dbg
 SG_ PM_resolverCommonGain m105 : 17|7@1+ (0.063,0) [0|8] "1"  X
 SG_ PM_cpu10HzMax m14 : 16|8@1+ (0.4,0) [0|102] "%"  dbg
 SG_ PM_aebState m50 : 16|3@1+ (1,0) [0|7] ""  dbg
 SG_ PM_cpu20kHzAvg m13 : 16|8@1+ (0.4,0) [0|102] "%"  dbg
 SG_ PM_resolverSpeedError m104 : 16|16@1- (0.75,0.0) [-25000|25000] "RPM"  X
 SG_ PM_pedalPosB m103 : 16|8@1+ (0.4,0) [0|100] "%"  X
 SG_ PM_cruiseState m50 : 11|3@1+ (1,0) [0|7] ""  dbg
 SG_ PM_cpu10kHzMin m15 : 8|8@1+ (0.4,0) [0|102] "%"  dbg
 SG_ PM_pedalPosA m103 : 8|8@1+ (0.4,0) [0|100] "%"  X
 SG_ PM_udsStackSize m22 : 8|16@1+ (1,0) [0|65535] "words"  dbg
 SG_ PM_systemTorqueCommand m51 : 8|15@1- (0.1,0.0) [-1100|1100] "Nm"  X
 SG_ PM_sysStackSize m20 : 8|16@1+ (1,0) [0|65535] "words"  dbg
 SG_ PM_resolverPhaseAngle m105 : 8|9@1+ (0.001537,0) [0|0.78539816339745] "rad"  X
 SG_ PM_torqueReversalMarginF m10 : 8|16@1- (0.0244,0.0) [-799.5392|799.5148] "Nm"  dbg
 SG_ PM_torqueSignError m11 : 8|16@1- (0.035,0.0) [-1146.88|1146.845] "Nm"  dbg
 SG_ PM_gear m50 : 8|3@1+ (1,0) [0|7] ""  dbg
 SG_ PM_slipFrequency m101 : 8|16@1- (0.005,0.0) [-163.84|163.835] "Hz"  dbg
 SG_ PM_cpu1kHzMax m13 : 8|8@1+ (0.4,0) [0|102] "%"  dbg
 SG_ PM_idleStackSize m21 : 8|16@1+ (1,0) [0|65535] "words"  dbg
 SG_ PM_torqueDecelWindow m12 : 8|16@1- (0.05,0.0) [-1638.4|1638.35] "NmS"  dbg
 SG_ PM_xcpStackSize m23 : 8|16@1+ (1,0) [0|65535] "words"  dbg
 SG_ PM_Ia m100 : 8|16@1- (0.0939,0) [-3076.9152|3076.8213] "A"  dbg
 SG_ PM_resolverElecAngleError m104 : 8|8@1- (0.025,0.0) [-3.14159|3.14159] "rad"  X
 SG_ PM_offsetIa m102 : 8|12@1- (0.1,0) [-204.8|204.7] "A"  dbg
 SG_ PM_cpu100HzAvg m14 : 8|8@1+ (0.4,0) [0|102] "%"  dbg
 SG_ PM_debugSelector M : 0|8@1+ (1,0) [10|105] ""  dbg

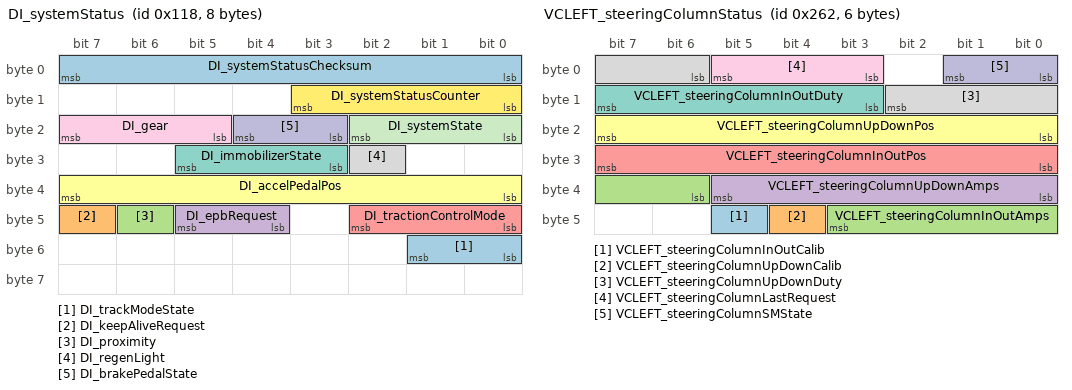
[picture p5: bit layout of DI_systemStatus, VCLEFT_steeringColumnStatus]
BO_ 280 DI_systemStatus: 8 VEH
 SG_ DI_trackModeState : 48|2@1+ (1,0) [0|2] ""  gtw
 SG_ DI_keepAliveRequest : 47|1@1+ (1,0) [0|1] ""  bms
 SG_ DI_proximity : 46|1@1+ (1,0) [0|1] ""  bms
 SG_ DI_epbRequest : 44|2@1+ (1,0) [0|2] ""  epbl
 SG_ DI_tractionControlMode : 40|3@1+ (1,0) [0|5] ""  X
 SG_ DI_accelPedalPos : 32|8@1+ (0.4,0) [0|100] "%"  vcfront
 SG_ DI_immobilizerState : 27|3@1+ (1,0) [0|6] ""  X
 SG_ DI_regenLight : 26|1@1+ (1,0) [0|1] ""  vcleft
 SG_ DI_gear : 21|3@1+ (1,0) [0|7] ""  gtw
 SG_ DI_brakePedalState : 19|2@1+ (1,0) [0|2] ""  vcleft
 SG_ DI_systemState : 16|3@1+ (1,0) [0|5] ""  epbl
 SG_ DI_systemStatusCounter : 8|4@1+ (1,0) [0|15] ""  X
 SG_ DI_systemStatusChecksum : 0|8@1+ (1,0) [0|255] ""  X

BO_ 1132 CC_alertMatrix1: 8 VEH
 SG_ CC_a030_masterSlaveMismatch : 29|1@1+ (1,0) [0|1] ""  gtw
 SG_ CC_a029_PilotFFault : 28|1@1+ (1,0) [0|1] ""  gtw
 SG_ CC_a028_CB_rotarySelect : 27|1@1+ (1,0) [0|1] ""  gtw
 SG_ CC_a027_vehicleHandleTemp : 26|1@1+ (1,0) [0|1] ""  gtw
 SG_ CC_a026_wallPlugTemp : 25|1@1+ (1,0) [0|1] ""  gtw
 SG_ CC_a025_evseTemp : 24|1@1+ (1,0) [0|1] ""  gtw
 SG_ CC_a024_CB_masterISetTooLow : 23|1@1+ (1,0) [0|1] ""  gtw
 SG_ CC_a023_CB_tooManySlaves : 22|1@1+ (1,0) [0|1] ""  gtw
 SG_ CC_a022_CB_tooManyMasters : 21|1@1+ (1,0) [0|1] ""  gtw
 SG_ CC_a021_CB_noMaster : 20|1@1+ (1,0) [0|1] ""  gtw
 SG_ CC_a020_3vRailIncorrect : 19|1@1+ (1,0) [0|1] ""  gtw
 SG_ CC_a019_proxDisconnected : 18|1@1+ (1,0) [0|1] ""  gtw
 SG_ CC_a018_PilotDFault : 17|1@1+ (1,0) [0|1] ""  gtw
 SG_ CC_a017_PilotCFault : 16|1@1+ (1,0) [0|1] ""  gtw
 SG_ CC_a016_PilotBFault : 15|1@1+ (1,0) [0|1] ""  gtw
 SG_ CC_a015_PilotAFault : 14|1@1+ (1,0) [0|1] ""  gtw
 SG_ CC_a014_mcuSelfTestFault : 13|1@1+ (1,0) [0|1] ""  gtw
 SG_ CC_a013_vehConnOT : 12|1@1+ (1,0) [0|1] ""  gtw
 SG_ CC_a012_wallPlugOT : 11|1@1+ (1,0) [0|1] ""  gtw
 SG_ CC_a011_ambientOT : 10|1@1+ (1,0) [0|1] ""  gtw
 SG_ CC_a010_contactorWelded : 9|1@1+ (1,0) [0|1] ""  gtw
 SG_ CC_a009_inputMiswired : 8|1@1+ (1,0) [0|1] ""  gtw
 SG_ CC_a008_inputUnderVoltage : 7|1@1+ (1,0) [0|1] ""  gtw
 SG_ CC_a007_inputOverVoltage : 6|1@1+ (1,0) [0|1] ""  gtw
 SG_ CC_a006_inputOverCurrent : 5|1@1+ (1,0) [0|1] ""  gtw
 SG_ CC_a005_groundedNeutral : 4|1@1+ (1,0) [0|1] ""  gtw
 SG_ CC_a004_CCIDSelfTestFault : 3|1@1+ (1,0) [0|1] ""  gtw
 SG_ CC_a003_CCIDTripped : 2|1@1+ (1,0) [0|1] ""  gtw
 SG_ CC_a002_gndMonIntrptLoadSide : 1|1@1+ (1,0) [0|1] ""  gtw
 SG_ CC_a001_gndMonIntrptLineSide : 0|1@1+ (1,0) [0|1] ""  gtw

BO_ 610 VCLEFT_steeringColumnStatus: 6 VEH
 SG_ VCLEFT_steeringColumnInOutCalib : 45|1@1+ (1,0) [0|1] ""  X
 SG_ VCLEFT_steeringColumnUpDownCalib : 44|1@1+ (1,0) [0|1] ""  X
 SG_ VCLEFT_steeringColumnInOutAmps : 38|6@1- (0.63,0.0) [-20|20] "A"  X
 SG_ VCLEFT_steeringColumnUpDownAmps : 32|6@1- (0.63,0.0) [-20|20] "A"  X
 SG_ VCLEFT_steeringColumnInOutPos : 24|8@1- (12,1284) [-200|2750] "ticks"  gtw
 SG_ VCLEFT_steeringColumnUpDownPos : 16|8@1- (12,1284) [-200|2750] "ticks"  gtw
 SG_ VCLEFT_steeringColumnInOutDuty : 11|5@1- (7,0) [-100|100] "%"  X
 SG_ VCLEFT_steeringColumnUpDownDuty : 6|5@1- (7,0) [-100|100] "%"  X
 SG_ VCLEFT_steeringColumnLastRequest : 3|3@1+ (1,0) [0|5] ""  X
 SG_ VCLEFT_steeringColumnSMState : 0|2@1+ (1,0) [0|3] ""  gtw

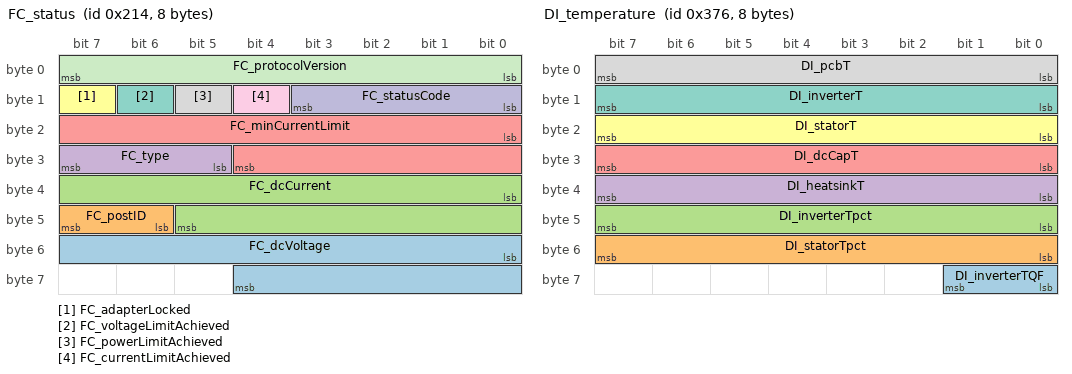
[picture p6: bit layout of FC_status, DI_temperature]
BO_ 532 FC_status: 8 VEH
 SG_ FC_dcVoltage : 48|13@1+ (0.07324218755,0) [0|599.92675822] "V"  gtw
 SG_ FC_postID : 46|2@1+ (1,0) [0|3] ""  gtw
 SG_ FC_dcCurrent : 32|14@1- (0.0732421875,0) [-600|599.92675781] "A"  gtw
 SG_ FC_type : 29|3@1+ (1,0) [0|7] ""  gtw
 SG_ FC_minCurrentLimit : 16|13@1+ (0.1,0) [0|600] "A"  X
 SG_ FC_adapterLocked : 15|1@1+ (1,0) [0|1] ""  gtw
 SG_ FC_voltageLimitAchieved : 14|1@1+ (1,0) [0|1] ""  X
 SG_ FC_powerLimitAchieved : 13|1@1+ (1,0) [0|1] ""  X
 SG_ FC_currentLimitAchieved : 12|1@1+ (1,0) [0|1] ""  X
 SG_ FC_statusCode : 8|4@1+ (1,0) [0|15] ""  gtw
 SG_ FC_protocolVersion : 0|8@1+ (1,0) [0|255] ""  dbg

BO_ 886 DI_temperature: 8 VEH
 SG_ DI_inverterTQF : 56|2@1+ (1,0) [0|3] ""  gtw
 SG_ DI_statorTpct : 48|8@1+ (0.4,0) [0|100] "%"  gtw
 SG_ DI_inverterTpct : 40|8@1+ (0.4,0) [0|100] "%"  gtw
 SG_ DI_heatsinkT : 32|8@1+ (1,-40) [-40|120] "DegC"  gtw
 SG_ DI_dcCapT : 24|8@1+ (1,-40) [-40|120] "DegC"  X
 SG_ DI_statorT : 16|8@1+ (1,-40) [-40|200] "DegC"  gtw
 SG_ DI_inverterT : 8|8@1+ (1,-40) [-40|120] "DegC"  gtw
 SG_ DI_pcbT : 0|8@1+ (1,-40) [-40|120] "DegC"  gtw

BA_DEF_ SG_  "SystemSignalLongSymbol" STRING ;
BA_DEF_DEF_  "SystemSignalLongSymbol" "";
VAL_ 1356 SCM_alertType 0 "ALERT_CLEARED" 1 "ALERT_SET" ;
VAL_ 1356 SCM_alertID 31 "SCM_a031_IbatOC" 92 "SCM_a092_cabEnableDeasserted" 77 "SCM_a077_unexpectedVbatBehavior" 62 "SCM_a062_unused" 4 "SCM_a004_hwVbusOV" 11 "SCM_a011_hwIllegalCntrCmdInt" 50 "SCM_a050_coolantTempRationality" 26 "SCM_a026_internalIsolationLow" 15 "SCM_a015_unusedHW15" 6 "SCM_a006_hwWeld_V1" 19 "SCM_a019_unusedHW19" 29 "SCM_a029_VbatOV" 20 "SCM_a020_unusedHW20" 17 "SCM_a017_unusedHW17" 64 "SCM_a064_vehicleCommandTimeout" 10 "SCM_a010_hwIllegalCntrCmdV1" 68 "SCM_a068_vBatRationalityStage4" 9 "SCM_a009_hwOpen_V2" 53 "SCM_a053_unexpectedThermalBehavi" 38 "SCM_a038_contactorFailedOpen" 5 "SCM_a005_hwHVIL" 74 "SCM_a074_isoVDiffHi" 94 "SCM_a094_unused94" 98 "SCM_a098_unused98" 85 "SCM_a085_unused85" 14 "SCM_a014_coolantTempHiFoldBk" 36 "SCM_a036_internalContactorWelded" 72 "SCM_a072_gtwMIA" 51 "SCM_a051_cordTempRationality" 96 "SCM_a096_unused96" 43 "SCM_a043_pilotRationality" 34 "SCM_a034_IBatRationality" 80 "SCM_a080_lccFaulted" 2 "SCM_a002_hwIbatOC" 70 "SCM_a070_vStageRationalityV2" 12 "SCM_a012_hwIllegalCntrCmdV2" 24 "SCM_a024_emergencyShutdown" 48 "SCM_a048_ambientOT" 81 "SCM_a081_rmsInputVoltageHigh" 57 "SCM_a057_watchdogReset" 58 "SCM_a058_adcRef" 52 "SCM_a052_ambientTempRationality" 46 "SCM_a046_coolantOT" 78 "SCM_a078_voltageMatchTimeout" 61 "SCM_a061_postOutOfService" 59 "SCM_a059_memoryError" 82 "SCM_a082_VbatUV" 76 "SCM_a076_bmsMIA" 39 "SCM_a039_ibatRegulation" 28 "SCM_a028_isolationRationality" 27 "SCM_a027_externalIsolationLow" 91 "SCM_a091_voltageRiseDetection" 30 "SCM_a030_VbusOV" 42 "SCM_a042_pilotOutOfRange" 16 "SCM_a016_unusedHW16" 87 "SCM_a087_posCordTempRationality" 40 "SCM_a040_plus12VOutOfRange" 1 "SCM_a001_hwDSPfault" 8 "SCM_a008_hwOpen_V1" 21 "SCM_a021_unusedHW21" 71 "SCM_a071_chargerMIA" 44 "SCM_a044_proximityRationality" 18 "SCM_a018_unusedHW18" 55 "SCM_a055_coolantLevelLow" 32 "SCM_a032_VBatRationality" 25 "SCM_a025_internalIsolationFault" 7 "SCM_a007_hwWeld_V2" 60 "SCM_a060_swHVIL" 66 "SCM_a066_vBatRationalityStage2" 86 "SCM_a086_lccResetDetected" 67 "SCM_a067_vBatRationalityStage3" 65 "SCM_a065_vBatRationalityStage1" 95 "SCM_a095_unused95" 100 "SCM_a100_unused100" 113 "SCM_a113_unused113" 117 "SCM_a117_unused117" 41 "SCM_a041_minus12VOutOfRange" 69 "SCM_a069_vStageRationalityV1" 56 "SCM_a056_stateTransitionDenied" 118 "SCM_a118_unused118" 99 "SCM_a099_unused99" 114 "SCM_a114_unused114" 90 "SCM_a090_negCordOT" 93 "SCM_a093_unused93" 112 "SCM_a112_unused112" 125 "SCM_a125_unused125" 123 "SCM_a123_unused123" 108 "SCM_a108_unused108" 124 "SCM_a124_unused124" 126 "SCM_a126_unused126" 106 "SCM_a106_unused106" 122 "SCM_a122_unused122" 120 "SCM_a120_unused120" 109 "SCM_a109_unused109" 88 "SCM_a088_negCordTempRationality" 119 "SCM_a119_unused119" 104 "SCM_a104_unused104" 89 "SCM_a089_posCordOT" 84 "SCM_a084_unused84" 107 "SCM_a107_unused107" 103 "SCM_a103_unused103" 83 "SCM_a083_chargeCurrentLimited" 101 "SCM_a101_unused101" 97 "SCM_a097_unused97" 111 "SCM_a111_unused111" 115 "SCM_a115_unused115" 105 "SCM_a105_unused105" 110 "SCM_a110_unused110" 128 "SCM_a128_unused128" 121 "SCM_a121_unused121" 116 "SCM_a116_unused116" 127 "SCM_a127_unused127" 102 "SCM_a102_unused102" 33 "SCM_a033_VBusRationality" 63 "SCM_a063_canRationality" 49 "SCM_a049_pcbaTempRationality" 0 "SCM_ALERT_DO_NOT_USE_ZERO" 47 "SCM_a047_cordOT" 45 "SCM_a045_pcbaOT" 79 "SCM_a079_unexpectedVbat" 75 "SCM_a075_leakageTestAbsDecayLow" 37 "SCM_a037_outputContactorWelded" 54 "SCM_a054_pumpRegulation" 73 "SCM_a073_lccMIA" 13 "SCM_a013_cordTempHiFoldBk" 35 "SCM_a035_unexpectedVbusBehavior" 3 "SCM_a003_hwCordOT" ;
VAL_ 616 DI_sysRegenPowerMax 255 "SNA" ;
VAL_ 616 DI_sysDrivePowerMax 511 "SNA" ;
VAL_ 1874 BMS_dbgHviFaultConfinement 1 "ERROR_PASSIVE" 0 "ERROR_ACTIVE" 2 "BUS_OFF" ;
VAL_ 1874 BMS_dbgHvsFaultConfinement 1 "ERROR_PASSIVE" 0 "ERROR_ACTIVE" 2 "BUS_OFF" ;
VAL_ 1874 BMS_fcLinkLeakageTestStatus 3 "FC_LINK_TEST_FAILED" 1 "FC_LINK_TEST_IN_PROGRESS" 4 "FC_LINK_TEST_RETRY" 2 "FC_LINK_TEST_PASSED" 0 "FC_LINK_TEST_NOT_RUN" ;
VAL_ 1874 BMS_energyWalkId 1 "BMS_ENERGY_WALK_DISCHARGE_FULL_PACK" 2 "BMS_ENERGY_WALK_DISCHARGE_CHARGE_TARGET" 0 "BMS_ENERGY_WALK_DISCHARGE_NOMINAL" 3 "BMS_ENERGY_WALK_DISCHARGE_IDEAL" 4 "BMS_ENERGY_WALK_INVALID" ;
VAL_ 1874 BMS_dbgChargeState 15 "CHARGE_STATE_FAULT" 2 "CHARGE_STATE_DC_EXT_ISO_CHECK" 7 "CHARGE_STATE_AC_DISABLE_PCS" 6 "CHARGE_STATE_DC_DISABLING_CHARGER" 3 "CHARGE_STATE_DC_ENABLE_FCLINK" 4 "CHARGE_STATE_AC_ENABLE_PCS" 5 "CHARGE_STATE_CHARGING_ACTIVE" 1 "CHARGE_STATE_ENABLE_DCLINK" 0 "CHARGE_STATE_INACTIVE" ;
VAL_ 1874 BMS_100HzDebug_Id 2 "BMS_100HZ_DBG_UNUSED" 6 "BMS_100HZ_DBG_CAN_BUS_STATUS" 7 "BMS_100HZ_DBG_END" 5 "BMS_100HZ_DBG_BMS_ENERGY_1" 4 "BMS_100HZ_DBG_BMS_ENERGY_0" 1 "BMS_100HZ_DBG_CHARGE_IREG_0" 0 "BMS_100HZ_DBG_CHARGE_VREG_0" 3 "BMS_100HZ_DBG_BMS_STATE_FLAGS" ;
VAL_ 2005 DIS_magnetTempEst 0 "SNA" ;
VAL_ 2005 DIS_oilPumpPressureEstimate 255 "SNA" ;
VAL_ 2005 DIS_oilPumpPhaseAdvance 255 "SNA" ;
VAL_ 2005 DIS_tcMinRequest 255 "SNA" ;
VAL_ 2005 DIS_fluxState 2 "DI_FLUXSTATE_STANDBY" 0 "DI_FLUXSTATE_START" 5 "DI_FLUXSTATE_ENABLED" 1 "DI_FLUXSTATE_TEST" 7 "DI_FLUXSTATE_VCONTROL" 4 "DI_FLUXSTATE_FLUX_DOWN" 9 "DI_FLUXSTATE_FAULT" 3 "DI_FLUXSTATE_FLUX_UP" 6 "DI_FLUXSTATE_ICONTROL" ;
VAL_ 2005 DIS_oilPumpPhaseVoltage 255 "SNA" ;
VAL_ 2005 DIS_tcMaxRequest 255 "SNA" ;
VAL_ 2005 DIS_powerStageSafeState 0 "PSTG_SAFESTATE_NONE" 3 "PSTG_SAFESTATE_3PS_LOW" 2 "PSTG_SAFESTATE_3PS_HIGH" 1 "PSTG_SAFESTATE_ALL_OFF" ;
VAL_ 2005 DIS_usmState 7 "USM_STATE_WAIT_FOR_RETRY" 3 "USM_STATE_ABORT" 0 "USM_STATE_START" 2 "USM_STATE_RETRY" 4 "USM_STATE_ENABLE" 1 "USM_STATE_STANDBY" 6 "USM_STATE_UNAVAILABLE" 5 "USM_STATE_FAULT" ;
VAL_ 2005 DIS_gateDriveState 3 "PSTG_GD_STATE_CONFIGURED" 4 "PSTG_GD_STATE_NOT_CONFIGURED" 2 "PSTG_GD_STATE_CONFIGURING" 0 "PSTG_GD_STATE_INIT" 1 "PSTG_GD_STATE_SELFTEST" ;
VAL_ 2005 DIS_motorType 18 "DI_MOTOR_PM216B" 7 "DI_MOTOR_M7M6" 0 "DI_MOTOR_SNA" 23 "DI_MOTOR_PM216D" 21 "DI_MOTOR_PM216C" 10 "DI_MOTOR_F1AC" 2 "DI_MOTOR_ROADSTER_SPORT" 14 "DI_MOTOR_F2AE" 20 "DI_MOTOR_IM216A" 25 "DI_MOTOR_IM130D_AL" 19 "DI_MOTOR_IM100B" 1 "DI_MOTOR_ROADSTER_BASE" 9 "DI_MOTOR_SSR1A" 5 "DI_MOTOR_M7M5" 24 "DI_MOTOR_IM130D" 16 "DI_MOTOR_PM216A" 13 "DI_MOTOR_F2AD" 6 "DI_MOTOR_M8A" 3 "DI_MOTOR_M7M3" 15 "DI_MOTOR_F2APMSRM" 17 "DI_MOTOR_IM100A" 4 "DI_MOTOR_M7M4" 8 "DI_MOTOR_F1A" 12 "DI_MOTOR_F2AC" 22 "DI_MOTOR_IM130C" 11 "DI_MOTOR_F2AB" ;
VAL_ 2005 DIS_velocityEstimatorState 0 "VE_STATE_NOT_INITIALIZED" 1 "VE_STATE_WHEELS_NORMAL" 3 "VE_STATE_BACKUP_WHEELS_B" 2 "VE_STATE_BACKUP_WHEELS_A" 4 "VE_STATE_BACKUP_MOTOR" ;
VAL_ 2005 DIS_gateDriveSupplyState 1 "PSTG_GD_SUPPLY_RISING" 2 "PSTG_GD_SUPPLY_UP" 0 "PSTG_GD_SUPPLY_DOWN" 3 "PSTG_GD_SUPPLY_FALLING" ;
VAL_ 2005 DIS_oilPumpPhaseCurrent 255 "SNA" ;
VAL_ 1860 VCLEFT_mirrorRecallStatus 3 "RECALL_INTERRUPTED" 1 "RECALL_IN_PROGRESS" 2 "RECALL_COMPLETE" 0 "RECALL_SNA" ;
VAL_ 1860 VCLEFT_columnRecallStatus 3 "RECALL_INTERRUPTED" 1 "RECALL_IN_PROGRESS" 2 "RECALL_COMPLETE" 0 "RECALL_SNA" ;
VAL_ 1860 VCLEFT_seatRecallStatus 3 "RECALL_INTERRUPTED" 1 "RECALL_IN_PROGRESS" 2 "RECALL_COMPLETE" 0 "RECALL_SNA" ;
VAL_ 1860 VCLEFT_systemRecallStatus 3 "RECALL_INTERRUPTED" 1 "RECALL_IN_PROGRESS" 2 "RECALL_COMPLETE" 0 "RECALL_SNA" ;
VAL_ 578 VCLEFT_lumbarLVState 1 "LV_ON" 2 "LV_GOING_DOWN" 3 "LV_FAULT" 0 "LV_OFF" ;
VAL_ 578 VCLEFT_swcLVState 1 "LV_ON" 2 "LV_GOING_DOWN" 3 "LV_FAULT" 0 "LV_OFF" ;
VAL_ 578 VCLEFT_cpLVState 1 "LV_ON" 2 "LV_GOING_DOWN" 3 "LV_FAULT" 0 "LV_OFF" ;
VAL_ 578 VCLEFT_diLVState 1 "LV_ON" 2 "LV_GOING_DOWN" 3 "LV_FAULT" 0 "LV_OFF" ;
VAL_ 578 VCLEFT_sccmLVState 1 "LV_ON" 2 "LV_GOING_DOWN" 3 "LV_FAULT" 0 "LV_OFF" ;
VAL_ 578 VCLEFT_tpmsLVState 1 "LV_ON" 2 "LV_GOING_DOWN" 3 "LV_FAULT" 0 "LV_OFF" ;
VAL_ 578 VCLEFT_rcmLVState 1 "LV_ON" 2 "LV_GOING_DOWN" 3 "LV_FAULT" 0 "LV_OFF" ;
VAL_ 1879 DI_immobilizerCondition 1 "DI_IMM_CONDITION_LEARNED" 0 "DI_IMM_CONDITION_VIRGIN_SNA" ;
VAL_ 1879 DI_magnetTempEst_SFO 0 "SNA" ;
VAL_ 1879 DI_magnetTempEst 0 "SNA" ;
VAL_ 1879 DI_oilPumpPressureEstimate 255 "SNA" ;
VAL_ 1879 DI_brkStState 1 "BRKST_STATE_IDLE" 4 "BRKST_STATE_RUNNING_PRESSED" 0 "BRKST_STATE_UNAVAILABLE" 3 "BRKST_STATE_RUNNING_PRESSING" 5 "BRKST_STATE_INTERRUPTED" 2 "BRKST_STATE_RUNNING_UNPRESSED" 6 "BRKST_STATE_FINISHED" ;
VAL_ 1879 DI_tcMinRequest 255 "SNA" ;
VAL_ 1879 DI_aebUnavailableReason 0 "DI_AEB_UNAVAILABLE_NONE" 2 "DI_AEB_UNAVAILABLE_GEAR" 9 "DI_AEB_UNAVAILABLE_TRACK_MODE" 8 "DI_AEB_UNAVAILABLE_HYSTERESIS" 5 "DI_AEB_UNAVAILABLE_DI_STATE" 7 "DI_AEB_UNAVAILABLE_EPB" 1 "DI_AEB_UNAVAILABLE_CLOSURE" 4 "DI_AEB_UNAVAILABLE_NEGATIVE_SPEED" 3 "DI_AEB_UNAVAILABLE_SKID" 6 "DI_AEB_UNAVAILABLE_EBR_UNAVAILABLE" ;
VAL_ 1879 DI_oilPumpPhaseAdvance 255 "SNA" ;
VAL_ 1879 DI_tcMaxRequest 255 "SNA" ;
VAL_ 1879 DI_oilPumpPhaseVoltage 255 "SNA" ;
VAL_ 1879 DI_aebFaultReason 0 "DI_AEB_FAULT_NONE" 15 "DI_AEB_FAULT_DAS_REQ_DI_UNAVAIL" 9 "DI_AEB_FAULT_ACCEL_OUT_OF_BOUNDS" 11 "DI_AEB_FAULT_ESP_FAULT" 10 "DI_AEB_FAULT_EPB_NOT_PARKED" 1 "DI_AEB_FAULT_EPB_MIA" 4 "DI_AEB_FAULT_SPEED_DELTA" 13 "DI_AEB_FAULT_MIN_TIME_BTWN_EVENTS" 2 "DI_AEB_FAULT_PM_MIA" 14 "DI_AEB_FAULT_ACCEL_REQ_INVALID" 12 "DI_AEB_FAULT_ESP_MIA" 5 "DI_AEB_FAULT_DAS_CONTROL_MIA" 8 "DI_AEB_FAULT_PM_REQUEST" 7 "DI_AEB_FAULT_VEL_EST_ABNORMAL" 6 "DI_AEB_FAULT_DAS_SNA" 3 "DI_AEB_FAULT_EBR_FAULT" ;
VAL_ 1879 DI_fluxState 2 "DI_FLUXSTATE_STANDBY" 0 "DI_FLUXSTATE_START" 5 "DI_FLUXSTATE_ENABLED" 1 "DI_FLUXSTATE_TEST" 7 "DI_FLUXSTATE_VCONTROL" 4 "DI_FLUXSTATE_FLUX_DOWN" 9 "DI_FLUXSTATE_FAULT" 3 "DI_FLUXSTATE_FLUX_UP" 6 "DI_FLUXSTATE_ICONTROL" ;
VAL_ 1879 DI_powerStageSafeState 0 "PSTG_SAFESTATE_NONE" 3 "PSTG_SAFESTATE_3PS_LOW" 2 "PSTG_SAFESTATE_3PS_HIGH" 1 "PSTG_SAFESTATE_ALL_OFF" ;
VAL_ 1879 DI_usmState 7 "USM_STATE_WAIT_FOR_RETRY" 3 "USM_STATE_ABORT" 0 "USM_STATE_START" 2 "USM_STATE_RETRY" 4 "USM_STATE_ENABLE" 1 "USM_STATE_STANDBY" 6 "USM_STATE_UNAVAILABLE" 5 "USM_STATE_FAULT" ;
VAL_ 1879 DI_gateDriveState 3 "PSTG_GD_STATE_CONFIGURED" 4 "PSTG_GD_STATE_NOT_CONFIGURED" 2 "PSTG_GD_STATE_CONFIGURING" 0 "PSTG_GD_STATE_INIT" 1 "PSTG_GD_STATE_SELFTEST" ;
VAL_ 1879 DI_motorType 18 "DI_MOTOR_PM216B" 7 "DI_MOTOR_M7M6" 0 "DI_MOTOR_SNA" 23 "DI_MOTOR_PM216D" 21 "DI_MOTOR_PM216C" 10 "DI_MOTOR_F1AC" 2 "DI_MOTOR_ROADSTER_SPORT" 14 "DI_MOTOR_F2AE" 20 "DI_MOTOR_IM216A" 25 "DI_MOTOR_IM130D_AL" 19 "DI_MOTOR_IM100B" 1 "DI_MOTOR_ROADSTER_BASE" 9 "DI_MOTOR_SSR1A" 5 "DI_MOTOR_M7M5" 24 "DI_MOTOR_IM130D" 16 "DI_MOTOR_PM216A" 13 "DI_MOTOR_F2AD" 6 "DI_MOTOR_M8A" 3 "DI_MOTOR_M7M3" 15 "DI_MOTOR_F2APMSRM" 17 "DI_MOTOR_IM100A" 4 "DI_MOTOR_M7M4" 8 "DI_MOTOR_F1A" 12 "DI_MOTOR_F2AC" 22 "DI_MOTOR_IM130C" 11 "DI_MOTOR_F2AB" ;
VAL_ 1879 DI_oilPumpPhaseCurrent 255 "SNA" ;
VAL_ 1879 DI_ssmState 6 "SSM_STATE_WAIT_FOR_RETRY" 8 "SSM_STATE_FAULT" 1 "SSM_STATE_UNAVAILABLE" 2 "SSM_STATE_IDLE" 7 "SSM_STATE_RETRY" 0 "SSM_STATE_START" 3 "SSM_STATE_STANDBY" 5 "SSM_STATE_ABORT" 4 "SSM_STATE_ENABLE" ;
VAL_ 1879 DI_rotorOffsetLearningState 5 "ROL_STATE_CORRECT" 3 "ROL_STATE_SHIFT" 8 "ROL_STATE_DONE" 2 "ROL_STATE_ACCELERATE" 0 "ROL_STATE_INIT" 1 "ROL_STATE_WAIT" 7 "ROL_STATE_WRITE" 9 "ROL_NUM_STATES" 4 "ROL_STATE_MEASURE" 6 "ROL_STATE_VERIFY" ;
VAL_ 1879 DI_gateDriveSupplyState 1 "PSTG_GD_SUPPLY_RISING" 2 "PSTG_GD_SUPPLY_UP" 0 "PSTG_GD_SUPPLY_DOWN" 3 "PSTG_GD_SUPPLY_FALLING" ;
VAL_ 1879 DI_velocityEstimatorState 0 "VE_STATE_NOT_INITIALIZED" 1 "VE_STATE_WHEELS_NORMAL" 3 "VE_STATE_BACKUP_WHEELS_B" 2 "VE_STATE_BACKUP_WHEELS_A" 4 "VE_STATE_BACKUP_MOTOR" ;
VAL_ 897 VCFRONT_fiveWayValveRadBypass 127 "SNA" ;
VAL_ 897 VCFRONT_radiatorFanFETTemp 255 "SNA" ;
VAL_ 897 VCFRONT_pumpPowertrainFETTemp 255 "SNA" ;
VAL_ 897 VCFRONT_pumpBatteryFETTemp 255 "SNA" ;
VAL_ 897 VCFRONT_tempRefrigSuction 255 "SNA" ;
VAL_ 897 VCFRONT_activeLouverMotorState 5 "BRAKE" 0 "UNPOWERED" 7 "FAULT_MOTOR_DISCONNECTED" 8 "DRIVER_FAULT" 3 "I2C_ERROR" 2 "INIT_EEPROM" 1 "INIT_I2C" 4 "READY" 6 "STALL" ;
VAL_ 897 VCFRONT_modeDesired 0 "SERIES" 1 "PARALLEL" ;
VAL_ 897 VCFRONT_fiveWayValveCountRange 255 "SNA" ;
VAL_ 897 VCFRONT_fiveWayValveRecalReason 2 "GENERAL_FAULT" 1 "MAX_TRAVEL" 3 "CALIBRATION_FAULT_NO_TRAVEL" 5 "MOTOR_FEEDBACK_INTERRUPTED" 0 "UNDEFINED" 4 "SELF_TEST" ;
VAL_ 897 VCFRONT_modeTransitionID 2 "SERIES_1_drive_batteryWantsCool" 13 "SERIES_7_fastCharge_batteryWantsCool" 19 "INIT" 18 "PARALLEL_9_drive_batteryThermalLimiting" 11 "PARALLEL_6_charge_batteryWantsCool" 5 "PARALLEL_2_drive_batteryWantsHeat" 3 "SERIES_2_drive_batteryNeedsHeat" 0 "PARALLEL_F1_noFlowRequest" 8 "SERIES_4_charge_batteryNeedsHeat" 10 "PARALLEL_5_charge_batteryWantsHeat" 4 "SERIES_3_drive_batteryWantsHeat" 14 "PARALLEL_7_fastCharge_batteryWantsCool" 15 "PARALLEL_8_fastCharge_batteryWantsHeat" 12 "SERIES_6_fastCharge_batteryNeedsHeat" 16 "SERIES_8_preConditioning_batteryNeedsHeat" 20 "OVERRIDE" 7 "PARALLEL_4_drive_batteryNeedsCool" 21 "UNDEFINED" 17 "SERIES_9_drive_driveUnitThermalLimiting" 1 "SERIES_F2_faultPumps" 6 "PARALLEL_3_drive_batteryWantsCool" 9 "SERIES_5_charge_batteryWantsHeat" ;
VAL_ 897 VCFRONT_activeLouverState 1 "CALIB_CLOSE" 4 "FAULTED" 0 "UNCALIBRATED" 3 "READY" 2 "CALIB_OPEN" ;
VAL_ 897 VCFRONT_logging1HzIndex 0 "COOLANT" 1 "CONDENSER_LOUVER_IC" 2 "ACTIVE_LOUVER_AND_BRUSHLESS_FETS" 3 "FIVE_WAY_VALVE" 4 "END" ;
VAL_ 548 PCS_dcdcInitialPrechargeSubState 13 "DCDC_SUBSTATE_DIS_HVBUS_FAULTED" 4 "DCDC_SUBSTATE_PCHG_FAST_DIS_HVBUS" 15 "DCDC_SUBSTATE_CLEAR_FAULTS" 7 "DCDC_SUBSTATE_PCHG_DWELL_WAIT" 12 "DCDC_SUBSTATE_12V_SUPPORT_FAULTED" 8 "DCDC_SUBSTATE_PCHG_DI_RECOVERY_WAIT" 17 "DCDC_SUBSTATE_NUM" 10 "DCDC_SUBSTATE_PCHG_FLT_FAST_DIS_HVBUS" 2 "DCDC_SUBSTATE_12V_SUPPORT_ACTIVE" 3 "DCDC_SUBSTATE_DIS_HVBUS" 14 "DCDC_SUBSTATE_PCHG_FAULTED" 11 "DCDC_SUBSTATE_SHUTDOWN" 1 "DCDC_SUBSTATE_STANDBY" 9 "DCDC_SUBSTATE_PCHG_ACTIVE" 16 "DCDC_SUBSTATE_FAULTED" 6 "DCDC_SUBSTATE_PCHG_DWELL_CHARGE" 5 "DCDC_SUBSTATE_PCHG_SLOW_DIS_HVBUS" 0 "DCDC_SUBSTATE_PWR_UP_INIT" ;
VAL_ 548 PCS_ecuLogUploadRequest 3 "REQUEST_PRIORITY_3" 2 "REQUEST_PRIORITY_2" 0 "REQUEST_PRIORITY_NONE" 1 "REQUEST_PRIORITY_1" ;
VAL_ 548 PCS_dcdcSubState 13 "DCDC_SUBSTATE_DIS_HVBUS_FAULTED" 4 "DCDC_SUBSTATE_PCHG_FAST_DIS_HVBUS" 15 "DCDC_SUBSTATE_CLEAR_FAULTS" 7 "DCDC_SUBSTATE_PCHG_DWELL_WAIT" 12 "DCDC_SUBSTATE_12V_SUPPORT_FAULTED" 8 "DCDC_SUBSTATE_PCHG_DI_RECOVERY_WAIT" 17 "DCDC_SUBSTATE_NUM" 10 "DCDC_SUBSTATE_PCHG_FLT_FAST_DIS_HVBUS" 2 "DCDC_SUBSTATE_12V_SUPPORT_ACTIVE" 3 "DCDC_SUBSTATE_DIS_HVBUS" 14 "DCDC_SUBSTATE_PCHG_FAULTED" 11 "DCDC_SUBSTATE_SHUTDOWN" 1 "DCDC_SUBSTATE_STANDBY" 9 "DCDC_SUBSTATE_PCHG_ACTIVE" 16 "DCDC_SUBSTATE_FAULTED" 6 "DCDC_SUBSTATE_PCHG_DWELL_CHARGE" 5 "DCDC_SUBSTATE_PCHG_SLOW_DIS_HVBUS" 0 "DCDC_SUBSTATE_PWR_UP_INIT" ;
VAL_ 548 PCS_dcdcMainState 6 "DCDC_STATE_FAULTED" 0 "DCDC_STATE_STANDBY" 4 "DCDC_STATE_DIS_HVBUS_ACTIVE" 5 "DCDC_STATE_SHUTDOWN" 2 "DCDC_STATE_PRECHARGE_STARTUP" 3 "DCDC_STATE_PRECHARGE_ACTIVE" 1 "DCDC_STATE_12V_SUPPORT_ACTIVE" ;
VAL_ 548 PCS_dcdcHvBusDischargeStatus 1 "PCS_DCDC_DIS_HVBUS_ACTIVE" 2 "PCS_DCDC_DIS_HVBUS_FAULTED" 0 "PCS_DCDC_DIS_HVBUS_IDLE" ;
VAL_ 548 PCS_dcdc12VSupportStatus 0 "PCS_DCDC_12V_SUPPORT_IDLE" 1 "PCS_DCDC_12V_SUPPORT_ACTIVE" 2 "PCS_DCDC_12V_SUPPORT_FAULTED" ;
VAL_ 548 PCS_dcdcPrechargeStatus 0 "PCS_DCDC_PRECHARGE_IDLE" 1 "PCS_DCDC_PRECHARGE_ACTIVE" 2 "PCS_DCDC_PRECHARGE_FAULTED" ;
VAL_ 618 HVP_fcPrechargeRequest 1 "HVP_FC_PRECHARGE_REQ_VALID" 0 "HVP_FC_PRECHARGE_REQ" ;
VAL_ 1025 BMS_brickVoltageStatus72 0 "SENSOR_SNA" 1 "SENSOR_BAD" 2 "SENSOR_NOMINAL" 3 "SENSOR_BYPASSED" ;
VAL_ 1025 BMS_brickVoltageStatus36 0 "SENSOR_SNA" 1 "SENSOR_BAD" 2 "SENSOR_NOMINAL" 3 "SENSOR_BYPASSED" ;
VAL_ 1025 BMS_brickVoltageStatus39 0 "SENSOR_SNA" 1 "SENSOR_BAD" 2 "SENSOR_NOMINAL" 3 "SENSOR_BYPASSED" ;
VAL_ 1025 BMS_brickVoltageStatus93 0 "SENSOR_SNA" 1 "SENSOR_BAD" 2 "SENSOR_NOMINAL" 3 "SENSOR_BYPASSED" ;
VAL_ 1025 BMS_brickVoltageStatus78 0 "SENSOR_SNA" 1 "SENSOR_BAD" 2 "SENSOR_NOMINAL" 3 "SENSOR_BYPASSED" ;
VAL_ 1025 BMS_brickVoltageStatus96 0 "SENSOR_SNA" 1 "SENSOR_BAD" 2 "SENSOR_NOMINAL" 3 "SENSOR_BYPASSED" ;
VAL_ 1025 BMS_brickVoltageStatus15 0 "SENSOR_SNA" 1 "SENSOR_BAD" 2 "SENSOR_NOMINAL" 3 "SENSOR_BYPASSED" ;
VAL_ 1025 BMS_brickVoltageStatus48 0 "SENSOR_SNA" 1 "SENSOR_BAD" 2 "SENSOR_NOMINAL" 3 "SENSOR_BYPASSED" ;
VAL_ 1025 BMS_brickVoltageStatus51 0 "SENSOR_SNA" 1 "SENSOR_BAD" 2 "SENSOR_NOMINAL" 3 "SENSOR_BYPASSED" ;
VAL_ 1025 BMS_brickVoltageStatus84 0 "SENSOR_SNA" 1 "SENSOR_BAD" 2 "SENSOR_NOMINAL" 3 "SENSOR_BYPASSED" ;
VAL_ 1025 BMS_brickVoltageStatus90 0 "SENSOR_SNA" 1 "SENSOR_BAD" 2 "SENSOR_NOMINAL" 3 "SENSOR_BYPASSED" ;
VAL_ 1025 BMS_brickVoltageStatus18 0 "SENSOR_SNA" 1 "SENSOR_BAD" 2 "SENSOR_NOMINAL" 3 "SENSOR_BYPASSED" ;
VAL_ 1025 BMS_brickVoltageStatus45 0 "SENSOR_SNA" 1 "SENSOR_BAD" 2 "SENSOR_NOMINAL" 3 "SENSOR_BYPASSED" ;
VAL_ 1025 BMS_brickVoltageStatus6 0 "SENSOR_SNA" 1 "SENSOR_BAD" 2 "SENSOR_NOMINAL" 3 "SENSOR_BYPASSED" ;
VAL_ 1025 BMS_brickVoltageStatus60 0 "SENSOR_SNA" 1 "SENSOR_BAD" 2 "SENSOR_NOMINAL" 3 "SENSOR_BYPASSED" ;
VAL_ 1025 BMS_brickVoltageStatus42 0 "SENSOR_SNA" 1 "SENSOR_BAD" 2 "SENSOR_NOMINAL" 3 "SENSOR_BYPASSED" ;
VAL_ 1025 BMS_brickVoltageStatus24 0 "SENSOR_SNA" 1 "SENSOR_BAD" 2 "SENSOR_NOMINAL" 3 "SENSOR_BYPASSED" ;
VAL_ 1025 BMS_brickVoltageStatus30 0 "SENSOR_SNA" 1 "SENSOR_BAD" 2 "SENSOR_NOMINAL" 3 "SENSOR_BYPASSED" ;
VAL_ 1025 BMS_brickVoltageStatus12 0 "SENSOR_SNA" 1 "SENSOR_BAD" 2 "SENSOR_NOMINAL" 3 "SENSOR_BYPASSED" ;
VAL_ 1025 BMS_brickVoltageStatus66 0 "SENSOR_SNA" 1 "SENSOR_BAD" 2 "SENSOR_NOMINAL" 3 "SENSOR_BYPASSED" ;
VAL_ 1025 BMS_brickVoltageStatus63 0 "SENSOR_SNA" 1 "SENSOR_BAD" 2 "SENSOR_NOMINAL" 3 "SENSOR_BYPASSED" ;
VAL_ 1025 BMS_brickVoltageStatus27 0 "SENSOR_SNA" 1 "SENSOR_BAD" 2 "SENSOR_NOMINAL" 3 "SENSOR_BYPASSED" ;
VAL_ 1025 BMS_brickVoltageStatus57 0 "SENSOR_SNA" 1 "SENSOR_BAD" 2 "SENSOR_NOMINAL" 3 "SENSOR_BYPASSED" ;
VAL_ 1025 BMS_brickVoltageStatus75 0 "SENSOR_SNA" 1 "SENSOR_BAD" 2 "SENSOR_NOMINAL" 3 "SENSOR_BYPASSED" ;
VAL_ 1025 BMS_brickVoltageStatus87 0 "SENSOR_SNA" 1 "SENSOR_BAD" 2 "SENSOR_NOMINAL" 3 "SENSOR_BYPASSED" ;
VAL_ 1025 BMS_brickVoltageStatus69 0 "SENSOR_SNA" 1 "SENSOR_BAD" 2 "SENSOR_NOMINAL" 3 "SENSOR_BYPASSED" ;
VAL_ 1025 BMS_brickVoltageStatus105 0 "SENSOR_SNA" 1 "SENSOR_BAD" 2 "SENSOR_NOMINAL" 3 "SENSOR_BYPASSED" ;
VAL_ 1025 BMS_brickVoltageStatus108 0 "SENSOR_SNA" 1 "SENSOR_BAD" 2 "SENSOR_NOMINAL" 3 "SENSOR_BYPASSED" ;
VAL_ 1025 BMS_brickVoltageStatus54 0 "SENSOR_SNA" 1 "SENSOR_BAD" 2 "SENSOR_NOMINAL" 3 "SENSOR_BYPASSED" ;
VAL_ 1025 BMS_brickVoltageStatus9 0 "SENSOR_SNA" 1 "SENSOR_BAD" 2 "SENSOR_NOMINAL" 3 "SENSOR_BYPASSED" ;
VAL_ 1025 BMS_brickVoltageStatus81 0 "SENSOR_SNA" 1 "SENSOR_BAD" 2 "SENSOR_NOMINAL" 3 "SENSOR_BYPASSED" ;
VAL_ 1025 BMS_brickVoltageStatus102 0 "SENSOR_SNA" 1 "SENSOR_BAD" 2 "SENSOR_NOMINAL" 3 "SENSOR_BYPASSED" ;
VAL_ 1025 BMS_brickVoltageStatus21 0 "SENSOR_SNA" 1 "SENSOR_BAD" 2 "SENSOR_NOMINAL" 3 "SENSOR_BYPASSED" ;
VAL_ 1025 BMS_brickVoltageStatus3 0 "SENSOR_SNA" 1 "SENSOR_BAD" 2 "SENSOR_NOMINAL" 3 "SENSOR_BYPASSED" ;
VAL_ 1025 BMS_brickVoltageStatus99 0 "SENSOR_SNA" 1 "SENSOR_BAD" 2 "SENSOR_NOMINAL" 3 "SENSOR_BYPASSED" ;
VAL_ 1025 BMS_brickVoltageStatus33 0 "SENSOR_SNA" 1 "SENSOR_BAD" 2 "SENSOR_NOMINAL" 3 "SENSOR_BYPASSED" ;
VAL_ 1025 BMS_brickVoltageStatus50 0 "SENSOR_SNA" 1 "SENSOR_BAD" 2 "SENSOR_NOMINAL" 3 "SENSOR_BYPASSED" ;
VAL_ 1025 BMS_brickVoltageStatus14 0 "SENSOR_SNA" 1 "SENSOR_BAD" 2 "SENSOR_NOMINAL" 3 "SENSOR_BYPASSED" ;
VAL_ 1025 BMS_brickVoltageStatus20 0 "SENSOR_SNA" 1 "SENSOR_BAD" 2 "SENSOR_NOMINAL" 3 "SENSOR_BYPASSED" ;
VAL_ 1025 BMS_brickVoltageStatus2 0 "SENSOR_SNA" 1 "SENSOR_BAD" 2 "SENSOR_NOMINAL" 3 "SENSOR_BYPASSED" ;
VAL_ 1025 BMS_brickVoltageStatus89 0 "SENSOR_SNA" 1 "SENSOR_BAD" 2 "SENSOR_NOMINAL" 3 "SENSOR_BYPASSED" ;
VAL_ 1025 BMS_brickVoltageStatus23 0 "SENSOR_SNA" 1 "SENSOR_BAD" 2 "SENSOR_NOMINAL" 3 "SENSOR_BYPASSED" ;
VAL_ 1025 BMS_brickVoltageStatus107 0 "SENSOR_SNA" 1 "SENSOR_BAD" 2 "SENSOR_NOMINAL" 3 "SENSOR_BYPASSED" ;
VAL_ 1025 BMS_brickVoltageStatus29 0 "SENSOR_SNA" 1 "SENSOR_BAD" 2 "SENSOR_NOMINAL" 3 "SENSOR_BYPASSED" ;
VAL_ 1025 BMS_brickVoltageStatus74 0 "SENSOR_SNA" 1 "SENSOR_BAD" 2 "SENSOR_NOMINAL" 3 "SENSOR_BYPASSED" ;
VAL_ 1025 BMS_brickVoltageStatus56 0 "SENSOR_SNA" 1 "SENSOR_BAD" 2 "SENSOR_NOMINAL" 3 "SENSOR_BYPASSED" ;
VAL_ 1025 BMS_brickVoltageStatus83 0 "SENSOR_SNA" 1 "SENSOR_BAD" 2 "SENSOR_NOMINAL" 3 "SENSOR_BYPASSED" ;
VAL_ 1025 BMS_brickVoltageStatus101 0 "SENSOR_SNA" 1 "SENSOR_BAD" 2 "SENSOR_NOMINAL" 3 "SENSOR_BYPASSED" ;
VAL_ 1025 BMS_brickVoltageStatus44 0 "SENSOR_SNA" 1 "SENSOR_BAD" 2 "SENSOR_NOMINAL" 3 "SENSOR_BYPASSED" ;
VAL_ 1025 BMS_brickVoltageStatus104 0 "SENSOR_SNA" 1 "SENSOR_BAD" 2 "SENSOR_NOMINAL" 3 "SENSOR_BYPASSED" ;
VAL_ 1025 BMS_brickVoltageStatus41 0 "SENSOR_SNA" 1 "SENSOR_BAD" 2 "SENSOR_NOMINAL" 3 "SENSOR_BYPASSED" ;
VAL_ 1025 BMS_brickVoltageStatus5 0 "SENSOR_SNA" 1 "SENSOR_BAD" 2 "SENSOR_NOMINAL" 3 "SENSOR_BYPASSED" ;
VAL_ 1025 BMS_brickVoltageStatus26 0 "SENSOR_SNA" 1 "SENSOR_BAD" 2 "SENSOR_NOMINAL" 3 "SENSOR_BYPASSED" ;
VAL_ 1025 BMS_brickVoltageStatus59 0 "SENSOR_SNA" 1 "SENSOR_BAD" 2 "SENSOR_NOMINAL" 3 "SENSOR_BYPASSED" ;
VAL_ 1025 BMS_brickVoltageStatus95 0 "SENSOR_SNA" 1 "SENSOR_BAD" 2 "SENSOR_NOMINAL" 3 "SENSOR_BYPASSED" ;
VAL_ 1025 BMS_brickVoltageStatus62 0 "SENSOR_SNA" 1 "SENSOR_BAD" 2 "SENSOR_NOMINAL" 3 "SENSOR_BYPASSED" ;
VAL_ 1025 BMS_brickVoltageStatus32 0 "SENSOR_SNA" 1 "SENSOR_BAD" 2 "SENSOR_NOMINAL" 3 "SENSOR_BYPASSED" ;
VAL_ 1025 BMS_brickVoltageStatus98 0 "SENSOR_SNA" 1 "SENSOR_BAD" 2 "SENSOR_NOMINAL" 3 "SENSOR_BYPASSED" ;
VAL_ 1025 BMS_brickVoltageStatus35 0 "SENSOR_SNA" 1 "SENSOR_BAD" 2 "SENSOR_NOMINAL" 3 "SENSOR_BYPASSED" ;
VAL_ 1025 BMS_brickVoltageStatus17 0 "SENSOR_SNA" 1 "SENSOR_BAD" 2 "SENSOR_NOMINAL" 3 "SENSOR_BYPASSED" ;
VAL_ 1025 BMS_brickVoltageStatus68 0 "SENSOR_SNA" 1 "SENSOR_BAD" 2 "SENSOR_NOMINAL" 3 "SENSOR_BYPASSED" ;
VAL_ 1025 BMS_brickVoltageStatus71 0 "SENSOR_SNA" 1 "SENSOR_BAD" 2 "SENSOR_NOMINAL" 3 "SENSOR_BYPASSED" ;
VAL_ 1025 BMS_brickVoltageStatus53 0 "SENSOR_SNA" 1 "SENSOR_BAD" 2 "SENSOR_NOMINAL" 3 "SENSOR_BYPASSED" ;
VAL_ 1025 BMS_brickVoltageStatus86 0 "SENSOR_SNA" 1 "SENSOR_BAD" 2 "SENSOR_NOMINAL" 3 "SENSOR_BYPASSED" ;
VAL_ 1025 BMS_brickVoltageStatus92 0 "SENSOR_SNA" 1 "SENSOR_BAD" 2 "SENSOR_NOMINAL" 3 "SENSOR_BYPASSED" ;
VAL_ 1025 BMS_brickVoltageStatus38 0 "SENSOR_SNA" 1 "SENSOR_BAD" 2 "SENSOR_NOMINAL" 3 "SENSOR_BYPASSED" ;
VAL_ 1025 BMS_brickVoltageStatus65 0 "SENSOR_SNA" 1 "SENSOR_BAD" 2 "SENSOR_NOMINAL" 3 "SENSOR_BYPASSED" ;
VAL_ 1025 BMS_brickVoltageStatus47 0 "SENSOR_SNA" 1 "SENSOR_BAD" 2 "SENSOR_NOMINAL" 3 "SENSOR_BYPASSED" ;
VAL_ 1025 BMS_brickVoltageStatus77 0 "SENSOR_SNA" 1 "SENSOR_BAD" 2 "SENSOR_NOMINAL" 3 "SENSOR_BYPASSED" ;
VAL_ 1025 BMS_brickVoltageStatus8 0 "SENSOR_SNA" 1 "SENSOR_BAD" 2 "SENSOR_NOMINAL" 3 "SENSOR_BYPASSED" ;
VAL_ 1025 BMS_brickVoltageStatus80 0 "SENSOR_SNA" 1 "SENSOR_BAD" 2 "SENSOR_NOMINAL" 3 "SENSOR_BYPASSED" ;
VAL_ 1025 BMS_brickVoltageStatus11 0 "SENSOR_SNA" 1 "SENSOR_BAD" 2 "SENSOR_NOMINAL" 3 "SENSOR_BYPASSED" ;
VAL_ 1025 BMS_brickVoltageStatus49 0 "SENSOR_SNA" 1 "SENSOR_BAD" 2 "SENSOR_NOMINAL" 3 "SENSOR_BYPASSED" ;
VAL_ 1025 BMS_brickVoltageStatus85 0 "SENSOR_SNA" 1 "SENSOR_BAD" 2 "SENSOR_NOMINAL" 3 "SENSOR_BYPASSED" ;
VAL_ 1025 BMS_brickVoltageStatus103 0 "SENSOR_SNA" 1 "SENSOR_BAD" 2 "SENSOR_NOMINAL" 3 "SENSOR_BYPASSED" ;
VAL_ 1025 BMS_brickVoltageStatus64 0 "SENSOR_SNA" 1 "SENSOR_BAD" 2 "SENSOR_NOMINAL" 3 "SENSOR_BYPASSED" ;
VAL_ 1025 BMS_brickVoltageStatus46 0 "SENSOR_SNA" 1 "SENSOR_BAD" 2 "SENSOR_NOMINAL" 3 "SENSOR_BYPASSED" ;
VAL_ 1025 BMS_brickVoltageStatus106 0 "SENSOR_SNA" 1 "SENSOR_BAD" 2 "SENSOR_NOMINAL" 3 "SENSOR_BYPASSED" ;
VAL_ 1025 BMS_brickVoltageStatus61 0 "SENSOR_SNA" 1 "SENSOR_BAD" 2 "SENSOR_NOMINAL" 3 "SENSOR_BYPASSED" ;
VAL_ 1025 BMS_brickVoltageStatus43 0 "SENSOR_SNA" 1 "SENSOR_BAD" 2 "SENSOR_NOMINAL" 3 "SENSOR_BYPASSED" ;
VAL_ 1025 BMS_brickVoltageStatus25 0 "SENSOR_SNA" 1 "SENSOR_BAD" 2 "SENSOR_NOMINAL" 3 "SENSOR_BYPASSED" ;
VAL_ 1025 BMS_brickVoltageStatus7 0 "SENSOR_SNA" 1 "SENSOR_BAD" 2 "SENSOR_NOMINAL" 3 "SENSOR_BYPASSED" ;
VAL_ 1025 BMS_brickVoltageStatus37 0 "SENSOR_SNA" 1 "SENSOR_BAD" 2 "SENSOR_NOMINAL" 3 "SENSOR_BYPASSED" ;
VAL_ 1025 BMS_brickVoltageStatus73 0 "SENSOR_SNA" 1 "SENSOR_BAD" 2 "SENSOR_NOMINAL" 3 "SENSOR_BYPASSED" ;
VAL_ 1025 BMS_brickVoltageStatus1 0 "SENSOR_SNA" 1 "SENSOR_BAD" 2 "SENSOR_NOMINAL" 3 "SENSOR_BYPASSED" ;
VAL_ 1025 BMS_brickVoltageStatus100 0 "SENSOR_SNA" 1 "SENSOR_BAD" 2 "SENSOR_NOMINAL" 3 "SENSOR_BYPASSED" ;
VAL_ 1025 BMS_brickVoltageStatus67 0 "SENSOR_SNA" 1 "SENSOR_BAD" 2 "SENSOR_NOMINAL" 3 "SENSOR_BYPASSED" ;
VAL_ 1025 BMS_brickVoltageStatus79 0 "SENSOR_SNA" 1 "SENSOR_BAD" 2 "SENSOR_NOMINAL" 3 "SENSOR_BYPASSED" ;
VAL_ 1025 BMS_brickVoltageStatus97 0 "SENSOR_SNA" 1 "SENSOR_BAD" 2 "SENSOR_NOMINAL" 3 "SENSOR_BYPASSED" ;
VAL_ 1025 BMS_brickVoltageStatus19 0 "SENSOR_SNA" 1 "SENSOR_BAD" 2 "SENSOR_NOMINAL" 3 "SENSOR_BYPASSED" ;
VAL_ 1025 BMS_brickVoltageStatus22 0 "SENSOR_SNA" 1 "SENSOR_BAD" 2 "SENSOR_NOMINAL" 3 "SENSOR_BYPASSED" ;
VAL_ 1025 BMS_brickVoltageStatus88 0 "SENSOR_SNA" 1 "SENSOR_BAD" 2 "SENSOR_NOMINAL" 3 "SENSOR_BYPASSED" ;
VAL_ 1025 BMS_brickVoltageStatus91 0 "SENSOR_SNA" 1 "SENSOR_BAD" 2 "SENSOR_NOMINAL" 3 "SENSOR_BYPASSED" ;
VAL_ 1025 BMS_brickVoltageStatus58 0 "SENSOR_SNA" 1 "SENSOR_BAD" 2 "SENSOR_NOMINAL" 3 "SENSOR_BYPASSED" ;
VAL_ 1025 BMS_brickVoltageStatus94 0 "SENSOR_SNA" 1 "SENSOR_BAD" 2 "SENSOR_NOMINAL" 3 "SENSOR_BYPASSED" ;
VAL_ 1025 BMS_brickVoltageStatus82 0 "SENSOR_SNA" 1 "SENSOR_BAD" 2 "SENSOR_NOMINAL" 3 "SENSOR_BYPASSED" ;
VAL_ 1025 BMS_brickVoltageStatus31 0 "SENSOR_SNA" 1 "SENSOR_BAD" 2 "SENSOR_NOMINAL" 3 "SENSOR_BYPASSED" ;
VAL_ 1025 BMS_brickVoltageStatus13 0 "SENSOR_SNA" 1 "SENSOR_BAD" 2 "SENSOR_NOMINAL" 3 "SENSOR_BYPASSED" ;
VAL_ 1025 BMS_brickVoltageStatus28 0 "SENSOR_SNA" 1 "SENSOR_BAD" 2 "SENSOR_NOMINAL" 3 "SENSOR_BYPASSED" ;
VAL_ 1025 BMS_brickVoltageStatus70 0 "SENSOR_SNA" 1 "SENSOR_BAD" 2 "SENSOR_NOMINAL" 3 "SENSOR_BYPASSED" ;
VAL_ 1025 BMS_brickVoltageStatus52 0 "SENSOR_SNA" 1 "SENSOR_BAD" 2 "SENSOR_NOMINAL" 3 "SENSOR_BYPASSED" ;
VAL_ 1025 BMS_brickVoltageStatus34 0 "SENSOR_SNA" 1 "SENSOR_BAD" 2 "SENSOR_NOMINAL" 3 "SENSOR_BYPASSED" ;
VAL_ 1025 BMS_brickVoltageStatus16 0 "SENSOR_SNA" 1 "SENSOR_BAD" 2 "SENSOR_NOMINAL" 3 "SENSOR_BYPASSED" ;
VAL_ 1025 BMS_brickVoltageStatus4 0 "SENSOR_SNA" 1 "SENSOR_BAD" 2 "SENSOR_NOMINAL" 3 "SENSOR_BYPASSED" ;
VAL_ 1025 BMS_brickVoltageStatus40 0 "SENSOR_SNA" 1 "SENSOR_BAD" 2 "SENSOR_NOMINAL" 3 "SENSOR_BYPASSED" ;
VAL_ 1025 BMS_brickVoltageStatus10 0 "SENSOR_SNA" 1 "SENSOR_BAD" 2 "SENSOR_NOMINAL" 3 "SENSOR_BYPASSED" ;
VAL_ 1025 BMS_brickVoltageStatus76 0 "SENSOR_SNA" 1 "SENSOR_BAD" 2 "SENSOR_NOMINAL" 3 "SENSOR_BYPASSED" ;
VAL_ 1025 BMS_brickVoltageStatus55 0 "SENSOR_SNA" 1 "SENSOR_BAD" 2 "SENSOR_NOMINAL" 3 "SENSOR_BYPASSED" ;
VAL_ 1025 BMS_brickVoltageMultiplexer 26 "Mux26" 4 "Mux4" 34 "Mux34" 16 "Mux16" 2 "Mux2" 20 "Mux20" 5 "Mux5" 27 "Mux27" 11 "Mux11" 8 "Mux8" 33 "Mux33" 21 "Mux21" 3 "Mux3" 24 "Mux24" 6 "Mux6" 9 "Mux9" 32 "Mux32" 10 "Mux10" 15 "Mux15" 7 "Mux7" 25 "Mux25" 31 "Mux31" 28 "Mux28" 13 "Mux13" 14 "Mux14" 22 "Mux22" 19 "Mux19" 0 "Mux0" 12 "Mux12" 30 "Mux30" 29 "Mux29" 17 "Mux17" 35 "Mux35" 23 "Mux23" 18 "Mux18" 1 "Mux1" ;
VAL_ 1962 HVP_shuntAsicTempDbg -32768 "SHUNT_TEMPERATURE_SNA" ;
VAL_ 1962 HVP_shuntBarTempDbg -32768 "SHUNT_TEMPERATURE_SNA" ;
VAL_ 1962 HVP_debugMessageMultiplexer 4 "Mux4" 2 "Mux2" 5 "Mux5" 3 "Mux3" 6 "Mux6" 0 "Mux0" 1 "Mux1" ;
VAL_ 585 SCCM_turnIndicatorStalkStatus 3 "DOWN_1" 5 "SNA" 0 "IDLE" 1 "UP_1" 4 "DOWN_2" 2 "UP_2" ;
VAL_ 585 SCCM_washWipeButtonStatus 3 "SNA" 0 "NOT_PRESSED" 2 "2ND_DETENT" 1 "1ST_DETENT" ;
VAL_ 585 SCCM_highBeamStalkStatus 3 "SNA" 0 "IDLE" 1 "PULL" 2 "PUSH" ;
VAL_ 522 HVP_hvilStatus 6 "UNKNOWN_LOCATION_OPEN_FAULT" 0 "UNKNOWN" 5 "PENTHOUSE_LID_OPEN_FAULT" 3 "INTERNAL_OPEN_FAULT" 1 "STATUS_OK" 8 "NO_12V_SUPPLY" 7 "VEHICLE_NODE_FAULT" 4 "VEHICLE_OPEN_FAULT" 2 "CURRENT_SOURCE_FAULT" ;
VAL_ 522 HVP_packCtrsRequestStatus 1 "REQUEST_ACTIVE" 0 "REQUEST_NOT_ACTIVE" 2 "REQUEST_COMPLETED" ;
VAL_ 522 HVP_fcCtrsRequestStatus 1 "REQUEST_ACTIVE" 0 "REQUEST_NOT_ACTIVE" 2 "REQUEST_COMPLETED" ;
VAL_ 522 HVP_fcContactorSetState 7 "CONTACTOR_SET_STATE_WELDED" 3 "CONTACTOR_SET_STATE_BLOCKED" 5 "CONTACTOR_SET_STATE_CLOSED" 4 "CONTACTOR_SET_STATE_OPENING" 8 "CONTACTOR_SET_STATE_POSITIVE_CLOSED" 6 "CONTACTOR_SET_STATE_PARTIAL_WELD" 2 "CONTACTOR_SET_STATE_CLOSING" 0 "CONTACTOR_SET_STATE_SNA" 1 "CONTACTOR_SET_STATE_OPEN" 9 "CONTACTOR_SET_STATE_NEGATIVE_CLOSED" ;
VAL_ 522 HVP_fcContPositiveState 2 "CONTACTOR_STATE_PRECHARGE" 3 "CONTACTOR_STATE_BLOCKED" 6 "CONTACTOR_STATE_ECONOMIZED" 4 "CONTACTOR_STATE_PULLED_IN" 0 "CONTACTOR_STATE_SNA" 1 "CONTACTOR_STATE_OPEN" 5 "CONTACTOR_STATE_OPENING" 7 "CONTACTOR_STATE_WELDED" ;
VAL_ 522 HVP_fcContNegativeState 2 "CONTACTOR_STATE_PRECHARGE" 3 "CONTACTOR_STATE_BLOCKED" 6 "CONTACTOR_STATE_ECONOMIZED" 4 "CONTACTOR_STATE_PULLED_IN" 0 "CONTACTOR_STATE_SNA" 1 "CONTACTOR_STATE_OPEN" 5 "CONTACTOR_STATE_OPENING" 7 "CONTACTOR_STATE_WELDED" ;
VAL_ 522 HVP_packContactorSetState 7 "CONTACTOR_SET_STATE_WELDED" 3 "CONTACTOR_SET_STATE_BLOCKED" 5 "CONTACTOR_SET_STATE_CLOSED" 4 "CONTACTOR_SET_STATE_OPENING" 8 "CONTACTOR_SET_STATE_POSITIVE_CLOSED" 6 "CONTACTOR_SET_STATE_PARTIAL_WELD" 2 "CONTACTOR_SET_STATE_CLOSING" 0 "CONTACTOR_SET_STATE_SNA" 1 "CONTACTOR_SET_STATE_OPEN" 9 "CONTACTOR_SET_STATE_NEGATIVE_CLOSED" ;
VAL_ 522 HVP_packContPositiveState 2 "CONTACTOR_STATE_PRECHARGE" 3 "CONTACTOR_STATE_BLOCKED" 6 "CONTACTOR_STATE_ECONOMIZED" 4 "CONTACTOR_STATE_PULLED_IN" 0 "CONTACTOR_STATE_SNA" 1 "CONTACTOR_STATE_OPEN" 5 "CONTACTOR_STATE_OPENING" 7 "CONTACTOR_STATE_WELDED" ;
VAL_ 522 HVP_packContNegativeState 2 "CONTACTOR_STATE_PRECHARGE" 3 "CONTACTOR_STATE_BLOCKED" 6 "CONTACTOR_STATE_ECONOMIZED" 4 "CONTACTOR_STATE_PULLED_IN" 0 "CONTACTOR_STATE_SNA" 1 "CONTACTOR_STATE_OPEN" 5 "CONTACTOR_STATE_OPENING" 7 "CONTACTOR_STATE_WELDED" ;
VAL_ 1444 PMS_a013_errorType 3 "PM_CAN_ERR_TX_OVERRUN" 2 "PM_CAN_ERR_RX_OVERRUN" 4 "PM_CAN_ERR_IPC_RX_OVERRUN" 1 "PM_CAN_ERR_TX" 5 "PM_CAN_ERR_IPC_TX_OVERRUN" 0 "PM_CAN_ERR_RX" ;
VAL_ 1444 PMS_a056_errorType 3 "PM_CAN_ERR_TX_OVERRUN" 2 "PM_CAN_ERR_RX_OVERRUN" 4 "PM_CAN_ERR_IPC_RX_OVERRUN" 1 "PM_CAN_ERR_TX" 5 "PM_CAN_ERR_IPC_TX_OVERRUN" 0 "PM_CAN_ERR_RX" ;
VAL_ 1444 PMS_a034_torqueType 2 "PEDAL_POSITION" 1 "TORQUE_COMMAND" 0 "TORQUE_ESTIMATE" ;
VAL_ 1444 PMS_a057_errorType 4 "CAN_RECEIVE_ERROR_SEQUENCE" 5 "CAN_RECEIVE_ERROR_DATA_INVALID" 1 "CAN_RECEIVE_ERROR_LENGTH_SHORT" 2 "CAN_RECEIVE_ERROR_LENGTH_LONG" 6 "CAN_RECEIVE_ERROR_UNKNOWN_ID" 0 "CAN_RECEIVE_ERROR_NONE" 3 "CAN_RECEIVE_ERROR_CHECKSUM" ;
VAL_ 1444 PMS_a012_errorType 4 "CAN_RECEIVE_ERROR_SEQUENCE" 5 "CAN_RECEIVE_ERROR_DATA_INVALID" 1 "CAN_RECEIVE_ERROR_LENGTH_SHORT" 2 "CAN_RECEIVE_ERROR_LENGTH_LONG" 6 "CAN_RECEIVE_ERROR_UNKNOWN_ID" 0 "CAN_RECEIVE_ERROR_NONE" 3 "CAN_RECEIVE_ERROR_CHECKSUM" ;
VAL_ 1444 PMS_a033_failReason 4 "SOPT_FAIL_TIMEDOUT" 2 "SOPT_FAIL_NEG_CURRENT" 1 "SOPT_FAIL_POS_CURRENT" 3 "SOPT_FAIL_DISAGREE" 5 "SOPT_FAIL_GATE_DRIVE_ERROR" 6 "SOPT_FAIL_FAULT_PRESENT" 0 "SOPT_FAIL_CACHED" 7 "SOPT_FAIL_ASC_TEST" ;
VAL_ 1444 PMS_a064_torqueCmdState 8 "TorqueCmd_Invalid" 6 "TorqueCmd_Valid" 0 "TorqueCmd_SNA" ;
VAL_ 1444 PMS_a042_expectedPerformanceCfg 1 "AWD" 0 "RWD" ;
VAL_ 1444 PMS_a042_GTW_drivetrainType 1 "AWD" 0 "RWD" ;
VAL_ 1444 PMS_a064_interventionType 7 "TRQP_excessiveRegenTorque" 8 "TRQP_torqueInNeutral" 0 "TRQP_masterTorqueMonitorShutoff" 2 "TRQP_torqueCmdInvalid" 1 "TRQP_resolver" 3 "TRQP_cruiseFault" 10 "TRQP_switchOffPathTestFail" 5 "TRQP_accumulatedTorque" 9 "TRQP_inconsistentTorqueSign" 6 "TRQP_torqueReversal" 4 "TRQP_motorMovementDetected" ;
VAL_ 1444 PMS_a033_state 1 "SOPT_STATE_PSTG_BRING_UP" 5 "SOPT_STATE_CURRENT_TEST_POS" 6 "SOPT_STATE_CURRENT_TEST_NEG" 2 "SOPT_STATE_ASC_TEST" 0 "SOPT_STATE_INIT" 10 "SOPT_STATE_TEST_FAILED" 3 "SOPT_STATE_ASC_TEST_PASSED" 4 "SOPT_STATE_PWM_ENABLE" 9 "SOPT_STATE_TEST_SKIPPED" 8 "SOPT_STATE_TEST_PASSED" 7 "SOPT_STATE_TEST_PRE_PASSED" 11 "SOPT_STATE_TEST_RESTART" ;
VAL_ 1444 PMS_a026_reason 0 "TooSlow" 1 "TooFast" ;
VAL_ 1444 PMS_alertType 0 "ALERT_CLEARED" 1 "ALERT_SET" ;
VAL_ 1444 PMS_alertID 57 "PMS_a057_canDataBusB" 28 "PMS_a028_torqueCmdError" 34 "PMS_a034_trqCrossCheck" 54 "PMS_a054_uiMIA" 6 "PMS_a006_inconsistentDIGear" 33 "PMS_a033_selfTest" 32 "PMS_a032_registerConfigError" 19 "PMS_a019_statorTempIrrational" 9 "PMS_a009_espMIA" 56 "PMS_a056_canHardwareBusB" 0 "PMS_ALERT_DO_NOT_USE_ZERO" 42 "PMS_a042_gtwMIA" 5 "PMS_a005_torqueInNeutral" 64 "PMS_a064_torqueIntervention" 53 "PMS_a053_vcfrontMIA" 31 "PMS_a031_highStackUsage" 40 "PMS_a040_pmMIA" 55 "PMS_a055_resolver" 1 "PMS_a001_absoluteTorque" 3 "PMS_a003_torqueReversal" 13 "PMS_a013_canHardwareBusA" 12 "PMS_a012_canDataBusA" 43 "PMS_a043_inconsistentConfig" 63 "PMS_a063_debugAlert" 4 "PMS_a004_regenTorque" 7 "PMS_a007_watchdogReset" 38 "PMS_a038_inconsistentTorqueSign" 45 "PMS_a045_motorMovementDetected" 11 "PMS_a011_phaseCurrentIrrational" 26 "PMS_a026_diHeartBeatMIA" 18 "PMS_a018_encoderIrrational" 10 "PMS_a010_diMIA" 39 "PMS_a039_disMIA" 61 "PMS_a061_DIPMVersionMismatch" 8 "PMS_a008_memoryError" 2 "PMS_a002_accumulatedTorque" 27 "PMS_a027_torqueOutOfMap" ;
VAL_ 1057 VCFRONT_nmWakeUpReason 6 "VCFRONT_WAKEUP_REASON_HIGH_SLEEP_CURRENT" 15 "VCFRONT_WAKEUP_REASON_UNKNOWN" 5 "VCFRONT_WAKEUP_REASON_FRUNK_ACCESS_POST" 0 "VCFRONT_WAKEUP_REASON_NONE" 10 "VCFRONT_WAKEUP_REASON_CAN" 7 "VCFRONT_WAKEUP_REASON_FRUNK_EMERGENCY_RELEASE" 3 "VCFRONT_WAKEUP_REASON_RESET" 1 "VCFRONT_WAKEUP_REASON_ECU_SPECIFIC" 4 "VCFRONT_WAKEUP_REASON_POWER_ON_RESET" 8 "VCFRONT_WAKEUP_REASON_12V_SUPPORT_REQUIRED" 9 "VCFRONT_WAKEUP_REASON_SLEEP_FAILED" 2 "VCFRONT_WAKEUP_REASON_SWITCH_INPUT" ;
VAL_ 1057 VCFRONT_nmKeepAwakeReason 7 "VCFRONT_KEEPAWAKE_REASON_WIPER" 0 "VCFRONT_KEEPAWAKE_REASON_NONE_SNA" 1 "VCFRONT_KEEPAWAKE_REASON_IBS" 15 "VCFRONT_KEEPAWAKE_REASON_MULTIPLE" 4 "VCFRONT_KEEPAWAKE_REASON_FRUNK_LIGHT" 5 "VCFRONT_KEEPAWAKE_REASON_12V_SUPPORT_REQUIRED" 3 "VCFRONT_KEEPAWAKE_REASON_EFUSE_FAULTED" 9 "VCFRONT_KEEPAWAKE_REASON_UDS_ACTIVE" 8 "VCFRONT_KEEPAWAKE_REASON_FLASHER" 6 "VCFRONT_KEEPAWAKE_REASON_VCFRONT_WAKEUP_REQUEST" 14 "VCFRONT_KEEPAWAKE_REASON_OTHER" 2 "VCFRONT_KEEPAWAKE_REASON_CLOSURE_LATCH" ;
VAL_ 645 UI_rightLiftSwitchDown 2 "SWITCH_ON" 0 "SWITCH_SNA" 3 "SWITCH_FAULT" 1 "SWITCH_OFF" ;
VAL_ 645 UI_rightLiftSwitchUp 2 "SWITCH_ON" 0 "SWITCH_SNA" 3 "SWITCH_FAULT" 1 "SWITCH_OFF" ;
VAL_ 645 UI_rightBackrestSwitchDown 2 "SWITCH_ON" 0 "SWITCH_SNA" 3 "SWITCH_FAULT" 1 "SWITCH_OFF" ;
VAL_ 645 UI_rightBackrestSwitchUp 2 "SWITCH_ON" 0 "SWITCH_SNA" 3 "SWITCH_FAULT" 1 "SWITCH_OFF" ;
VAL_ 645 UI_leftLiftSwitchDown 2 "SWITCH_ON" 0 "SWITCH_SNA" 3 "SWITCH_FAULT" 1 "SWITCH_OFF" ;
VAL_ 645 UI_leftLiftSwitchUp 2 "SWITCH_ON" 0 "SWITCH_SNA" 3 "SWITCH_FAULT" 1 "SWITCH_OFF" ;
VAL_ 645 UI_leftBackrestSwitchDown 2 "SWITCH_ON" 0 "SWITCH_SNA" 3 "SWITCH_FAULT" 1 "SWITCH_OFF" ;
VAL_ 645 UI_leftBackrestSwitchUp 2 "SWITCH_ON" 0 "SWITCH_SNA" 3 "SWITCH_FAULT" 1 "SWITCH_OFF" ;
VAL_ 645 UI_driverProfileRecallIndex 4 "UI_DRIVER_RECALL_4" 2 "UI_DRIVER_RECALL_2" 5 "UI_DRIVER_RECALL_5" 3 "UI_DRIVER_RECALL_3" 0 "UI_DRIVER_RECALL_SNA" 1 "UI_DRIVER_RECALL_1" ;
VAL_ 1445 DIS_a066_errorType 4 "CAN_RECEIVE_ERROR_SEQUENCE" 5 "CAN_RECEIVE_ERROR_DATA_INVALID" 1 "CAN_RECEIVE_ERROR_LENGTH_SHORT" 2 "CAN_RECEIVE_ERROR_LENGTH_LONG" 6 "CAN_RECEIVE_ERROR_UNKNOWN_ID" 0 "CAN_RECEIVE_ERROR_NONE" 3 "CAN_RECEIVE_ERROR_CHECKSUM" ;
VAL_ 1445 DIS_a038_reason 0 "UNDERVOLTAGE_PRE_CHARGE" 2 "DI_BMS_VOLTAGE_MISMATCH" 1 "UNDERVOLTAGE_HV_UP" ;
VAL_ 1445 DIS_a115_sensors 1 "PHASEDIFF_12" 0 "PHASEDIFF_IRR" 3 "PHASEDIFF_23" 2 "PHASEDIFF_13" ;
VAL_ 1445 DIS_a066_canID 659 "UI_chassisControl" 530 "BMS_status" 577 "VCFRONT_coolant" 1925 "DBG_dynoOpenLoop" 1862 "DBG_dynoControl" 340 "PM_state" 306 "BMS_hvBusStatus" 548 "PCS_dcdcStatus" 801 "VCFRONT_sensors" 2047 "GTW_carConfig" 1910 "DBG_xcpDISCommand" 1541 "UDS_disRequest" 680 "EPBL_status" 744 "EPBR_status" 468 "PMS_state" 1280 "UI_debugECU" 545 "VCFRONT_LVPowerState" ;
VAL_ 1445 DIS_a093_errorType 0 "DI_CAN_HARDWARE_RECEIVE_ERROR" 1 "DI_CAN_HARDWARE_TRANSMIT_ERROR" ;
VAL_ 1445 DIS_a055_torqueType 2 "PEDAL_POSITION" 1 "TORQUE_COMMAND" 0 "TORQUE_ESTIMATE" ;
VAL_ 1445 DIS_a149_state 2 "OIL_PUMP_COLD_STARTUP" 0 "OIL_PUMP_STANDBY" 1 "OIL_PUMP_ENABLE" 6 "OIL_PUMP_FAULTED" 7 "OIL_PUMP_SNA" ;
VAL_ 1445 DIS_a153_state 2 "OIL_PUMP_COLD_STARTUP" 0 "OIL_PUMP_STANDBY" 1 "OIL_PUMP_ENABLE" 6 "OIL_PUMP_FAULTED" 7 "OIL_PUMP_SNA" ;
VAL_ 1445 DIS_a156_safeStateRecommend 0 "PSTG_SAFESTATE_NONE" 3 "PSTG_SAFESTATE_3PS_LOW" 2 "PSTG_SAFESTATE_3PS_HIGH" 1 "PSTG_SAFESTATE_ALL_OFF" ;
VAL_ 1445 DIS_a156_result 2 "PSTG_OBS_RESULT_SPEED_LOW" 0 "PSTG_OBS_RESULT_SUCCESS" 1 "PSTG_OBS_RESULT_SENSOR_BAD" ;
VAL_ 1445 DIS_a095_canID 659 "UI_chassisControl" 530 "BMS_status" 577 "VCFRONT_coolant" 1925 "DBG_dynoOpenLoop" 1862 "DBG_dynoControl" 340 "PM_state" 306 "BMS_hvBusStatus" 548 "PCS_dcdcStatus" 801 "VCFRONT_sensors" 2047 "GTW_carConfig" 1910 "DBG_xcpDISCommand" 1541 "UDS_disRequest" 680 "EPBL_status" 744 "EPBR_status" 468 "PMS_state" 1280 "UI_debugECU" 545 "VCFRONT_LVPowerState" ;
VAL_ 1445 DIS_a093_canID 659 "UI_chassisControl" 530 "BMS_status" 577 "VCFRONT_coolant" 1925 "DBG_dynoOpenLoop" 1862 "DBG_dynoControl" 340 "PM_state" 306 "BMS_hvBusStatus" 548 "PCS_dcdcStatus" 801 "VCFRONT_sensors" 2047 "GTW_carConfig" 1910 "DBG_xcpDISCommand" 1541 "UDS_disRequest" 680 "EPBL_status" 744 "EPBR_status" 468 "PMS_state" 1280 "UI_debugECU" 545 "VCFRONT_LVPowerState" ;
VAL_ 1445 DIS_a108_blockingAlert 195 "DI_a195_vdcEspSlipFr" 31 "DI_a031_phaseAcurrentOffset" 185 "DI_a185_autoparkAborted" 60 "DI_a060_heatsinkUT" 147 "DI_a147_highTorqueWearLimit" 160 "DI_a160_busVoltageAnomaly" 146 "DI_a146_pbrkPanicEpbFault" 9 "DI_a009_hwEncoderB" 5 "DI_a005_hwPhaseBpeak" 171 "DI_a171_driveRailNotRequested" 191 "DI_a191_brakeShiftReq" 241 "DI_a241_systemThermallyLimited" 30 "DI_a030_phaseCrms" 233 "DI_a233_diMsgMissed" 1 "DI_a001_hwPhaseAgateDrive" 208 "DI_a208_vdcPowertrainTorqueRe" 145 "DI_a145_pbrkPanicSkid" 220 "DI_a220_vdcUndersteerDecelActive" 199 "DI_a199_vdcFaulted" 167 "DI_a167_keyNotAuthenticated" 228 "DI_a228_brakeTempEstUnavailable" 172 "DI_a172_accelPressedInNP" 100 "DI_a100_assertion" 3 "DI_a003_hwPhaseCgateDrive" 71 "DI_a071_busDisconnected" 215 "DI_a215_velEstWheelSpeedNonCGRe" 18 "DI_a018_hw12vSupplyUV" 91 "DI_a091_espMIA" 134 "DI_a134_wheelSpeedIrrational" 12 "DI_a012_accel5VSupply" 54 "DI_a054_driveInverterOT" 222 "DI_a222_vdcDisabled" 217 "DI_a217_vdcOutputIrrational" 124 "DI_a124_cruiseFault" 240 "DI_a240_torqueSplitStuck" 51 "DI_a051_batteryOvercurrent" 61 "DI_a061_heatsinkSensor" 96 "DI_a096_memoryError" 87 "DI_a087_gtwMIA" 154 "DI_a154_resolver" 85 "DI_a085_proximityInEnable" 142 "DI_a142_highLashAngle" 180 "DI_a180_crsSeatbeltUnbuckled" 35 "DI_a035_phaseCurrentBalance" 227 "DI_a227_contactorsNotClosed" 26 "DI_a026_phaseBpeak" 131 "DI_a131_highSpeedWearLimit" 109 "DI_a109_cruiseMIA" 229 "DI_a229_batteryIsHeating" 104 "DI_a104_proximityIrrational" 163 "DI_a163_unparkReq" 244 "DI_a244_mechanical3PS" 90 "DI_a090_pmMIA" 17 "DI_a017_hwPedalMonitor" 88 "DI_a088_uiMIA" 98 "DI_a098_intTimeTooLong" 205 "DI_a205_vdcRcmLateral" 11 "DI_a011_swPowerStageNotReady" 14 "DI_a014_activeDamping" 21 "DI_a021_hwBusOV" 183 "DI_a183_holdReleaseRqrd" 202 "DI_a202_excessHeatUnavailable" 224 "DI_a224_brakeOverTemp" 74 "DI_a074_motorEncoder" 22 "DI_a022_hw5vSupplyUV" 115 "DI_a115_heatsinkTempImbalance" 103 "DI_a103_lowFlow" 235 "DI_a235_trackModeActive" 108 "DI_a108_stateTrans" 186 "DI_a186_brakeStand" 181 "DI_a181_rearMotorMode" 159 "DI_a159_cruiseSelfCheck" 200 "DI_a200_vdcModelBasedPlausibility" 197 "DI_a197_vdcEspWheelSaturations" 201 "DI_a201_regenLimited" 82 "DI_a082_accelTrack2" 187 "DI_a187_pedalMisapplication" 64 "DI_a064_torqueIntervention" 193 "DI_a193_vdcEspBrakeTorqueFr" 43 "DI_a043_outletOT" 123 "DI_a123_lossMotorControl" 40 "DI_a040_disMIA" 65 "DI_a065_canHardwareBusB" 81 "DI_a081_accelTrack1" 79 "DI_a079_adcRefHigh" 0 "DI_ALERT_DO_NOT_USE_ZERO" 80 "DI_a080_accelSynch" 207 "DI_a207_vdcPowertrainTorqueFr" 225 "DI_a225_tmpEstPlausibility" 182 "DI_a182_frontMotorMode" 232 "DI_a232_velocityEstimatorDegraded" 29 "DI_a029_phaseBrms" 162 "DI_a162_shiftDenied" 170 "DI_a170_pedalFoul" 110 "DI_a110_brakeMIA" 218 "DI_a218_vdcOSPreControlActive" 66 "DI_a066_canDataBusB" 165 "DI_a165_cruiseCancelled" 44 "DI_a044_outletUT" 157 "DI_a157_rcmMIA" 213 "DI_a213_velEstWheelSpeedCGRe" 133 "DI_a133_capacitorOT" 105 "DI_a105_cpMIA" 221 "DI_a221_vdcUndersteerdMzActive" 135 "DI_a135_vehicleHoldFault" 231 "DI_a231_ptcMIA" 230 "DI_a230_cmpMIA" 20 "DI_a020_hwMotorEncoder" 158 "DI_a158_ibstMIA" 175 "DI_a175_crsNotAvailable" 50 "DI_a050_noStatorSensor" 112 "DI_a112_noPhaseCurrent" 173 "DI_a173_bothPedalsPressed" 7 "DI_a007_hwHvilNotPresent" 125 "DI_a125_noBatteryPower" 129 "DI_a129_epbNotApplied" 152 "DI_a152_linError" 184 "DI_a184_autoparkCanceled" 137 "DI_a137_noCapableDriveUnits" 63 "DI_a063_systemGracefulPowerOff" 226 "DI_a226_sysStartConditionNotMet" 138 "DI_a138_frontUnitDisabled" 177 "DI_a177_tireFitmentChanged" 28 "DI_a028_phaseArms" 198 "DI_a198_vdcEspMCPressAndSteering" 59 "DI_a059_heatsinkOT" 56 "DI_a056_ambientOT" 32 "DI_a032_phaseBcurrentOffset" 164 "DI_a164_brakeOverride" 39 "DI_a039_noRegen" 234 "DI_a234_pcsMIA" 176 "DI_a176_EBRreleased" 72 "DI_a072_gateDriveFaultCounter" 73 "DI_a073_motorSpeed" 203 "DI_a203_TCReducedByADD" 196 "DI_a196_vdcEspSlipRe" 155 "DI_a155_vcfrontMIA" 36 "DI_a036_busOV" 212 "DI_a212_velEstWheelSpeedCGFr" 47 "DI_a047_statorSensor1" 86 "DI_a086_hvilNotPresent" 57 "DI_a057_ambientUT" 37 "DI_a037_busUV" 156 "DI_a156_currentObserver" 243 "DI_a243_ecuLogAvailable" 194 "DI_a194_vdcEspBrakeTorqueRe" 58 "DI_a058_ambientSensor" 206 "DI_a206_vdcRcmVertical" 151 "DI_a151_shockTorqueLimiter" 2 "DI_a002_hwPhaseBgateDrive" 83 "DI_a083_brakePedalSensor" 210 "DI_a210_vdcOtherControllerStates" 169 "DI_a169_regenOffOverride" 97 "DI_a097_eepromError" 136 "DI_a136_spiError" 25 "DI_a025_phaseApeak" 46 "DI_a046_statorOT" 76 "DI_a076_12vSupplyOV" 130 "DI_a130_aebFault" 149 "DI_a149_oilPumpFailure" 41 "DI_a041_driverBrakeApplyCheck" 126 "DI_a126_limpMode" 27 "DI_a027_phaseCpeak" 15 "DI_a015_immobilizer" 214 "DI_a214_velEstWheelSpeedNonCGFr" 189 "DI_a189_garageShiftWithPedal" 127 "DI_a127_gracefulPowerOff" 99 "DI_a099_threadOverrun" 114 "DI_a114_noMotorSpeed" 139 "DI_a139_rearUnitDisabled" 33 "DI_a033_phaseAcurrentSensor" 242 "DI_a242_rotorOffsetLearning" 116 "DI_a116_powerConvIrrational" 45 "DI_a045_outletSensor" 16 "DI_a016_safeStateApplied" 143 "DI_a143_mcuLimitActive" 78 "DI_a078_adcRefLow" 223 "DI_a223_tractionControlDisabled" 211 "DI_a211_vdcMotorSpeeds" 94 "DI_a094_canDataBusA" 67 "DI_a067_canOverrunBusB" 24 "DI_a024_selfTest" 148 "DI_a148_overtorqueUsed" 19 "DI_a019_hwAccelPedalPower" 166 "DI_a166_driverLeft" 192 "DI_a192_invalidOdometer" 174 "DI_a174_notOkToStartDrive" 122 "DI_a122_highStackUsage" 204 "DI_a204_vdcRcmLongitudinal" 161 "DI_a161_epas3pMIA" 219 "DI_a219_vdcOversteerdMzActive" 55 "DI_a055_trqCrossCheck" 144 "DI_a144_configMismatch" 117 "DI_a117_diMIA" 38 "DI_a038_busVsensor" 141 "DI_a141_dasMIA" 70 "DI_a070_12vSupplySensor" 95 "DI_a095_canOverrunBusA" 42 "DI_a042_inletSensor" 150 "DI_a150_busVD" 92 "DI_a092_bmsMIA" 121 "DI_a121_motorControlRegulation" 239 "DI_a239_neutralRequestByPM" 8 "DI_a008_hwEncoderA" 4 "DI_a004_hwPhaseApeak" 89 "DI_a089_sccmMIA" 6 "DI_a006_hwPhaseCpeak" 106 "DI_a106_absMIA" 75 "DI_a075_motorSpeedMismatch" 62 "DI_a062_systemLimpMode" 93 "DI_a093_canHardwareBusA" 168 "DI_a168_proximityDriveDenial" 77 "DI_a077_12vSupplyUV" 34 "DI_a034_phaseBcurrentSensor" 209 "DI_a209_vdcVehicleSpeed" 153 "DI_a153_oilPump" 216 "DI_a216_vdcMBPAlmostTripped" 23 "DI_a023_carNotParked" 113 "DI_a113_noFuncHeatsinkSensor" ;
VAL_ 1445 DIS_a098_fluxState 2 "DI_FLUXSTATE_STANDBY" 0 "DI_FLUXSTATE_START" 5 "DI_FLUXSTATE_ENABLED" 1 "DI_FLUXSTATE_TEST" 7 "DI_FLUXSTATE_VCONTROL" 4 "DI_FLUXSTATE_FLUX_DOWN" 9 "DI_FLUXSTATE_FAULT" 3 "DI_FLUXSTATE_FLUX_UP" 6 "DI_FLUXSTATE_ICONTROL" ;
VAL_ 1445 DIS_a065_errorType 0 "DI_CAN_HARDWARE_RECEIVE_ERROR" 1 "DI_CAN_HARDWARE_TRANSMIT_ERROR" ;
VAL_ 1445 DIS_a014_adState 0 "AD_STATE_STARTUP" 3 "AD_STATE_FAULTED" 1 "AD_STATE_NORMAL" 2 "AD_STATE_BACKUP" ;
VAL_ 1445 DIS_a156_powerPolarity 3 "PSTG_OBS_POLARITY_ALL" 0 "PSTG_OBS_POLARITY_ZERO" 1 "PSTG_OBS_POLARITY_NEGATIVE" 2 "PSTG_OBS_POLARITY_POSITIVE" ;
VAL_ 1445 DIS_a094_errorType 4 "CAN_RECEIVE_ERROR_SEQUENCE" 5 "CAN_RECEIVE_ERROR_DATA_INVALID" 1 "CAN_RECEIVE_ERROR_LENGTH_SHORT" 2 "CAN_RECEIVE_ERROR_LENGTH_LONG" 6 "CAN_RECEIVE_ERROR_UNKNOWN_ID" 0 "CAN_RECEIVE_ERROR_NONE" 3 "CAN_RECEIVE_ERROR_CHECKSUM" ;
VAL_ 1445 DIS_a024_state 1 "SOPT_STATE_PSTG_BRING_UP" 5 "SOPT_STATE_CURRENT_TEST_POS" 6 "SOPT_STATE_CURRENT_TEST_NEG" 2 "SOPT_STATE_ASC_TEST" 0 "SOPT_STATE_INIT" 10 "SOPT_STATE_TEST_FAILED" 3 "SOPT_STATE_ASC_TEST_PASSED" 4 "SOPT_STATE_PWM_ENABLE" 9 "SOPT_STATE_TEST_SKIPPED" 8 "SOPT_STATE_TEST_PASSED" 7 "SOPT_STATE_TEST_PRE_PASSED" 11 "SOPT_STATE_TEST_RESTART" ;
VAL_ 1445 DIS_a156_phaseCPolarity 3 "PSTG_OBS_POLARITY_ALL" 0 "PSTG_OBS_POLARITY_ZERO" 1 "PSTG_OBS_POLARITY_NEGATIVE" 2 "PSTG_OBS_POLARITY_POSITIVE" ;
VAL_ 1445 DIS_a024_failReason 4 "SOPT_FAIL_TIMEDOUT" 2 "SOPT_FAIL_NEG_CURRENT" 1 "SOPT_FAIL_POS_CURRENT" 3 "SOPT_FAIL_DISAGREE" 5 "SOPT_FAIL_GATE_DRIVE_ERROR" 6 "SOPT_FAIL_FAULT_PRESENT" 0 "SOPT_FAIL_CACHED" 7 "SOPT_FAIL_ASC_TEST" ;
VAL_ 1445 DIS_a156_phaseBPolarity 3 "PSTG_OBS_POLARITY_ALL" 0 "PSTG_OBS_POLARITY_ZERO" 1 "PSTG_OBS_POLARITY_NEGATIVE" 2 "PSTG_OBS_POLARITY_POSITIVE" ;
VAL_ 1445 DIS_a156_phaseAPolarity 3 "PSTG_OBS_POLARITY_ALL" 0 "PSTG_OBS_POLARITY_ZERO" 1 "PSTG_OBS_POLARITY_NEGATIVE" 2 "PSTG_OBS_POLARITY_POSITIVE" ;
VAL_ 1445 DIS_a064_torqueCmdState 8 "TorqueCmd_Invalid" 6 "TorqueCmd_Valid" 0 "TorqueCmd_SNA" ;
VAL_ 1445 DIS_a156_observation 9 "PSTG_OBS_SINGLE_OPEN_PHASE" 8 "PSTG_OBS_DIODE_OPEN_LOW" 1 "PSTG_OBS_THREE_PHASE_SHORT" 6 "PSTG_OBS_DOUBLE_SHORT_LOW" 2 "PSTG_OBS_UNCONTROLLED_REGEN" 10 "PSTG_OBS_UNKNOWN" 5 "PSTG_OBS_DOUBLE_SHORT_HIGH" 7 "PSTG_OBS_DIODE_OPEN_HIGH" 4 "PSTG_OBS_SINGLE_SHORT_LOW" 3 "PSTG_OBS_SINGLE_SHORT_HIGH" 0 "PSTG_OBS_NO_CURRENT" ;
VAL_ 1445 DIS_a061_reason 1 "RAILED" 0 "RATE_OF_CHANGE" ;
VAL_ 1445 DIS_a016_oldSafeState 0 "PSTG_SAFESTATE_NONE" 3 "PSTG_SAFESTATE_3PS_LOW" 2 "PSTG_SAFESTATE_3PS_HIGH" 1 "PSTG_SAFESTATE_ALL_OFF" ;
VAL_ 1445 DIS_a097_errorType 4 "LOST" 5 "DPOT_READ" 1 "READ" 6 "DPOT_WRITE" 2 "WRITE" 0 "OPEN" 3 "CRC" ;
VAL_ 1445 DIS_a121_badRegReason 3 "IQ_OFF_TARGET" 5 "TORQUE_OFF_TARGET" 2 "ID_OFF_TARGET" 1 "RMS_I_HIGH" 4 "FLUX_OFF_TARGET" ;
VAL_ 1445 DIS_a061_sensor 1 "PH2" 2 "PH3" 0 "PH1" ;
VAL_ 1445 DIS_a122_taskID 1 "DI_STACK_CONTROL" 7 "DI_STACK_IMM" 0 "DI_STACK_SYSTEM" 2 "DI_STACK_IDLE" 8 "DI_STACK_10Hz" 6 "DI_STACK_XCP" 4 "DI_STACK_EEP" 3 "DI_STACK_DHWF" 5 "DI_STACK_UDS" ;
VAL_ 1445 DIS_a126_limpReason 7 "DI_LIMP_LOW_FLOW" 13 "DI_LIMP_WRONG_CS_CALIBRATION" 19 "DI_LIMP_CONFIG_MISMATCH" 28 "DI_LIMP_OIL_PUMP_FAILURE" 26 "DI_LIMP_SLAVE_MIA" 30 "DI_LIMP_HEATSINK_SENSOR_IRRATIONAL" 8 "DI_LIMP_OUTLET_TEMP" 23 "DI_LIMP_CAPACITOR_OVERTEMP" 16 "DI_LIMP_PMHEARTBEAT" 1 "DI_LIMP_BUSV_SENSOR_IRRATIONAL" 25 "DI_LIMP_SLAVE_REQUEST" 11 "DI_LIMP_DELTAT_TOO_NEGATIVE" 17 "DI_LIMP_PMREQUEST" 5 "DI_LIMP_12V_SUPPLY_UNDERVOLTAGE" 3 "DI_LIMP_NO_FUNC_HEATSINK_SENSOR" 0 "DI_LIMP_PHASE_IMBALANCE" 27 "DI_LIMP_FACTORY_GLIDER" 20 "DI_LIMP_DI_MIA" 15 "DI_LIMP_TRQ_CROSS_CHECK" 21 "DI_LIMP_TRQCMD_VALIDITY_UNKNOWN" 24 "DI_LIMP_CONTACTOR_WELD" 29 "DI_LIMP_OIL_PUMP_FLUID_OVERTEMP" 2 "DI_LIMP_NO_FUNC_STATORT_SENSOR" 14 "DI_LIMP_EXTERNAL_COMMAND" 6 "DI_LIMP_BMS_MIA" 22 "DI_LIMP_GTW_MIA" 9 "DI_LIMP_AMBIENT_TEMP" 10 "DI_LIMP_DELTAT_TOO_POSITIVE" 18 "DI_LIMP_HEATSINK_TEMP" 12 "DI_LIMP_STATOR_TEMP" 4 "DI_LIMP_NO_FLUID" ;
VAL_ 1445 DIS_a094_canID 659 "UI_chassisControl" 530 "BMS_status" 577 "VCFRONT_coolant" 1925 "DBG_dynoOpenLoop" 1862 "DBG_dynoControl" 340 "PM_state" 306 "BMS_hvBusStatus" 548 "PCS_dcdcStatus" 801 "VCFRONT_sensors" 2047 "GTW_carConfig" 1910 "DBG_xcpDISCommand" 1541 "UDS_disRequest" 680 "EPBL_status" 744 "EPBR_status" 468 "PMS_state" 1280 "UI_debugECU" 545 "VCFRONT_LVPowerState" ;
VAL_ 1445 DIS_a011_reason 0 "GATE_DRIVE_SUPPLY" 3 "FAULT_DURING_CONFIG" 1 "REG_DATA_MISMATCH" 2 "CRC_MISMATCH" ;
VAL_ 1445 DIS_a064_interventionType 7 "TRQP_excessiveRegenTorque" 8 "TRQP_torqueInNeutral" 0 "TRQP_masterTorqueMonitorShutoff" 2 "TRQP_torqueCmdInvalid" 1 "TRQP_resolver" 3 "TRQP_cruiseFault" 10 "TRQP_switchOffPathTestFail" 5 "TRQP_accumulatedTorque" 9 "TRQP_inconsistentTorqueSign" 6 "TRQP_torqueReversal" 4 "TRQP_motorMovementDetected" ;
VAL_ 1445 DIS_a156_initialSafeState 0 "PSTG_SAFESTATE_NONE" 3 "PSTG_SAFESTATE_3PS_LOW" 2 "PSTG_SAFESTATE_3PS_HIGH" 1 "PSTG_SAFESTATE_ALL_OFF" ;
VAL_ 1445 DIS_a065_canID 659 "UI_chassisControl" 530 "BMS_status" 577 "VCFRONT_coolant" 1925 "DBG_dynoOpenLoop" 1862 "DBG_dynoControl" 340 "PM_state" 306 "BMS_hvBusStatus" 548 "PCS_dcdcStatus" 801 "VCFRONT_sensors" 2047 "GTW_carConfig" 1910 "DBG_xcpDISCommand" 1541 "UDS_disRequest" 680 "EPBL_status" 744 "EPBR_status" 468 "PMS_state" 1280 "UI_debugECU" 545 "VCFRONT_LVPowerState" ;
VAL_ 1445 DIS_a090_reason 0 "TOOSLOW" 1 "TOOFAST" ;
VAL_ 1445 DIS_a127_gpoReason 3 "DI_GPO_FLUID_DELTAT" 4 "DI_GPO_AMBIENT_OVERTEMP" 0 "DI_GPO_OUTLET_OVERTEMP" 8 "DI_GPO_MOTOR_HALT_REQUEST" 1 "DI_GPO_HEATSINK_OVERTEMP" 2 "DI_GPO_STATOR_OVERTEMP" 7 "DI_GPO_CAPACITOR_OVERTEMP" 6 "DI_GPO_NOT_ENOUGH_12V" 5 "DI_GPO_NO_BATTERY_POWER" ;
VAL_ 1445 DIS_a062_limpReason 7 "DI_LIMP_LOW_FLOW" 13 "DI_LIMP_WRONG_CS_CALIBRATION" 19 "DI_LIMP_CONFIG_MISMATCH" 28 "DI_LIMP_OIL_PUMP_FAILURE" 26 "DI_LIMP_SLAVE_MIA" 30 "DI_LIMP_HEATSINK_SENSOR_IRRATIONAL" 8 "DI_LIMP_OUTLET_TEMP" 23 "DI_LIMP_CAPACITOR_OVERTEMP" 16 "DI_LIMP_PMHEARTBEAT" 1 "DI_LIMP_BUSV_SENSOR_IRRATIONAL" 25 "DI_LIMP_SLAVE_REQUEST" 11 "DI_LIMP_DELTAT_TOO_NEGATIVE" 17 "DI_LIMP_PMREQUEST" 5 "DI_LIMP_12V_SUPPLY_UNDERVOLTAGE" 3 "DI_LIMP_NO_FUNC_HEATSINK_SENSOR" 0 "DI_LIMP_PHASE_IMBALANCE" 27 "DI_LIMP_FACTORY_GLIDER" 20 "DI_LIMP_DI_MIA" 15 "DI_LIMP_TRQ_CROSS_CHECK" 21 "DI_LIMP_TRQCMD_VALIDITY_UNKNOWN" 24 "DI_LIMP_CONTACTOR_WELD" 29 "DI_LIMP_OIL_PUMP_FLUID_OVERTEMP" 2 "DI_LIMP_NO_FUNC_STATORT_SENSOR" 14 "DI_LIMP_EXTERNAL_COMMAND" 6 "DI_LIMP_BMS_MIA" 22 "DI_LIMP_GTW_MIA" 9 "DI_LIMP_AMBIENT_TEMP" 10 "DI_LIMP_DELTAT_TOO_POSITIVE" 18 "DI_LIMP_HEATSINK_TEMP" 12 "DI_LIMP_STATOR_TEMP" 4 "DI_LIMP_NO_FLUID" ;
VAL_ 1445 DIS_a152_errorType 5 "LIN_HEADER_ERROR" 4 "LIN_OVERFLOW_ERROR" 6 "LIN_TIMEOUT_ERROR" 2 "LIN_CHECKSUM_ERROR" 3 "LIN_SCHEDULE_ERROR" 0 "LIN_NO_ERROR" 1 "LIN_FRAMING_ERROR" ;
VAL_ 1445 DIS_a136_spiErrorType 4 "DI_SPI_CANID_MISMATCH" 2 "DI_SPI_SYNC_BIT" 7 "DI_SPI_BUFFER0_OVERWRITE" 1 "DI_SPI_RESERVED" 3 "DI_SPI_SUBID_SEQUENCE" 0 "DI_SPI_NONE" 6 "DI_SPI_UNKNOWN_ID" 5 "DI_SPI_CRC_MISMATCH" ;
VAL_ 1445 DIS_a202_reason 1 "DI_WASTE_UNAVAILABLE_NO_ALERT" 5 "DI_WASTE_UNAVAILABLE_GPO" 3 "DI_WASTE_UNAVAILABLE_MOVEMENT" 2 "DI_WASTE_UNAVAILABLE_PARKBRAKE" 0 "DI_WASTE_UNAVAILABLE_NONE" 4 "DI_WASTE_UNAVAILABLE_LIMP" 7 "DI_WASTE_UNAVAILABLE_SERVICE_MODE" 6 "DI_WASTE_UNAVAILABLE_UPDATE_STARTED" ;
VAL_ 1445 DIS_a123_lossReason 3 "HIGH_VARIANCE" 1 "NO_FLUX_UP" 2 "NO_TORQUE" ;
VAL_ 1445 DIS_a016_newSafeState 0 "PSTG_SAFESTATE_NONE" 3 "PSTG_SAFESTATE_3PS_LOW" 2 "PSTG_SAFESTATE_3PS_HIGH" 1 "PSTG_SAFESTATE_ALL_OFF" ;
VAL_ 1445 DIS_a067_canID 659 "UI_chassisControl" 530 "BMS_status" 577 "VCFRONT_coolant" 1925 "DBG_dynoOpenLoop" 1862 "DBG_dynoControl" 340 "PM_state" 306 "BMS_hvBusStatus" 548 "PCS_dcdcStatus" 801 "VCFRONT_sensors" 2047 "GTW_carConfig" 1910 "DBG_xcpDISCommand" 1541 "UDS_disRequest" 680 "EPBL_status" 744 "EPBR_status" 468 "PMS_state" 1280 "UI_debugECU" 545 "VCFRONT_LVPowerState" ;
VAL_ 1445 DIS_alertType 0 "ALERT_CLEARED" 1 "ALERT_SET" ;
VAL_ 1445 DIS_alertID 91 "DIS_a091_espMIA" 134 "DIS_a134_wheelSpeedIrrational" 156 "DIS_a156_currentObserver" 37 "DIS_a037_busUV" 243 "DIS_a243_ecuLogAvailable" 58 "DIS_a058_ambientSensor" 2 "DIS_a002_hwPhaseBgateDrive" 47 "DIS_a047_statorSensor1" 57 "DIS_a057_ambientUT" 5 "DIS_a005_hwPhaseBpeak" 241 "DIS_a241_systemThermallyLimited" 36 "DIS_a036_busOV" 72 "DIS_a072_gateDriveFaultCounter" 60 "DIS_a060_heatsinkUT" 32 "DIS_a032_phaseBcurrentOffset" 28 "DIS_a028_phaseArms" 9 "DIS_a009_hwEncoderB" 56 "DIS_a056_ambientOT" 50 "DIS_a050_noStatorSensor" 112 "DIS_a112_noPhaseCurrent" 153 "DIS_a153_oilPump" 7 "DIS_a007_hwHvilNotPresent" 77 "DIS_a077_12vSupplyUV" 152 "DIS_a152_linError" 34 "DIS_a034_phaseBcurrentSensor" 93 "DIS_a093_canHardwareBusA" 121 "DIS_a121_motorControlRegulation" 8 "DIS_a008_hwEncoderA" 95 "DIS_a095_canOverrunBusA" 75 "DIS_a075_motorSpeedMismatch" 66 "DIS_a066_canDataBusB" 92 "DIS_a092_bmsMIA" 106 "DIS_a106_absMIA" 6 "DIS_a006_hwPhaseCpeak" 62 "DIS_a062_systemLimpMode" 4 "DIS_a004_hwPhaseApeak" 133 "DIS_a133_capacitorOT" 29 "DIS_a029_phaseBrms" 161 "DIS_a161_epas3pMIA" 40 "DIS_a040_disMIA" 70 "DIS_a070_12vSupplySensor" 79 "DIS_a079_adcRefHigh" 64 "DIS_a064_torqueIntervention" 55 "DIS_a055_trqCrossCheck" 117 "DIS_a117_diMIA" 43 "DIS_a043_outletOT" 123 "DIS_a123_lossMotorControl" 225 "DIS_a225_tmpEstPlausibility" 0 "DIS_ALERT_DO_NOT_USE_ZERO" 94 "DIS_a094_canDataBusA" 74 "DIS_a074_motorEncoder" 19 "DIS_a019_hwAccelPedalPower" 22 "DIS_a022_hw5vSupplyUV" 78 "DIS_a078_adcRefLow" 116 "DIS_a116_powerConvIrrational" 108 "DIS_a108_stateTrans" 14 "DIS_a014_activeDamping" 202 "DIS_a202_excessHeatUnavailable" 90 "DIS_a090_pmMIA" 114 "DIS_a114_noMotorSpeed" 21 "DIS_a021_hwBusOV" 244 "DIS_a244_mechanical3PS" 88 "DIS_a088_uiMIA" 127 "DIS_a127_gracefulPowerOff" 229 "DIS_a229_batteryIsHeating" 87 "DIS_a087_gtwMIA" 26 "DIS_a026_phaseBpeak" 97 "DIS_a097_eepromError" 154 "DIS_a154_resolver" 61 "DIS_a061_heatsinkSensor" 131 "DIS_a131_highSpeedWearLimit" 76 "DIS_a076_12vSupplyOV" 18 "DIS_a018_hw12vSupplyUV" 54 "DIS_a054_driveInverterOT" 71 "DIS_a071_busDisconnected" 100 "DIS_a100_assertion" 86 "DIS_a086_hvilNotPresent" 1 "DIS_a001_hwPhaseAgateDrive" 233 "DIS_a233_diMsgMissed" 3 "DIS_a003_hwPhaseCgateDrive" 30 "DIS_a030_phaseCrms" 151 "DIS_a151_shockTorqueLimiter" 73 "DIS_a073_motorSpeed" 31 "DIS_a031_phaseAcurrentOffset" 59 "DIS_a059_heatsinkOT" 234 "DIS_a234_pcsMIA" 155 "DIS_a155_vcfrontMIA" 160 "DIS_a160_busVoltageAnomaly" 147 "DIS_a147_highTorqueWearLimit" 113 "DIS_a113_noFuncHeatsinkSensor" 129 "DIS_a129_epbNotApplied" 158 "DIS_a158_ibstMIA" 150 "DIS_a150_busVD" 42 "DIS_a042_inletSensor" 157 "DIS_a157_rcmMIA" 44 "DIS_a044_outletUT" 110 "DIS_a110_brakeMIA" 20 "DIS_a020_hwMotorEncoder" 65 "DIS_a065_canHardwareBusB" 144 "DIS_a144_configMismatch" 38 "DIS_a038_busVsensor" 148 "DIS_a148_overtorqueUsed" 122 "DIS_a122_highStackUsage" 45 "DIS_a045_outletSensor" 16 "DIS_a016_safeStateApplied" 115 "DIS_a115_heatsinkTempImbalance" 24 "DIS_a024_selfTest" 103 "DIS_a103_lowFlow" 67 "DIS_a067_canOverrunBusB" 143 "DIS_a143_mcuLimitActive" 98 "DIS_a098_intTimeTooLong" 99 "DIS_a099_threadOverrun" 11 "DIS_a011_swPowerStageNotReady" 33 "DIS_a033_phaseAcurrentSensor" 17 "DIS_a017_hwPedalMonitor" 242 "DIS_a242_rotorOffsetLearning" 96 "DIS_a096_memoryError" 126 "DIS_a126_limpMode" 149 "DIS_a149_oilPumpFailure" 142 "DIS_a142_highLashAngle" 35 "DIS_a035_phaseCurrentBalance" 25 "DIS_a025_phaseApeak" 27 "DIS_a027_phaseCpeak" 136 "DIS_a136_spiError" 46 "DIS_a046_statorOT" ;
VAL_ 1022 DI_brakeRRTemp 1023 "SNA" ;
VAL_ 1022 DI_brakeRLTemp 1023 "SNA" ;
VAL_ 1022 DI_brakeFRTemp 1023 "SNA" ;
VAL_ 1022 DI_brakeFLTemp 1023 "SNA" ;
VAL_ 1889 PM_vehicleHoldState 1 "DI_VHLD_STATE_STANDBY" 2 "DI_VHLD_STATE_BLEND_IN" 5 "DI_VHLD_STATE_PARK" 4 "DI_VHLD_STATE_BLEND_OUT" 3 "DI_VHLD_STATE_STANDSTILL" 7 "DI_VHLD_STATE_INIT" 0 "DI_VHLD_STATE_UNAVAILABLE" 6 "DI_VHLD_STATE_FAULT" ;
VAL_ 1889 PM_aebState 2 "AEB_CAN_STATE_ENABLED" 1 "AEB_CAN_STATE_STANDBY" 3 "AEB_CAN_STATE_STANDSTILL" 0 "AEB_CAN_STATE_UNAVAILABLE" 4 "AEB_CAN_STATE_FAULT" 7 "AEB_CAN_STATE_SNA" ;
VAL_ 1889 PM_cruiseState 0 "CRS_STATE_UNAVAILABLE" 6 "CRS_STATE_PRE_FAULT" 5 "CRS_STATE_FAULT" 7 "CRS_STATE_PRE_CANCEL" 3 "CRS_STATE_STANDSTILL" 1 "CRS_STATE_STANDBY" 2 "CRS_STATE_ENABLED" 4 "CRS_STATE_OVERRIDE" ;
VAL_ 1889 PM_gear 1 "DI_GEAR_P" 0 "DI_GEAR_INVALID" 7 "DI_GEAR_SNA" 2 "DI_GEAR_R" 3 "DI_GEAR_N" 4 "DI_GEAR_D" ;
VAL_ 1889 PM_debugSelector 105 "Mux105" 14 "Mux16" 103 "Mux103" 20 "Mux20" 104 "Mux104" 11 "Mux11" 21 "Mux21" 102 "Mux102" 10 "Mux10" 51 "Mux51" 13 "Mux13" 50 "Mux50" 22 "Mux22" 15 "Mux19" 101 "Mux101" 12 "Mux12" 23 "Mux23" 100 "Mux100" ;
VAL_ 280 DI_trackModeState 0 "TRACK_MODE_UNAVAILABLE" 1 "TRACK_MODE_AVAILABLE" 2 "TRACK_MODE_ON" ;
VAL_ 280 DI_keepAliveRequest 1 "KEEP_ALIVE" 0 "NO_REQUEST" ;
VAL_ 280 DI_epbRequest 0 "DI_EPBREQUEST_NO_REQUEST" 1 "DI_EPBREQUEST_PARK" 2 "DI_EPBREQUEST_UNPARK" ;
VAL_ 280 DI_tractionControlMode 0 "TC_NORMAL" 1 "TC_SLIP_START" 4 "TC_ROLLS_MODE" 2 "TC_DEV_MODE_1" 5 "TC_DYNO_MODE" 3 "TC_DEV_MODE_2" ;
VAL_ 280 DI_accelPedalPos 255 "SNA" ;
VAL_ 280 DI_immobilizerState 2 "DI_IMM_STATE_AUTHENTICATING" 0 "DI_IMM_STATE_INIT_SNA" 3 "DI_IMM_STATE_DISARMED" 4 "DI_IMM_STATE_IDLE" 6 "DI_IMM_STATE_FAULT" 1 "DI_IMM_STATE_REQUEST" 5 "DI_IMM_STATE_RESET" ;
VAL_ 280 DI_gear 1 "DI_GEAR_P" 0 "DI_GEAR_INVALID" 7 "DI_GEAR_SNA" 2 "DI_GEAR_R" 3 "DI_GEAR_N" 4 "DI_GEAR_D" ;
VAL_ 280 DI_brakePedalState 2 "INVALID" 0 "OFF" 1 "ON" ;
VAL_ 280 DI_systemState 5 "DI_SYS_ENABLE" 1 "DI_SYS_IDLE" 2 "DI_SYS_STANDBY" 0 "DI_SYS_UNAVAILABLE" 3 "DI_SYS_FAULT" 4 "DI_SYS_ABORT" ;
VAL_ 610 VCLEFT_steeringColumnLastRequest 4 "STEERING_COLUMN_REQUEST_IN" 5 "STEERING_COLUMN_REQUEST_OUT" 0 "STEERING_COLUMN_REQUEST_SNA" 3 "STEERING_COLUMN_REQUEST_DOWN" 1 "STEERING_COLUMN_REQUEST_NONE" 2 "STEERING_COLUMN_REQUEST_UP" ;
VAL_ 610 VCLEFT_steeringColumnSMState 3 "STEERING_COLUMN_STATE_MANUAL_CONTROL" 2 "STEERING_COLUMN_STATE_CALIBRATE" 0 "STEERING_COLUMN_STATE_SNA" 1 "STEERING_COLUMN_STATE_RECALL" ;
VAL_ 532 FC_postID 2 "FC_POST_ID_2" 1 "FC_POST_SLAVE" 3 "FC_POST_ID_SNA" 0 "FC_POST_MASTER" ;
VAL_ 532 FC_type 1 "FC_TYPE_CHADEMO" 0 "FC_TYPE_SUPERCHARGER" 7 "FC_TYPE_SNA" 6 "FC_TYPE_OTHER" 5 "FC_TYPE_MC_EVSE" 3 "FC_TYPE_CC_EVSE" 2 "FC_TYPE_GB" 4 "FC_TYPE_COMBO" ;
VAL_ 532 FC_statusCode 0 "FC_STATUS_NOTREADY_SNA" 2 "FC_STATUS_UPDATE_IN_PROGRESS" 1 "FC_STATUS_READY" 15 "FC_STATUS_NODATA" 14 "FC_STATUS_MALFUNCTION" 6 "FC_STATUS_EXT_ISOACTIVE" 3 "FC_STATUS_UNUSED_3" 5 "FC_STATUS_INT_ISOACTIVE" 7 "FC_STATUS_POST_OUT_OF_SERVICE" 13 "FC_STATUS_NOTCOMPATIBLE" 4 "FC_STATUS_WAIT_POST_READY_TO_CHARGE" ;
VAL_ 886 DI_inverterTQF 2 "INVERTERT_RATIONAL" 3 "INVERTERT_UNKNOWN" 0 "INVERTERT_INIT" 1 "INVERTERT_IRRATIONAL" ;
